AUTOSAR XML (schema 4-2-1)
package /VehicleProject
  system System
package /TP
  lin tp config LIN00: communication-cluster=LIN00
    tp address TA_0x0001: tp-address=1
    tp address TA_0x0003: tp-address=3
    tp address TA_0x007E: tp-address=126
    tp-connections:
      data-pdu=MasterReq_Tp_oLIN00, lin-tp-n-sdu=MasterReq_oLIN00, multicast=TA_0x007E, receiver=[TN_0x0001_SRU3, TN_0x0003_LRU1], transmitter=TN_Master
      data-pdu=SlaveResp_Tp_oLIN00, flow-control=MasterReq_Tp_oLIN00, lin-tp-n-sdu=SlaveResp_SRU3_oLIN00, receiver=TN_Master, transmitter=TN_0x0001_SRU3
      data-pdu=SlaveResp_Tp_oLIN00, flow-control=MasterReq_Tp_oLIN00, lin-tp-n-sdu=SlaveResp_LRU1_oLIN00, receiver=TN_Master, transmitter=TN_0x0003_LRU1
      data-pdu=MasterReq_Tp_oLIN00, flow-control=SlaveResp_Tp_oLIN00, lin-tp-n-sdu=MasterReq_SRU3_oLIN00, receiver=TN_0x0001_SRU3, transmitter=TN_Master
      data-pdu=MasterReq_Tp_oLIN00, flow-control=SlaveResp_Tp_oLIN00, lin-tp-n-sdu=MasterReq_LRU1_oLIN00, receiver=TN_0x0003_LRU1, transmitter=TN_Master
    lin tp node TN_0x0001_SRU3: tp-address=TA_0x0001
    lin tp node TN_0x0003_LRU1: tp-address=TA_0x0003
    lin tp node TN_Master: connector=CN_LIN00
package /Cluster
  can cluster CAN00: protocol-name=CAN  # 180319-lh1-EP21P2P_P2P_CAN2-V09
    can physical channel CHNL: comm-connectors=CN_CAN00
      frame DIAG_DTCInfo_P2P_oCAN00: id 0x79E, from P2P, frame-length=7, can-addressing-mode=STANDARD
        pdu DIAG_DTCInfo_P2P_oCAN00: length=7, unused-bit-pattern=0
          signal DTCInfomationP2PHSC2_oDIAG_DTCInfo_P2P_oCAN00: start 0, 56 bit, opaque, init-value=7 x 0, base-type=uint8_7_iso_8859_1, compu-method=CM_DTCInfomationP2PHSC2, transfer-property=PENDING  # DTC Infomation of P2P The length of DTC information signal is 7 bytes. Byte 0 is MSB (most significant byte), and Byte 6 is LSB (least significant byte). For each byte, Bit 7 is msb (most significant bit), and Bit 0 is lsb (least significant bit). Byte 0: Bit (7-4): DTC Serious Level Bit (3-0): Reserved Byte 1: Bit (7-0): Reserved Byte 2: Bit (7-0): DTCHighByte Byte 3: Bit (7-0): DTCLowByte Byte 4: Bit (7-0): DTCFailureTypeByte Byte 5: Bit 7: warningIndicatorRequested Bit 6: testNotCompletedThisOperationCycle Bit 5: testFailedSinceLastClear Bit 4: testNotCompletedSinceLastClear Bit 3: confirmedDTC Bit 2: pendingDTC Bit 1: testFailedThisOperationCycle Bit 0: testFailed Byte 6: Bit (7-0): DTC Type For more detail, please refer to SMTC 2 800 004.
      frame DIAG_FuncReq_HSC2_oCAN00: id 0x7DF, to P2P, frame-length=8, can-addressing-mode=STANDARD
        pdu DIAG_FuncReq_HSC2_oCAN00: length=8, unused-bit-pattern=0
          signal DiagnosticFuncAddrReq_h2_oDIAG_FuncReq_HSC2_oCAN00: start 0, 64 bit, opaque, init-value=8 x 0, base-type=uint8_8_iso_8859_1, compu-method=CM_DiagnosticFuncAddrReq_h2, transfer-property=PENDING, to P2P  # Diagnostic functional address request
      frame DIAG_PhysReq_P2P_oCAN00: id 0x736, to P2P, frame-length=8, can-addressing-mode=STANDARD
        pdu DIAG_PhysReq_P2P_oCAN00: length=8, unused-bit-pattern=0
          signal DiagnosticReqP2P_h2_oDIAG_PhysReq_P2P_oCAN00: start 0, 64 bit, opaque, init-value=8 x 0, base-type=uint8_8_iso_8859_1, compu-method=CM_DiagnosticReqP2P_h2, transfer-property=PENDING, to P2P  # Diagnostic request to P2P
      frame DIAG_PhysResp_P2P_oCAN00: id 0x73E, from P2P, frame-length=8, can-addressing-mode=STANDARD
        pdu DIAG_PhysResp_P2P_oCAN00: length=8, unused-bit-pattern=0
          signal DiagnosticRespP2P_oDIAG_PhysResp_P2P_oCAN00: start 0, 64 bit, opaque, init-value=8 x 0, base-type=uint8_8_iso_8859_1, compu-method=CM_DiagnosticRespP2P, transfer-property=PENDING  # Diagnostic response from P2P
      frame EHBS_HSC2_FrP00_oCAN00: id 0x1B6, to P2P, frame-length=8, can-addressing-mode=STANDARD
        pdu EHBS_HSC2_FrP00_oCAN00: length=8, transmission-mode-false-timing=cyclic-timing=time-period=0, transmission-mode-true-timing=cyclic-timing=time-period=0, unused-bit-pattern=0
          signal BrkPdlAppdHSC2_oEHBS_HSC2_FrP00_oCAN00: start 10, 1 bit, big-endian, init-value=0, base-type=boolean, compu-method=CM_BrkPdlAppdHSC2, transfer-property=PENDING, to P2P
          signal HydBstrCmpstnReqHSC2_oEHBS_HSC2_FrP00_oCAN00: start 54, 1 bit, big-endian, init-value=0, base-type=boolean, compu-method=CM_HydBstrCmpstnReqHSC2, transfer-property=PENDING, to P2P
      frame EPB_HSC2_FrP00_oCAN00: id 0x230, to P2P, frame-length=8, can-addressing-mode=STANDARD
        pdu EPB_HSC2_FrP00_oCAN00: length=8, transmission-mode-false-timing=cyclic-timing=time-period=0, transmission-mode-true-timing=cyclic-timing=time-period=0, unused-bit-pattern=0
          signal EPBSwStsVHSC2_oEPB_HSC2_FrP00_oCAN00: start 5, 1 bit, big-endian, init-value=0, base-type=boolean, compu-method=CM_EPBSwStsVHSC2, transfer-property=PENDING, to P2P
          signal EPBSwStsHSC2_oEPB_HSC2_FrP00_oCAN00: start 7, 2 bit, big-endian, init-value=0, base-type=uint8, compu-method=CM_EPBSwStsHSC2, transfer-property=PENDING, to P2P
      frame EPB_HSC2_FrP01_oCAN00: id 0x22A, to P2P, frame-length=2, can-addressing-mode=STANDARD
        pdu EPB_HSC2_FrP01_oCAN00: length=2, transmission-mode-false-timing=cyclic-timing=time-period=0, transmission-mode-true-timing=cyclic-timing=time-period=0, unused-bit-pattern=0
          signal EPBAvlblyStsPVHSC2_oEPB_HSC2_FrP01_oCAN00: start 2, 3 bit, big-endian, init-value=0, base-type=uint8, compu-method=CM_EPBAvlblyStsPVHSC2, transfer-property=PENDING, to P2P
          signal EPBAvlblyStsHSC2_oEPB_HSC2_FrP01_oCAN00: start 5, 3 bit, big-endian, init-value=0, base-type=uint8, compu-method=CM_EPBAvlblyStsHSC2, transfer-property=PENDING, to P2P
          signal EPBAppcnStsPVHSC2_oEPB_HSC2_FrP01_oCAN00: start 13, 2 bit, big-endian, init-value=0, base-type=uint8, compu-method=CM_EPBAppcnStsPVHSC2, transfer-property=PENDING, to P2P  # Electric Park Brake Application Status Protection Value
          signal EPBAppcnStsHSC2_oEPB_HSC2_FrP01_oCAN00: start 15, 2 bit, big-endian, init-value=0, base-type=uint8, compu-method=CM_EPBAppcnStsHSC2, transfer-property=PENDING, to P2P  # Electric Park Brake Application Status
      frame EPS_HSC2_FrP02_oCAN00: id 0x1B1, to P2P, frame-length=4, can-addressing-mode=STANDARD
        pdu EPS_HSC2_FrP02_oCAN00: length=4, transmission-mode-false-timing=cyclic-timing=time-period=0, transmission-mode-true-timing=cyclic-timing=time-period=0, unused-bit-pattern=0
          signal EPSAPAStsHSC2_oEPS_HSC2_FrP02_oCAN00: start 4, 4 bit, big-endian, init-value=7, base-type=uint8, compu-method=CM_EPSAPAStsHSC2, unit=U_Reserve, transfer-property=PENDING, to P2P
          signal EPSAPAInhHSC2_oEPS_HSC2_FrP02_oCAN00: start 15, 8 bit, big-endian, init-value=0, base-type=uint8, compu-method=CM_EPSAPAInhHSC2, transfer-property=PENDING, to P2P
          signal EPSAPAAlvRCHSC2_oEPS_HSC2_FrP02_oCAN00: start 23, 8 bit, big-endian, init-value=0, base-type=uint8, compu-method=CM_EPSAPAAlvRCHSC2, transfer-property=PENDING, to P2P
          signal EPSAPAChksmHSC2_oEPS_HSC2_FrP02_oCAN00: start 31, 8 bit, big-endian, init-value=0, base-type=uint8, compu-method=CM_EPSAPAChksmHSC2, transfer-property=PENDING, to P2P
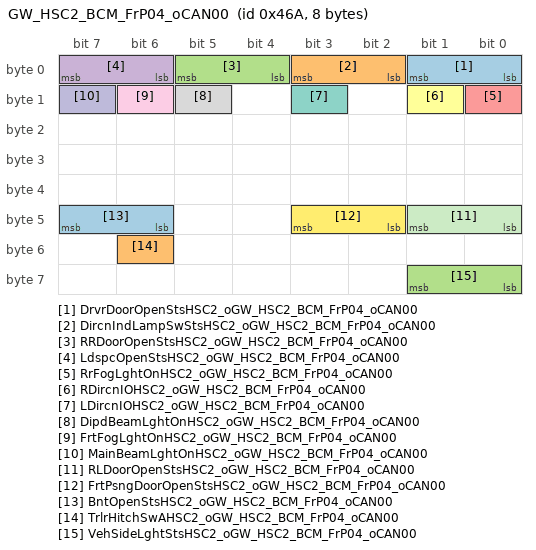
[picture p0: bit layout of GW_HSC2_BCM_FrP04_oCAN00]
      frame GW_HSC2_BCM_FrP04_oCAN00: id 0x46A, to P2P, frame-length=8, can-addressing-mode=STANDARD
        pdu GW_HSC2_BCM_FrP04_oCAN00: length=8, transmission-mode-false-timing=cyclic-timing=time-period=0, transmission-mode-true-timing=cyclic-timing=time-period=0, unused-bit-pattern=0
          signal DrvrDoorOpenStsHSC2_oGW_HSC2_BCM_FrP04_oCAN00: start 1, 2 bit, big-endian, init-value=0, base-type=uint8, compu-method=CM_DrvrDoorOpenStsHSC2, transfer-property=PENDING, to P2P
          signal DircnIndLampSwStsHSC2_oGW_HSC2_BCM_FrP04_oCAN00: start 3, 2 bit, big-endian, init-value=0, base-type=uint8, compu-method=CM_DircnIndLampSwStsHSC2, transfer-property=PENDING, to P2P
          signal RRDoorOpenStsHSC2_oGW_HSC2_BCM_FrP04_oCAN00: start 5, 2 bit, big-endian, init-value=0, base-type=uint8, compu-method=CM_RRDoorOpenStsHSC2, transfer-property=PENDING, to P2P  # Rear Right Door Open Status
          signal LdspcOpenStsHSC2_oGW_HSC2_BCM_FrP04_oCAN00: start 7, 2 bit, big-endian, init-value=0, base-type=uint8, compu-method=CM_LdspcOpenStsHSC2, transfer-property=PENDING, to P2P
          signal RrFogLghtOnHSC2_oGW_HSC2_BCM_FrP04_oCAN00: start 8, 1 bit, big-endian, init-value=0, base-type=boolean, compu-method=CM_RrFogLghtOnHSC2, transfer-property=PENDING, to P2P
          signal RDircnIOHSC2_oGW_HSC2_BCM_FrP04_oCAN00: start 9, 1 bit, big-endian, init-value=0, base-type=boolean, compu-method=CM_RDircnIOHSC2, transfer-property=PENDING, to P2P
          signal LDircnIOHSC2_oGW_HSC2_BCM_FrP04_oCAN00: start 11, 1 bit, big-endian, init-value=0, base-type=boolean, compu-method=CM_LDircnIOHSC2, transfer-property=PENDING, to P2P
          signal DipdBeamLghtOnHSC2_oGW_HSC2_BCM_FrP04_oCAN00: start 13, 1 bit, big-endian, init-value=0, base-type=boolean, compu-method=CM_DipdBeamLghtOnHSC2, transfer-property=PENDING, to P2P
          signal FrtFogLghtOnHSC2_oGW_HSC2_BCM_FrP04_oCAN00: start 14, 1 bit, big-endian, init-value=0, base-type=boolean, compu-method=CM_FrtFogLghtOnHSC2, transfer-property=PENDING, to P2P
          signal MainBeamLghtOnHSC2_oGW_HSC2_BCM_FrP04_oCAN00: start 15, 1 bit, big-endian, init-value=0, base-type=boolean, compu-method=CM_MainBeamLghtOnHSC2, transfer-property=PENDING, to P2P
          signal RLDoorOpenStsHSC2_oGW_HSC2_BCM_FrP04_oCAN00: start 41, 2 bit, big-endian, init-value=0, base-type=uint8, compu-method=CM_RLDoorOpenStsHSC2, transfer-property=PENDING, to P2P
          signal FrtPsngDoorOpenStsHSC2_oGW_HSC2_BCM_FrP04_oCAN00: start 43, 2 bit, big-endian, init-value=0, base-type=uint8, compu-method=CM_FrtPsngDoorOpenStsHSC2, transfer-property=PENDING, to P2P
          signal BntOpenStsHSC2_oGW_HSC2_BCM_FrP04_oCAN00: start 47, 2 bit, big-endian, init-value=0, base-type=uint8, compu-method=CM_BntOpenStsHSC2, transfer-property=PENDING, to P2P
          signal TrlrHitchSwAHSC2_oGW_HSC2_BCM_FrP04_oCAN00: start 54, 1 bit, big-endian, init-value=0, base-type=boolean, compu-method=CM_TrlrHitchSwAHSC2, transfer-property=PENDING, to P2P
          signal VehSideLghtStsHSC2_oGW_HSC2_BCM_FrP04_oCAN00: start 57, 2 bit, big-endian, init-value=0, base-type=uint8, compu-method=CM_VehSideLghtStsHSC2, transfer-property=PENDING, to P2P
      frame GW_HSC2_BCM_FrP06_oCAN00: id 0x21C, to P2P, frame-length=8, can-addressing-mode=STANDARD
        pdu GW_HSC2_BCM_FrP06_oCAN00: length=8, transmission-mode-false-timing=cyclic-timing=time-period=0, transmission-mode-true-timing=cyclic-timing=time-period=0, unused-bit-pattern=0
          signal BCMSSBFltStsHSC2_oGW_HSC2_BCM_FrP06_oCAN00: start 7, 3 bit, big-endian, init-value=0, base-type=uint8, compu-method=CM_BCMSSBFltStsHSC2, transfer-property=PENDING, to P2P
          signal DayTimeRunningLampOnHSC2_oGW_HSC2_BCM_FrP06_oCAN00: start 29, 1 bit, big-endian, init-value=0, base-type=boolean, compu-method=CM_DayTimeRunningLampOnHSC2, transfer-property=PENDING, to P2P
      frame GW_HSC2_BCM_FrP07_oCAN00: id 0x1F2, to P2P, frame-length=2, can-addressing-mode=STANDARD
        pdu GW_HSC2_BCM_FrP07_oCAN00: length=2, transmission-mode-false-timing=cyclic-timing=time-period=0, transmission-mode-true-timing=cyclic-timing=time-period=0, unused-bit-pattern=0
          signal BCMSSBAHSC2_oGW_HSC2_BCM_FrP07_oCAN00: start 0, 1 bit, big-endian, init-value=0, base-type=boolean, compu-method=CM_BCMSSBAHSC2, transfer-property=PENDING, to P2P
          signal BCMSSBAVHSC2_oGW_HSC2_BCM_FrP07_oCAN00: start 1, 1 bit, big-endian, init-value=0, base-type=boolean, compu-method=CM_BCMSSBAVHSC2, transfer-property=PENDING, to P2P
          signal PwrMdAutoCtrlAvlblHSC2_oGW_HSC2_BCM_FrP07_oCAN00: start 2, 1 bit, big-endian, init-value=0, base-type=boolean, compu-method=CM_PwrMdAutoCtrlAvlblHSC2, transfer-property=PENDING, to P2P
          signal SysBPMHSC2_oGW_HSC2_BCM_FrP07_oCAN00: start 5, 2 bit, big-endian, init-value=0, base-type=uint8, compu-method=CM_SysBPMHSC2, transfer-property=PENDING, to P2P
          signal SysBPMEnbdHSC2_oGW_HSC2_BCM_FrP07_oCAN00: start 6, 1 bit, big-endian, init-value=0, base-type=boolean, compu-method=CM_SysBPMEnbdHSC2, transfer-property=PENDING, to P2P
      frame GW_HSC2_BCM_FrS16_oCAN00: id 0x603, to P2P, frame-length=8, can-addressing-mode=STANDARD
        pdu GW_HSC2_BCM_FrS16_oCAN00: length=8, unused-bit-pattern=0
          signal BCMToIECURmtCtrlPotclHSC2_oGW_HSC2_BCM_FrS16_oCAN00: start 0, 64 bit, opaque, init-value=8 x 0, base-type=uint8_8_iso_8859_1, compu-method=CM_BCMToIECURmtCtrlPotclHSC2, transfer-property=PENDING, to P2P
      frame GW_HSC2_ECM_FrP04_oCAN00: id 0x194, to P2P, frame-length=8, can-addressing-mode=STANDARD
        pdu GW_HSC2_ECM_FrP04_oCAN00: length=8, transmission-mode-false-timing=cyclic-timing=time-period=0, transmission-mode-true-timing=cyclic-timing=time-period=0, unused-bit-pattern=0
          signal TrShftLvrPos_h1HSC2_oGW_HSC2_ECM_FrP04_oCAN00: start 27, 4 bit, big-endian, init-value=0, base-type=uint8, compu-method=CM_TrShftLvrPos_h1HSC2, transfer-property=PENDING, to P2P
          signal TrShftLvrPosV_h1HSC2_oGW_HSC2_ECM_FrP04_oCAN00: start 28, 1 bit, big-endian, init-value=0, base-type=boolean, compu-method=CM_TrShftLvrPosV_h1HSC2, transfer-property=PENDING, to P2P
      frame GW_HSC2_FICM_FrP02_oCAN00: id 0x376, to P2P, frame-length=8, can-addressing-mode=STANDARD
        pdu GW_HSC2_FICM_FrP02_oCAN00: length=8, transmission-mode-false-timing=cyclic-timing=time-period=0, transmission-mode-true-timing=cyclic-timing=time-period=0, unused-bit-pattern=0
          signal DrvrSelAPAParkngMdHSC2_oGW_HSC2_FICM_FrP02_oCAN00: start 10, 3 bit, big-endian, init-value=0, base-type=uint8, compu-method=CM_DrvrSelAPAParkngMdHSC2, transfer-property=PENDING, to P2P  # Driver Select Advanced Park Assist Parking Mode
          signal DrvrSelAPASlotBearngHSC2_oGW_HSC2_FICM_FrP02_oCAN00: start 12, 2 bit, big-endian, init-value=0, base-type=uint8, compu-method=CM_DrvrSelAPASlotBearngHSC2, transfer-property=PENDING, to P2P
          signal RstrFctryDeftsReqHSC2_oGW_HSC2_FICM_FrP02_oCAN00: start 56, 1 bit, big-endian, init-value=0, base-type=boolean, compu-method=CM_RstrFctryDeftsReqHSC2, transfer-property=PENDING, to P2P
      frame GW_HSC2_FICM_FrP08_oCAN00: id 0x2F6, to P2P, frame-length=8, can-addressing-mode=STANDARD
        pdu GW_HSC2_FICM_FrP08_oCAN00: length=8, transmission-mode-false-timing=cyclic-timing=time-period=0, transmission-mode-true-timing=cyclic-timing=time-period=0, unused-bit-pattern=0
          signal APASwReqHSC2_oGW_HSC2_FICM_FrP08_oCAN00: start 59, 2 bit, big-endian, init-value=0, base-type=uint8, compu-method=CM_APASwReqHSC2, transfer-property=PENDING, to P2P
          signal PDCSwReqHSC2_oGW_HSC2_FICM_FrP08_oCAN00: start 61, 2 bit, big-endian, init-value=0, base-type=uint8, compu-method=CM_PDCSwReqHSC2, transfer-property=PENDING, to P2P
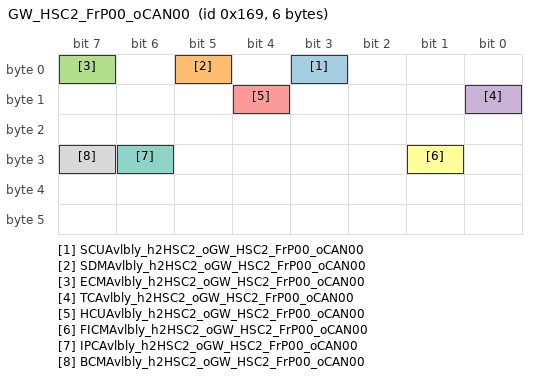
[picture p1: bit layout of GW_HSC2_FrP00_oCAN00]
      frame GW_HSC2_FrP00_oCAN00: id 0x169, to P2P, frame-length=6, can-addressing-mode=STANDARD
        pdu GW_HSC2_FrP00_oCAN00: length=6, transmission-mode-false-timing=cyclic-timing=time-period=0, transmission-mode-true-timing=cyclic-timing=time-period=0, unused-bit-pattern=0
          signal SCUAvlbly_h2HSC2_oGW_HSC2_FrP00_oCAN00: start 3, 1 bit, big-endian, init-value=0, base-type=boolean, compu-method=CM_SCUAvlbly_h2HSC2, transfer-property=PENDING, to P2P
          signal SDMAvlbly_h2HSC2_oGW_HSC2_FrP00_oCAN00: start 5, 1 bit, big-endian, init-value=0, base-type=boolean, compu-method=CM_SDMAvlbly_h2HSC2, transfer-property=PENDING, to P2P
          signal ECMAvlbly_h2HSC2_oGW_HSC2_FrP00_oCAN00: start 7, 1 bit, big-endian, init-value=0, base-type=boolean, compu-method=CM_ECMAvlbly_h2HSC2, transfer-property=PENDING, to P2P
          signal TCAvlbly_h2HSC2_oGW_HSC2_FrP00_oCAN00: start 8, 1 bit, big-endian, init-value=0, base-type=boolean, compu-method=CM_TCAvlbly_h2HSC2, transfer-property=PENDING, to P2P  # TC Available Detect if specific ECU is available according to node missing strategy by gateway ECU.
          signal HCUAvlbly_h2HSC2_oGW_HSC2_FrP00_oCAN00: start 12, 1 bit, big-endian, init-value=0, base-type=boolean, compu-method=CM_HCUAvlbly_h2HSC2, transfer-property=PENDING, to P2P  # HCU Available Detect if specific ECU is available according to node missing strategy by gateway ECU.
          signal FICMAvlbly_h2HSC2_oGW_HSC2_FrP00_oCAN00: start 25, 1 bit, big-endian, init-value=0, base-type=boolean, compu-method=CM_FICMAvlbly_h2HSC2, transfer-property=PENDING, to P2P
          signal IPCAvlbly_h2HSC2_oGW_HSC2_FrP00_oCAN00: start 30, 1 bit, big-endian, init-value=0, base-type=boolean, compu-method=CM_IPCAvlbly_h2HSC2, transfer-property=PENDING, to P2P
          signal BCMAvlbly_h2HSC2_oGW_HSC2_FrP00_oCAN00: start 31, 1 bit, big-endian, init-value=0, base-type=boolean, compu-method=CM_BCMAvlbly_h2HSC2, transfer-property=PENDING, to P2P
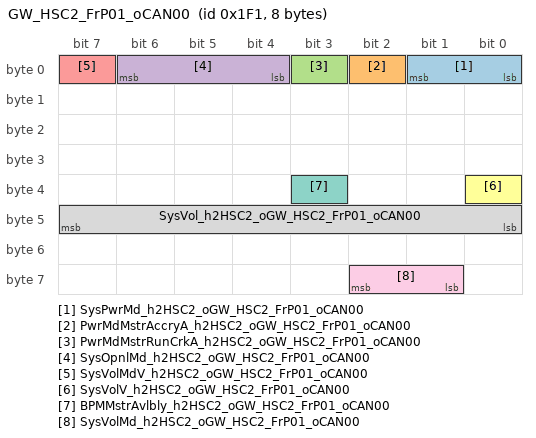
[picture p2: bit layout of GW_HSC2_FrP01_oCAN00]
      frame GW_HSC2_FrP01_oCAN00: id 0x1F1, to P2P, frame-length=8, can-addressing-mode=STANDARD
        pdu GW_HSC2_FrP01_oCAN00: length=8, transmission-mode-false-timing=cyclic-timing=time-period=0, transmission-mode-true-timing=cyclic-timing=time-period=0, unused-bit-pattern=0
          signal SysPwrMd_h2HSC2_oGW_HSC2_FrP01_oCAN00: start 1, 2 bit, big-endian, init-value=0, base-type=uint8, compu-method=CM_SysPwrMd_h2HSC2, transfer-property=PENDING, to P2P
          signal PwrMdMstrAccryA_h2HSC2_oGW_HSC2_FrP01_oCAN00: start 2, 1 bit, big-endian, init-value=0, base-type=boolean, compu-method=CM_PwrMdMstrAccryA_h2HSC2, transfer-property=PENDING, to P2P
          signal PwrMdMstrRunCrkA_h2HSC2_oGW_HSC2_FrP01_oCAN00: start 3, 1 bit, big-endian, init-value=0, base-type=boolean, compu-method=CM_PwrMdMstrRunCrkA_h2HSC2, transfer-property=PENDING, to P2P
          signal SysOpnlMd_h2HSC2_oGW_HSC2_FrP01_oCAN00: start 6, 3 bit, big-endian, init-value=0, base-type=uint8, compu-method=CM_SysOpnlMd_h2HSC2, transfer-property=PENDING, to P2P
          signal SysVolMdV_h2HSC2_oGW_HSC2_FrP01_oCAN00: start 7, 1 bit, big-endian, init-value=0, base-type=boolean, compu-method=CM_SysVolMdV_h2HSC2, transfer-property=PENDING, to P2P
          signal SysVolV_h2HSC2_oGW_HSC2_FrP01_oCAN00: start 32, 1 bit, big-endian, init-value=0, base-type=boolean, compu-method=CM_SysVolV_h2HSC2, transfer-property=PENDING, to P2P
          signal BPMMstrAvlbly_h2HSC2_oGW_HSC2_FrP01_oCAN00: start 35, 1 bit, big-endian, init-value=0, base-type=boolean, compu-method=CM_BPMMstrAvlbly_h2HSC2, transfer-property=PENDING, to P2P
          signal SysVol_h2HSC2_oGW_HSC2_FrP01_oCAN00: start 47, 8 bit, big-endian, init-value=0, base-type=uint8, compu-method=CM_SysVol_h2HSC2, unit=U_V, transfer-property=PENDING, to P2P
          signal SysVolMd_h2HSC2_oGW_HSC2_FrP01_oCAN00: start 58, 2 bit, big-endian, init-value=0, base-type=uint8, compu-method=CM_SysVolMd_h2HSC2, transfer-property=PENDING, to P2P
      frame GW_HSC2_FrP08_oCAN00: id 0x540, to P2P, frame-length=8, can-addressing-mode=STANDARD
        pdu GW_HSC2_FrP08_oCAN00: length=8, transmission-mode-false-timing=cyclic-timing=time-period=0, transmission-mode-true-timing=cyclic-timing=time-period=0, unused-bit-pattern=0
          signal VehOdo_h2HSC2_oGW_HSC2_FrP08_oCAN00: start 7, 24 bit, big-endian, init-value=0, base-type=uint32, compu-method=CM_VehOdo_h2HSC2, transfer-property=PENDING, to P2P
          signal VehOdoV_h2HSC2_oGW_HSC2_FrP08_oCAN00: start 31, 1 bit, big-endian, init-value=0, base-type=boolean, compu-method=CM_VehOdoV_h2HSC2, transfer-property=PENDING, to P2P
      frame GW_HSC2_FrP10_oCAN00: id 0x3F1, to P2P, frame-length=8, can-addressing-mode=STANDARD
        pdu GW_HSC2_FrP10_oCAN00: length=8, transmission-mode-false-timing=cyclic-timing=time-period=0, transmission-mode-true-timing=cyclic-timing=time-period=0, unused-bit-pattern=0
          signal OtsdAirTemCrValV_h2HSC2_oGW_HSC2_FrP10_oCAN00: start 48, 1 bit, big-endian, init-value=0, base-type=boolean, compu-method=CM_OtsdAirTemCrValV_h2HSC2, transfer-property=PENDING, to P2P
          signal OtsdAirTemCrValMsk_h2HSC2_oGW_HSC2_FrP10_oCAN00: start 51, 1 bit, big-endian, init-value=0, base-type=boolean, compu-method=CM_OtsdAirTemCrValMsk_h2HSC2, transfer-property=PENDING, to P2P
          signal OtsdAirTemCrVal_h2HSC2_oGW_HSC2_FrP10_oCAN00: start 63, 8 bit, big-endian, init-value=0, base-type=uint8, compu-method=CM_OtsdAirTemCrVal_h2HSC2, unit=U_degC, transfer-property=PENDING, to P2P
      frame GW_HSC2_FrP13_oCAN00: id 0x1A9, to P2P, frame-length=8, can-addressing-mode=STANDARD
        pdu GW_HSC2_FrP13_oCAN00: length=8, transmission-mode-false-timing=cyclic-timing=time-period=0, transmission-mode-true-timing=cyclic-timing=time-period=0, unused-bit-pattern=0
          signal NRCDSts_h2HSC2_oGW_HSC2_FrP13_oCAN00: start 39, 2 bit, big-endian, init-value=0, base-type=uint8, compu-method=CM_NRCDSts_h2HSC2, transfer-property=PENDING, to P2P
          signal APACtrlAbotdRsnHSC2_oGW_HSC2_FrP13_oCAN00: start 47, 4 bit, big-endian, init-value=0, base-type=uint8, compu-method=CM_APACtrlAbotdRsnHSC2, transfer-property=PENDING, to P2P
      frame GW_HSC2_FrS00_oCAN00: id 0x6A3, to P2P, frame-length=8, can-addressing-mode=STANDARD
        pdu GW_HSC2_FrS00_oCAN00: length=8, unused-bit-pattern=0
          signal NRCDMstrChlg_h2HSC2_oGW_HSC2_FrS00_oCAN00: start 0, 64 bit, opaque, init-value=8 x 0, base-type=uint8_8_iso_8859_1, compu-method=CM_NRCDMstrChlg_h2HSC2, transfer-property=PENDING, to P2P
      frame GW_HSC2_HCU_FrP00_oCAN00: id 0xAF, to P2P, frame-length=8, can-addressing-mode=STANDARD
        pdu GW_HSC2_HCU_FrP00_oCAN00: length=8, transmission-mode-false-timing=cyclic-timing=time-period=0, transmission-mode-true-timing=cyclic-timing=time-period=0, unused-bit-pattern=0
          signal EPTAccelActuPosHSC2_oGW_HSC2_HCU_FrP00_oCAN00: start 7, 8 bit, big-endian, init-value=0, base-type=uint8, compu-method=CM_EPTAccelActuPosHSC2, unit=U_p, transfer-property=PENDING, to P2P
          signal EPTBrkPdlDscrtInptStsVHSC2_oGW_HSC2_HCU_FrP00_oCAN00: start 16, 1 bit, big-endian, init-value=1, base-type=boolean, compu-method=CM_EPTBrkPdlDscrtInptStsVHSC2, transfer-property=PENDING, to P2P  # Electric Powertrain Brake Pedal Discrete Input Status Validity
          signal EPTStCmdOn_h1HSC2_oGW_HSC2_HCU_FrP00_oCAN00: start 17, 1 bit, big-endian, init-value=0, base-type=boolean, compu-method=CM_EPTStCmdOn_h1HSC2, transfer-property=PENDING, to P2P
          signal EPTBrkPdlDscrtInptStsHSC2_oGW_HSC2_HCU_FrP00_oCAN00: start 31, 1 bit, big-endian, init-value=0, base-type=boolean, compu-method=CM_EPTBrkPdlDscrtInptStsHSC2, transfer-property=PENDING, to P2P
          signal EPTAccelActuPosVHSC2_oGW_HSC2_HCU_FrP00_oCAN00: start 43, 1 bit, big-endian, init-value=0, base-type=boolean, compu-method=CM_EPTAccelActuPosVHSC2, transfer-property=PENDING, to P2P
      frame GW_HSC2_HCU_FrP01_oCAN00: id 0x196, to P2P, frame-length=8, can-addressing-mode=STANDARD
        pdu GW_HSC2_HCU_FrP01_oCAN00: length=8, transmission-mode-false-timing=cyclic-timing=time-period=0, transmission-mode-true-timing=cyclic-timing=time-period=0, unused-bit-pattern=0
          signal EPTRdy_h1HSC2_oGW_HSC2_HCU_FrP01_oCAN00: start 38, 1 bit, big-endian, init-value=0, base-type=boolean, compu-method=CM_EPTRdy_h1HSC2, transfer-property=PENDING, to P2P
      frame GW_HSC2_HCU_FrP13_oCAN00: id 0x19C, to P2P, frame-length=8, can-addressing-mode=STANDARD
        pdu GW_HSC2_HCU_FrP13_oCAN00: length=8, transmission-mode-false-timing=cyclic-timing=time-period=0, transmission-mode-true-timing=cyclic-timing=time-period=0, unused-bit-pattern=0
          signal VCUNRCDAvlblHSC2_oGW_HSC2_HCU_FrP13_oCAN00: start 52, 1 bit, big-endian, init-value=0, base-type=boolean, compu-method=CM_VCUNRCDAvlblHSC2, transfer-property=PENDING, to P2P
          signal VCUAccReqStsHSC2_oGW_HSC2_HCU_FrP13_oCAN00: start 53, 1 bit, big-endian, init-value=0, base-type=boolean, compu-method=CM_VCUAccReqStsHSC2, transfer-property=PENDING, to P2P
          signal VCUAccReqValHSC2_oGW_HSC2_HCU_FrP13_oCAN00: start 63, 8 bit, big-endian, init-value=0, base-type=uint8, compu-method=CM_VCUAccReqValHSC2, transfer-property=PENDING, to P2P
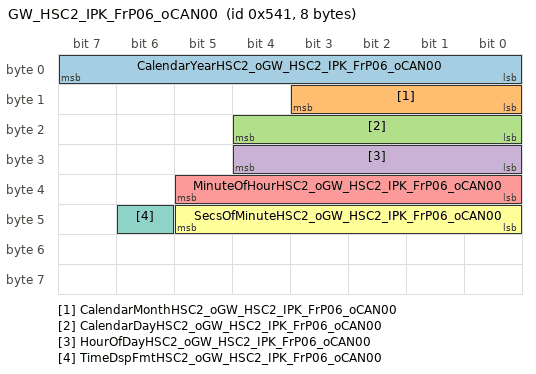
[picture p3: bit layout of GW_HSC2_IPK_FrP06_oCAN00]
      frame GW_HSC2_IPK_FrP06_oCAN00: id 0x541, to P2P, frame-length=8, can-addressing-mode=STANDARD
        pdu GW_HSC2_IPK_FrP06_oCAN00: length=8, transmission-mode-false-timing=cyclic-timing=time-period=0, transmission-mode-true-timing=cyclic-timing=time-period=0, unused-bit-pattern=0
          signal CalendarYearHSC2_oGW_HSC2_IPK_FrP06_oCAN00: start 7, 8 bit, big-endian, init-value=0, base-type=uint8, compu-method=CM_CalendarYearHSC2, unit=U_year, transfer-property=PENDING, to P2P
          signal CalendarMonthHSC2_oGW_HSC2_IPK_FrP06_oCAN00: start 11, 4 bit, big-endian, init-value=0, base-type=uint8, compu-method=CM_CalendarMonthHSC2, transfer-property=PENDING, to P2P
          signal CalendarDayHSC2_oGW_HSC2_IPK_FrP06_oCAN00: start 20, 5 bit, big-endian, init-value=0, base-type=uint8, compu-method=CM_CalendarDayHSC2, unit=U_days, transfer-property=PENDING, to P2P
          signal HourOfDayHSC2_oGW_HSC2_IPK_FrP06_oCAN00: start 28, 5 bit, big-endian, init-value=0, base-type=uint8, compu-method=CM_HourOfDayHSC2, transfer-property=PENDING, to P2P
          signal MinuteOfHourHSC2_oGW_HSC2_IPK_FrP06_oCAN00: start 37, 6 bit, big-endian, init-value=0, base-type=uint8, compu-method=CM_MinuteOfHourHSC2, transfer-property=PENDING, to P2P
          signal SecsOfMinuteHSC2_oGW_HSC2_IPK_FrP06_oCAN00: start 45, 6 bit, big-endian, init-value=0, base-type=uint8, compu-method=CM_SecsOfMinuteHSC2, transfer-property=PENDING, to P2P
          signal TimeDspFmtHSC2_oGW_HSC2_IPK_FrP06_oCAN00: start 46, 1 bit, big-endian, init-value=0, base-type=boolean, compu-method=CM_TimeDspFmtHSC2, transfer-property=PENDING, to P2P
      frame GW_HSC2_SCU_FrP00_oCAN00: id 0x9D, to P2P, frame-length=8, can-addressing-mode=STANDARD
        pdu GW_HSC2_SCU_FrP00_oCAN00: length=8, transmission-mode-false-timing=cyclic-timing=time-period=0, transmission-mode-true-timing=cyclic-timing=time-period=0, unused-bit-pattern=0
          signal SCUDrvrIntrvnAHSC2_oGW_HSC2_SCU_FrP00_oCAN00: start 2, 1 bit, big-endian, init-value=0, base-type=boolean, compu-method=CM_SCUDrvrIntrvnAHSC2, transfer-property=PENDING, to P2P
          signal SCUNRCDAvlblHSC2_oGW_HSC2_SCU_FrP00_oCAN00: start 3, 1 bit, big-endian, init-value=0, base-type=boolean, compu-method=CM_SCUNRCDAvlblHSC2, transfer-property=PENDING, to P2P
          signal SCUShifterPosRCHSC2_oGW_HSC2_SCU_FrP00_oCAN00: start 11, 4 bit, big-endian, init-value=0, base-type=uint8, compu-method=CM_SCUShifterPosRCHSC2, transfer-property=PENDING, to P2P
          signal SCUShifterLvrPosHSC2_oGW_HSC2_SCU_FrP00_oCAN00: start 23, 4 bit, big-endian, init-value=0, base-type=uint8, compu-method=CM_SCUShifterLvrPosHSC2, transfer-property=PENDING, to P2P
          signal SCUShifterPosInvsnHSC2_oGW_HSC2_SCU_FrP00_oCAN00: start 31, 4 bit, big-endian, init-value=15, base-type=uint8, compu-method=CM_SCUShifterPosInvsnHSC2, transfer-property=PENDING, to P2P
      frame GW_HSC2_SDM_FrP00_oCAN00: id 0x163, to P2P, frame-length=8, can-addressing-mode=STANDARD
        pdu GW_HSC2_SDM_FrP00_oCAN00: length=8, transmission-mode-false-timing=cyclic-timing=time-period=0, transmission-mode-true-timing=cyclic-timing=time-period=0, unused-bit-pattern=0
          signal AirbagDplInvsnHSC2_oGW_HSC2_SDM_FrP00_oCAN00: start 10, 1 bit, big-endian, init-value=1, base-type=boolean, compu-method=CM_AirbagDplInvsnHSC2, transfer-property=PENDING, to P2P  # Airbag Deployed Inversion
          signal AirbagDplHSC2_oGW_HSC2_SDM_FrP00_oCAN00: start 11, 1 bit, big-endian, init-value=0, base-type=boolean, compu-method=CM_AirbagDplHSC2, transfer-property=PENDING, to P2P
          signal DrvrSbltAtcHSC2_oGW_HSC2_SDM_FrP00_oCAN00: start 12, 1 bit, big-endian, init-value=0, base-type=boolean, compu-method=CM_DrvrSbltAtcHSC2, transfer-property=PENDING, to P2P
          signal DrvrSbltAtcVHSC2_oGW_HSC2_SDM_FrP00_oCAN00: start 13, 1 bit, big-endian, init-value=0, base-type=boolean, compu-method=CM_DrvrSbltAtcVHSC2, transfer-property=PENDING, to P2P
      frame P2P_DIAG_DTCInfo_APA_oCAN00: id 0x799, from P2P, frame-length=7, can-addressing-mode=STANDARD
        pdu P2P_DIAG_DTCInfo_APA_oCAN00: length=7, unused-bit-pattern=0
          signal DTCInfomationAPAHSC2_oP2P_DIAG_DTCInfo_APA_oCAN00: start 0, 56 bit, opaque, init-value=7 x 0, base-type=uint8_7_iso_8859_1, compu-method=CM_DTCInfomationAPAHSC2, transfer-property=PENDING  # DTC Infomation of APA The length of DTC information signal is 7 bytes. Byte 0 is MSB (most significant byte), and Byte 6 is LSB (least significant byte). For each byte, Bit 7 is msb (most significant bit), and Bit 0 is lsb (least significant bit). Byte 0: Bit (7-4): DTC Serious Level Bit (3-0): Reserved Byte 1: Bit (7-0): Reserved Byte 2: Bit (7-0): DTCHighByte Byte 3: Bit (7-0): DTCLowByte Byte 4: Bit (7-0): DTCFailureTypeByte Byte 5: Bit 7: warningIndicatorRequested Bit 6: testNotCompletedThisOperationCycle Bit 5: testFailedSinceLastClear Bit 4: testNotCompletedSinceLastClear Bit 3: confirmedDTC Bit 2: pendingDTC Bit 1: testFailedThisOperationCycle Bit 0: testFailed Byte 6: Bit (7-0): DTC Type For more detail, please refer to SMTC 2 800 004.
      frame P2P_HSC2_FrP00_oCAN00: id 0x1A8, from P2P, frame-length=6, can-addressing-mode=STANDARD
        pdu P2P_HSC2_FrP00_oCAN00: length=6, transmission-mode-false-timing=cyclic-timing=time-period=0, transmission-mode-true-timing=cyclic-timing=time-period=0, unused-bit-pattern=0
          signal APAToqReqValHSC2_oP2P_HSC2_FrP00_oCAN00: start 3, 12 bit, big-endian, init-value=0, base-type=uint16, compu-method=CM_APAToqReqValHSC2, unit=U_Nm, transfer-property=PENDING
          signal APAToqReqStsHSC2_oP2P_HSC2_FrP00_oCAN00: start 4, 1 bit, big-endian, init-value=0, base-type=boolean, compu-method=CM_APAToqReqStsHSC2, transfer-property=PENDING
          signal APAFHSC2_oP2P_HSC2_FrP00_oCAN00: start 5, 1 bit, big-endian, init-value=0, base-type=boolean, compu-method=CM_APAFHSC2, transfer-property=PENDING
          signal APACmdEPSStsHSC2_oP2P_HSC2_FrP00_oCAN00: start 7, 2 bit, big-endian, init-value=0, base-type=uint8, compu-method=CM_APACmdEPSStsHSC2, transfer-property=PENDING
          signal APATrgtEPSStrgWhlAngHSC2_oP2P_HSC2_FrP00_oCAN00: start 23, 16 bit, big-endian, init-value=0, base-type=uint16, compu-method=CM_APATrgtEPSStrgWhlAngHSC2, transfer-property=PENDING
          signal APAAlvRCHSC2_oP2P_HSC2_FrP00_oCAN00: start 39, 8 bit, big-endian, init-value=0, base-type=uint8, compu-method=CM_APAAlvRCHSC2, transfer-property=PENDING
          signal APAChksmHSC2_oP2P_HSC2_FrP00_oCAN00: start 47, 8 bit, big-endian, init-value=0, base-type=uint8, compu-method=CM_APAChksmHSC2, transfer-property=PENDING
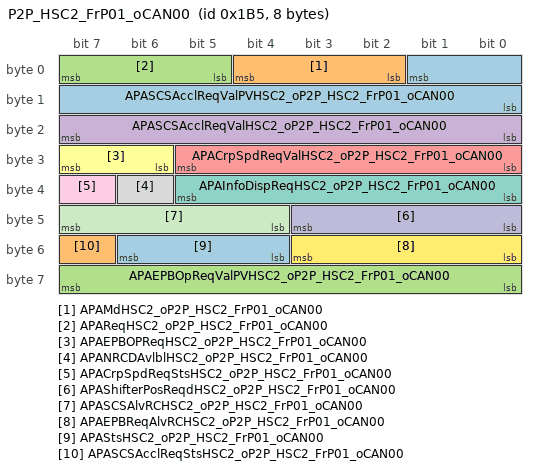
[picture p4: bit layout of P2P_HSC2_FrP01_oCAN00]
      frame P2P_HSC2_FrP01_oCAN00: id 0x1B5, from P2P, frame-length=8, can-addressing-mode=STANDARD
        pdu P2P_HSC2_FrP01_oCAN00: length=8, transmission-mode-false-timing=cyclic-timing=time-period=0, transmission-mode-true-timing=cyclic-timing=time-period=0, unused-bit-pattern=0
          signal APASCSAcclReqValPVHSC2_oP2P_HSC2_FrP01_oCAN00: start 1, 10 bit, big-endian, init-value=0, base-type=uint16, compu-method=CM_APASCSAcclReqValPVHSC2, transfer-property=PENDING
          signal APAMdHSC2_oP2P_HSC2_FrP01_oCAN00: start 4, 3 bit, big-endian, init-value=0, base-type=uint8, compu-method=CM_APAMdHSC2, transfer-property=PENDING
          signal APAReqHSC2_oP2P_HSC2_FrP01_oCAN00: start 7, 3 bit, big-endian, init-value=0, base-type=uint8, compu-method=CM_APAReqHSC2, transfer-property=PENDING
          signal APASCSAcclReqValHSC2_oP2P_HSC2_FrP01_oCAN00: start 23, 8 bit, big-endian, init-value=0, base-type=uint8, compu-method=CM_APASCSAcclReqValHSC2, unit=U_mYs2, transfer-property=PENDING
          signal APACrpSpdReqValHSC2_oP2P_HSC2_FrP01_oCAN00: start 29, 6 bit, big-endian, init-value=0, base-type=uint8, compu-method=CM_APACrpSpdReqValHSC2, unit=U_kmYh, transfer-property=PENDING
          signal APAEPBOPReqHSC2_oP2P_HSC2_FrP01_oCAN00: start 31, 2 bit, big-endian, init-value=0, base-type=uint8, compu-method=CM_APAEPBOPReqHSC2, transfer-property=PENDING
          signal APAInfoDispReqHSC2_oP2P_HSC2_FrP01_oCAN00: start 37, 6 bit, big-endian, init-value=0, base-type=uint8, compu-method=CM_APAInfoDispReqHSC2, transfer-property=PENDING
          signal APANRCDAvlblHSC2_oP2P_HSC2_FrP01_oCAN00: start 38, 1 bit, big-endian, init-value=0, base-type=boolean, compu-method=CM_APANRCDAvlblHSC2, transfer-property=PENDING  # Advanced Park Assist Near Range Control Drive Available
          signal APACrpSpdReqStsHSC2_oP2P_HSC2_FrP01_oCAN00: start 39, 1 bit, big-endian, init-value=0, base-type=boolean, compu-method=CM_APACrpSpdReqStsHSC2, transfer-property=PENDING
          signal APAShifterPosReqdHSC2_oP2P_HSC2_FrP01_oCAN00: start 43, 4 bit, big-endian, init-value=0, base-type=uint8, compu-method=CM_APAShifterPosReqdHSC2, transfer-property=PENDING
          signal APASCSAlvRCHSC2_oP2P_HSC2_FrP01_oCAN00: start 47, 4 bit, big-endian, init-value=0, base-type=uint8, compu-method=CM_APASCSAlvRCHSC2, transfer-property=PENDING
          signal APAEPBReqAlvRCHSC2_oP2P_HSC2_FrP01_oCAN00: start 51, 4 bit, big-endian, init-value=0, base-type=uint8, compu-method=CM_APAEPBReqAlvRCHSC2, transfer-property=PENDING
          signal APAStsHSC2_oP2P_HSC2_FrP01_oCAN00: start 54, 3 bit, big-endian, init-value=0, base-type=uint8, compu-method=CM_APAStsHSC2, transfer-property=PENDING
          signal APASCSAcclReqStsHSC2_oP2P_HSC2_FrP01_oCAN00: start 55, 1 bit, big-endian, init-value=0, base-type=boolean, compu-method=CM_APASCSAcclReqStsHSC2, transfer-property=PENDING
          signal APAEPBOpReqValPVHSC2_oP2P_HSC2_FrP01_oCAN00: start 63, 8 bit, big-endian, init-value=0, base-type=uint8, compu-method=CM_APAEPBOpReqValPVHSC2, transfer-property=PENDING
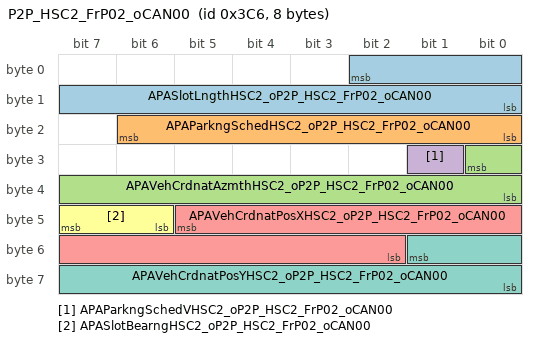
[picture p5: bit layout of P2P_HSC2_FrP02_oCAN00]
      frame P2P_HSC2_FrP02_oCAN00: id 0x3C6, from P2P, frame-length=8, can-addressing-mode=STANDARD
        pdu P2P_HSC2_FrP02_oCAN00: length=8, transmission-mode-false-timing=cyclic-timing=time-period=0, transmission-mode-true-timing=cyclic-timing=time-period=0, unused-bit-pattern=0
          signal APASlotLngthHSC2_oP2P_HSC2_FrP02_oCAN00: start 2, 11 bit, big-endian, init-value=0, base-type=uint16, compu-method=CM_APASlotLngthHSC2, unit=U_cm, transfer-property=PENDING  # Advanced Park Assist Slot Length
          signal APAParkngSchedHSC2_oP2P_HSC2_FrP02_oCAN00: start 22, 7 bit, big-endian, init-value=0, base-type=uint8, compu-method=CM_APAParkngSchedHSC2, transfer-property=PENDING  # Advanced Park Assist Parking Schedule
          signal APAVehCrdnatAzmthHSC2_oP2P_HSC2_FrP02_oCAN00: start 24, 9 bit, big-endian, init-value=0, base-type=uint16, compu-method=CM_APAVehCrdnatAzmthHSC2, transfer-property=PENDING  # Advanced Park Assist Vehicle Coordinate Azimuth
          signal APAParkngSchedVHSC2_oP2P_HSC2_FrP02_oCAN00: start 25, 1 bit, big-endian, init-value=0, base-type=boolean, compu-method=CM_APAParkngSchedVHSC2, transfer-property=PENDING  # Advanced Park Assist Parking Schedule Validit
          signal APAVehCrdnatPosXHSC2_oP2P_HSC2_FrP02_oCAN00: start 45, 12 bit, big-endian, init-value=0, base-type=uint16, compu-method=CM_APAVehCrdnatPosXHSC2, unit=U_cm, transfer-property=PENDING  # Advanced Park Assist Vehicle Coordinate Position X
          signal APASlotBearngHSC2_oP2P_HSC2_FrP02_oCAN00: start 47, 2 bit, big-endian, init-value=0, base-type=uint8, compu-method=CM_APASlotBearngHSC2, transfer-property=PENDING  # Advanced Park Assist Slot Bearing
          signal APAVehCrdnatPosYHSC2_oP2P_HSC2_FrP02_oCAN00: start 49, 10 bit, big-endian, init-value=0, base-type=uint16, compu-method=CM_APAVehCrdnatPosYHSC2, unit=U_cm, transfer-property=PENDING  # Advanced Park Assist Vehicle Coordinate Position Y
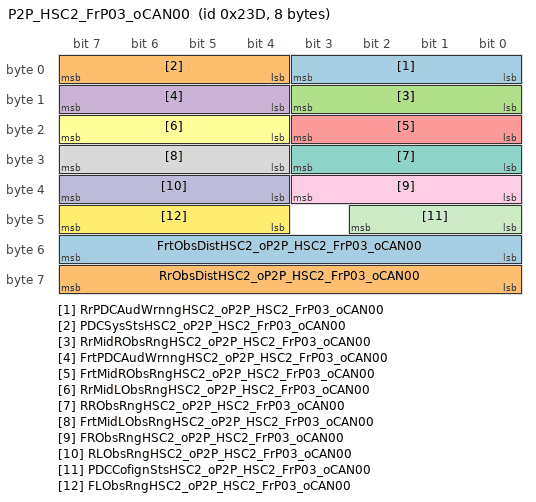
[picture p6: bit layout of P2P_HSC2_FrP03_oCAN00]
      frame P2P_HSC2_FrP03_oCAN00: id 0x23D, from P2P, frame-length=8, can-addressing-mode=STANDARD
        pdu P2P_HSC2_FrP03_oCAN00: length=8, transmission-mode-false-timing=cyclic-timing=time-period=0, transmission-mode-true-timing=cyclic-timing=time-period=0, unused-bit-pattern=0
          signal RrPDCAudWrnngHSC2_oP2P_HSC2_FrP03_oCAN00: start 3, 4 bit, big-endian, init-value=0, base-type=uint8, compu-method=CM_RrPDCAudWrnngHSC2, transfer-property=PENDING
          signal PDCSysStsHSC2_oP2P_HSC2_FrP03_oCAN00: start 7, 4 bit, big-endian, init-value=0, base-type=uint8, compu-method=CM_PDCSysStsHSC2, transfer-property=PENDING
          signal RrMidRObsRngHSC2_oP2P_HSC2_FrP03_oCAN00: start 11, 4 bit, big-endian, init-value=0, base-type=uint8, compu-method=CM_RrMidRObsRngHSC2, transfer-property=PENDING
          signal FrtPDCAudWrnngHSC2_oP2P_HSC2_FrP03_oCAN00: start 15, 4 bit, big-endian, init-value=0, base-type=uint8, compu-method=CM_FrtPDCAudWrnngHSC2, transfer-property=PENDING
          signal FrtMidRObsRngHSC2_oP2P_HSC2_FrP03_oCAN00: start 19, 4 bit, big-endian, init-value=0, base-type=uint8, compu-method=CM_FrtMidRObsRngHSC2, transfer-property=PENDING
          signal RrMidLObsRngHSC2_oP2P_HSC2_FrP03_oCAN00: start 23, 4 bit, big-endian, init-value=0, base-type=uint8, compu-method=CM_RrMidLObsRngHSC2, transfer-property=PENDING
          signal RRObsRngHSC2_oP2P_HSC2_FrP03_oCAN00: start 27, 4 bit, big-endian, init-value=0, base-type=uint8, compu-method=CM_RRObsRngHSC2, transfer-property=PENDING
          signal FrtMidLObsRngHSC2_oP2P_HSC2_FrP03_oCAN00: start 31, 4 bit, big-endian, init-value=0, base-type=uint8, compu-method=CM_FrtMidLObsRngHSC2, transfer-property=PENDING
          signal FRObsRngHSC2_oP2P_HSC2_FrP03_oCAN00: start 35, 4 bit, big-endian, init-value=0, base-type=uint8, compu-method=CM_FRObsRngHSC2, transfer-property=PENDING
          signal RLObsRngHSC2_oP2P_HSC2_FrP03_oCAN00: start 39, 4 bit, big-endian, init-value=0, base-type=uint8, compu-method=CM_RLObsRngHSC2, transfer-property=PENDING
          signal PDCCofignStsHSC2_oP2P_HSC2_FrP03_oCAN00: start 42, 3 bit, big-endian, init-value=1, base-type=uint8, compu-method=CM_PDCCofignStsHSC2, transfer-property=PENDING
          signal FLObsRngHSC2_oP2P_HSC2_FrP03_oCAN00: start 47, 4 bit, big-endian, init-value=0, base-type=uint8, compu-method=CM_FLObsRngHSC2, transfer-property=PENDING
          signal FrtObsDistHSC2_oP2P_HSC2_FrP03_oCAN00: start 55, 8 bit, big-endian, init-value=0, base-type=uint8, compu-method=CM_FrtObsDistHSC2, unit=U_cm, transfer-property=PENDING
          signal RrObsDistHSC2_oP2P_HSC2_FrP03_oCAN00: start 63, 8 bit, big-endian, init-value=0, base-type=uint8, compu-method=CM_RrObsDistHSC2, transfer-property=PENDING
      frame P2P_HSC2_FrP04_oCAN00: id 0x237, from P2P, frame-length=8, can-addressing-mode=STANDARD
        pdu P2P_HSC2_FrP04_oCAN00: length=8, transmission-mode-false-timing=cyclic-timing=time-period=0, transmission-mode-true-timing=cyclic-timing=time-period=0, unused-bit-pattern=0
          signal RRSideObsDistHSC2_oP2P_HSC2_FrP04_oCAN00: start 0, 9 bit, big-endian, init-value=0, base-type=uint16, compu-method=CM_RRSideObsDistHSC2, transfer-property=PENDING
          signal RLSideObsDistHSC2_oP2P_HSC2_FrP04_oCAN00: start 16, 9 bit, big-endian, init-value=0, base-type=uint16, compu-method=CM_RLSideObsDistHSC2, transfer-property=PENDING
          signal FRSideObsDistHSC2_oP2P_HSC2_FrP04_oCAN00: start 32, 9 bit, big-endian, init-value=0, base-type=uint16, compu-method=CM_FRSideObsDistHSC2, transfer-property=PENDING
          signal FLSideObsDistHSC2_oP2P_HSC2_FrP04_oCAN00: start 48, 9 bit, big-endian, init-value=0, base-type=uint16, compu-method=CM_FLSideObsDistHSC2, transfer-property=PENDING
      frame P2P_HSC2_FrS01_oCAN00: id 0x602, from P2P, frame-length=8, can-addressing-mode=STANDARD
        pdu P2P_HSC2_FrS01_oCAN00: length=8, unused-bit-pattern=0
          signal IECUToBCMRmtCtrlPotclHSC2_oP2P_HSC2_FrS01_oCAN00: start 0, 64 bit, opaque, init-value=8 x 0, base-type=uint8_8_iso_8859_1, compu-method=CM_IECUToBCMRmtCtrlPotclHSC2, transfer-property=PENDING
      frame SAS_HSC2_FrP00_oCAN00: id 0x1E5, to P2P, frame-length=8, can-addressing-mode=STANDARD
        pdu SAS_HSC2_FrP00_oCAN00: length=8, transmission-mode-false-timing=cyclic-timing=time-period=0, transmission-mode-true-timing=cyclic-timing=time-period=0, unused-bit-pattern=0
          signal StrgWhlAngVHSC2_oSAS_HSC2_FrP00_oCAN00: start 7, 1 bit, big-endian, init-value=0, base-type=boolean, compu-method=CM_StrgWhlAngVHSC2, transfer-property=PENDING, to P2P
          signal StrgWhlAngHSC2_oSAS_HSC2_FrP00_oCAN00: start 15, 16 bit, big-endian, init-value=0, base-type=uint16, compu-method=CM_StrgWhlAngHSC2, unit=U_degree, transfer-property=PENDING, to P2P
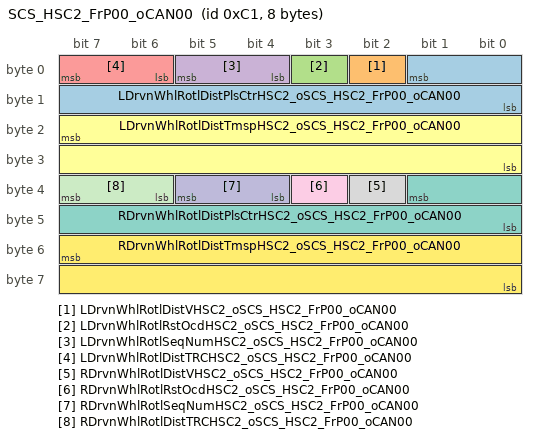
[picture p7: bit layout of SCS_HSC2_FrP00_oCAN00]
      frame SCS_HSC2_FrP00_oCAN00: id 0xC1, to P2P, frame-length=8, can-addressing-mode=STANDARD
        pdu SCS_HSC2_FrP00_oCAN00: length=8, transmission-mode-false-timing=cyclic-timing=time-period=0, transmission-mode-true-timing=cyclic-timing=time-period=0, unused-bit-pattern=0
          signal LDrvnWhlRotlDistPlsCtrHSC2_oSCS_HSC2_FrP00_oCAN00: start 1, 10 bit, big-endian, init-value=0, base-type=uint16, compu-method=CM_LDrvnWhlRotlDistPlsCtrHSC2, transfer-property=PENDING, to P2P
          signal LDrvnWhlRotlDistVHSC2_oSCS_HSC2_FrP00_oCAN00: start 2, 1 bit, big-endian, init-value=0, base-type=boolean, compu-method=CM_LDrvnWhlRotlDistVHSC2, transfer-property=PENDING, to P2P
          signal LDrvnWhlRotlRstOcdHSC2_oSCS_HSC2_FrP00_oCAN00: start 3, 1 bit, big-endian, init-value=0, base-type=boolean, compu-method=CM_LDrvnWhlRotlRstOcdHSC2, transfer-property=PENDING, to P2P
          signal LDrvnWhlRotlSeqNumHSC2_oSCS_HSC2_FrP00_oCAN00: start 5, 2 bit, big-endian, init-value=0, base-type=uint8, compu-method=CM_LDrvnWhlRotlSeqNumHSC2, transfer-property=PENDING, to P2P
          signal LDrvnWhlRotlDistTRCHSC2_oSCS_HSC2_FrP00_oCAN00: start 7, 2 bit, big-endian, init-value=0, base-type=uint8, compu-method=CM_LDrvnWhlRotlDistTRCHSC2, transfer-property=PENDING, to P2P
          signal LDrvnWhlRotlDistTmspHSC2_oSCS_HSC2_FrP00_oCAN00: start 23, 16 bit, big-endian, init-value=0, base-type=uint16, compu-method=CM_LDrvnWhlRotlDistTmspHSC2, transfer-property=PENDING, to P2P
          signal RDrvnWhlRotlDistPlsCtrHSC2_oSCS_HSC2_FrP00_oCAN00: start 33, 10 bit, big-endian, init-value=0, base-type=uint16, compu-method=CM_RDrvnWhlRotlDistPlsCtrHSC2, transfer-property=PENDING, to P2P
          signal RDrvnWhlRotlDistVHSC2_oSCS_HSC2_FrP00_oCAN00: start 34, 1 bit, big-endian, init-value=0, base-type=boolean, compu-method=CM_RDrvnWhlRotlDistVHSC2, transfer-property=PENDING, to P2P
          signal RDrvnWhlRotlRstOcdHSC2_oSCS_HSC2_FrP00_oCAN00: start 35, 1 bit, big-endian, init-value=0, base-type=boolean, compu-method=CM_RDrvnWhlRotlRstOcdHSC2, transfer-property=PENDING, to P2P
          signal RDrvnWhlRotlSeqNumHSC2_oSCS_HSC2_FrP00_oCAN00: start 37, 2 bit, big-endian, init-value=0, base-type=uint8, compu-method=CM_RDrvnWhlRotlSeqNumHSC2, transfer-property=PENDING, to P2P
          signal RDrvnWhlRotlDistTRCHSC2_oSCS_HSC2_FrP00_oCAN00: start 39, 2 bit, big-endian, init-value=0, base-type=uint8, compu-method=CM_RDrvnWhlRotlDistTRCHSC2, transfer-property=PENDING, to P2P
          signal RDrvnWhlRotlDistTmspHSC2_oSCS_HSC2_FrP00_oCAN00: start 55, 16 bit, big-endian, init-value=0, base-type=uint16, compu-method=CM_RDrvnWhlRotlDistTmspHSC2, transfer-property=PENDING, to P2P
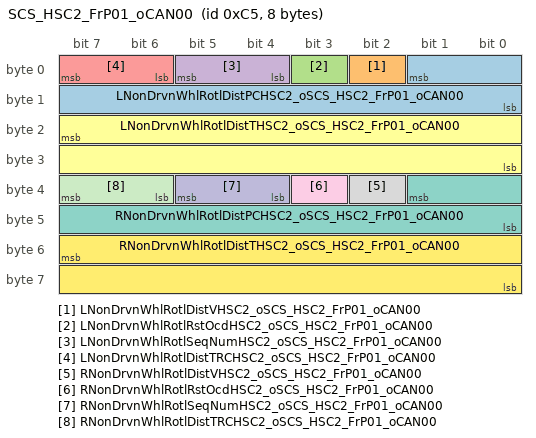
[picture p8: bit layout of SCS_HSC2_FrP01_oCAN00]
      frame SCS_HSC2_FrP01_oCAN00: id 0xC5, to P2P, frame-length=8, can-addressing-mode=STANDARD
        pdu SCS_HSC2_FrP01_oCAN00: length=8, transmission-mode-false-timing=cyclic-timing=time-period=0, transmission-mode-true-timing=cyclic-timing=time-period=0, unused-bit-pattern=0
          signal LNonDrvnWhlRotlDistPCHSC2_oSCS_HSC2_FrP01_oCAN00: start 1, 10 bit, big-endian, init-value=0, base-type=uint16, compu-method=CM_LNonDrvnWhlRotlDistPCHSC2, transfer-property=PENDING, to P2P
          signal LNonDrvnWhlRotlDistVHSC2_oSCS_HSC2_FrP01_oCAN00: start 2, 1 bit, big-endian, init-value=0, base-type=boolean, compu-method=CM_LNonDrvnWhlRotlDistVHSC2, transfer-property=PENDING, to P2P
          signal LNonDrvnWhlRotlRstOcdHSC2_oSCS_HSC2_FrP01_oCAN00: start 3, 1 bit, big-endian, init-value=0, base-type=boolean, compu-method=CM_LNonDrvnWhlRotlRstOcdHSC2, transfer-property=PENDING, to P2P
          signal LNonDrvnWhlRotlSeqNumHSC2_oSCS_HSC2_FrP01_oCAN00: start 5, 2 bit, big-endian, init-value=0, base-type=uint8, compu-method=CM_LNonDrvnWhlRotlSeqNumHSC2, transfer-property=PENDING, to P2P
          signal LNonDrvnWhlRotlDistTRCHSC2_oSCS_HSC2_FrP01_oCAN00: start 7, 2 bit, big-endian, init-value=0, base-type=uint8, compu-method=CM_LNonDrvnWhlRotlDistTRCHSC2, transfer-property=PENDING, to P2P
          signal LNonDrvnWhlRotlDistTHSC2_oSCS_HSC2_FrP01_oCAN00: start 23, 16 bit, big-endian, init-value=0, base-type=uint16, compu-method=CM_LNonDrvnWhlRotlDistTHSC2, transfer-property=PENDING, to P2P
          signal RNonDrvnWhlRotlDistPCHSC2_oSCS_HSC2_FrP01_oCAN00: start 33, 10 bit, big-endian, init-value=0, base-type=uint16, compu-method=CM_RNonDrvnWhlRotlDistPCHSC2, transfer-property=PENDING, to P2P
          signal RNonDrvnWhlRotlDistVHSC2_oSCS_HSC2_FrP01_oCAN00: start 34, 1 bit, big-endian, init-value=0, base-type=boolean, compu-method=CM_RNonDrvnWhlRotlDistVHSC2, transfer-property=PENDING, to P2P
          signal RNonDrvnWhlRotlRstOcdHSC2_oSCS_HSC2_FrP01_oCAN00: start 35, 1 bit, big-endian, init-value=0, base-type=boolean, compu-method=CM_RNonDrvnWhlRotlRstOcdHSC2, transfer-property=PENDING, to P2P
          signal RNonDrvnWhlRotlSeqNumHSC2_oSCS_HSC2_FrP01_oCAN00: start 37, 2 bit, big-endian, init-value=0, base-type=uint8, compu-method=CM_RNonDrvnWhlRotlSeqNumHSC2, transfer-property=PENDING, to P2P
          signal RNonDrvnWhlRotlDistTRCHSC2_oSCS_HSC2_FrP01_oCAN00: start 39, 2 bit, big-endian, init-value=0, base-type=uint8, compu-method=CM_RNonDrvnWhlRotlDistTRCHSC2, transfer-property=PENDING, to P2P
          signal RNonDrvnWhlRotlDistTHSC2_oSCS_HSC2_FrP01_oCAN00: start 55, 16 bit, big-endian, init-value=0, base-type=uint16, compu-method=CM_RNonDrvnWhlRotlDistTHSC2, transfer-property=PENDING, to P2P
      frame SCS_HSC2_FrP02_oCAN00: id 0x185, to P2P, frame-length=4, can-addressing-mode=STANDARD
        pdu SCS_HSC2_FrP02_oCAN00: length=4, transmission-mode-false-timing=cyclic-timing=time-period=0, transmission-mode-true-timing=cyclic-timing=time-period=0, unused-bit-pattern=0
          signal VSELongtAccHSC2_oSCS_HSC2_FrP02_oCAN00: start 1, 10 bit, big-endian, init-value=0, base-type=sint16, compu-method=CM_VSELongtAccHSC2, unit=U_mYsX2, transfer-property=PENDING, to P2P
          signal VSELongtAccVHSC2_oSCS_HSC2_FrP02_oCAN00: start 2, 1 bit, big-endian, init-value=0, base-type=boolean, compu-method=CM_VSELongtAccVHSC2, transfer-property=PENDING, to P2P
          signal VSELatAccVHSC2_oSCS_HSC2_FrP02_oCAN00: start 3, 1 bit, big-endian, init-value=0, base-type=boolean, compu-method=CM_VSELatAccVHSC2, transfer-property=PENDING, to P2P
          signal VSELatAccHSC2_oSCS_HSC2_FrP02_oCAN00: start 19, 12 bit, big-endian, init-value=0, base-type=sint16, compu-method=CM_VSELatAccHSC2, unit=U_mYsX2, transfer-property=PENDING, to P2P
      frame SCS_HSC2_FrP03_oCAN00: id 0x1C7, to P2P, frame-length=8, can-addressing-mode=STANDARD
        pdu SCS_HSC2_FrP03_oCAN00: length=8, transmission-mode-false-timing=cyclic-timing=time-period=0, transmission-mode-true-timing=cyclic-timing=time-period=0, unused-bit-pattern=0
          signal LNonDrvnWhlRotlDircnHSC2_oSCS_HSC2_FrP03_oCAN00: start 33, 2 bit, big-endian, init-value=3, base-type=uint8, compu-method=CM_LNonDrvnWhlRotlDircnHSC2, transfer-property=PENDING, to P2P
          signal RNonDrvnWhlRotlDircnHSC2_oSCS_HSC2_FrP03_oCAN00: start 35, 2 bit, big-endian, init-value=3, base-type=uint8, compu-method=CM_RNonDrvnWhlRotlDircnHSC2, transfer-property=PENDING, to P2P
          signal SCSAPAAlvRCHSC2_oSCS_HSC2_FrP03_oCAN00: start 39, 4 bit, big-endian, init-value=0, base-type=uint8, compu-method=CM_SCSAPAAlvRCHSC2, transfer-property=PENDING, to P2P
          signal SCSNRCDAvlblHSC2_oSCS_HSC2_FrP03_oCAN00: start 45, 1 bit, big-endian, init-value=0, base-type=boolean, compu-method=CM_SCSNRCDAvlblHSC2, transfer-property=PENDING, to P2P  # Stability Control System Near Range Control Drive Available
          signal SCSAPAAcclAHSC2_oSCS_HSC2_FrP03_oCAN00: start 46, 1 bit, big-endian, init-value=0, base-type=boolean, compu-method=CM_SCSAPAAcclAHSC2, transfer-property=PENDING, to P2P
          signal SCSAPAAvlblHSC2_oSCS_HSC2_FrP03_oCAN00: start 47, 1 bit, big-endian, init-value=0, base-type=boolean, compu-method=CM_SCSAPAAvlblHSC2, transfer-property=PENDING, to P2P
      frame SCS_HSC2_FrP05_oCAN00: id 0x1E9, to P2P, frame-length=8, can-addressing-mode=STANDARD
        pdu SCS_HSC2_FrP05_oCAN00: length=8, transmission-mode-false-timing=cyclic-timing=time-period=0, transmission-mode-true-timing=cyclic-timing=time-period=0, unused-bit-pattern=0
          signal VSESysAHSC2_oSCS_HSC2_FrP05_oCAN00: start 24, 1 bit, big-endian, init-value=0, base-type=boolean, compu-method=CM_VSESysAHSC2, transfer-property=PENDING, to P2P
          signal TCSAHSC2_oSCS_HSC2_FrP05_oCAN00: start 28, 1 bit, big-endian, init-value=0, base-type=boolean, compu-method=CM_TCSAHSC2, transfer-property=PENDING, to P2P
          signal ABSAHSC2_oSCS_HSC2_FrP05_oCAN00: start 30, 1 bit, big-endian, init-value=0, base-type=boolean, compu-method=CM_ABSAHSC2, transfer-property=PENDING, to P2P
          signal VehDynYawRateHSC2_oSCS_HSC2_FrP05_oCAN00: start 35, 12 bit, big-endian, init-value=0, base-type=sint16, compu-method=CM_VehDynYawRateHSC2, unit=U_degYs, transfer-property=PENDING, to P2P
          signal VehDynYawRateVHSC2_oSCS_HSC2_FrP05_oCAN00: start 36, 1 bit, big-endian, init-value=0, base-type=boolean, compu-method=CM_VehDynYawRateVHSC2, transfer-property=PENDING, to P2P
      frame SCS_HSC2_FrP11_oCAN00: id 0x348, to P2P, frame-length=8, can-addressing-mode=STANDARD
        pdu SCS_HSC2_FrP11_oCAN00: length=8, transmission-mode-false-timing=cyclic-timing=time-period=0, transmission-mode-true-timing=cyclic-timing=time-period=0, unused-bit-pattern=0
          signal WhlGndVelLDrvnHSC2_oSCS_HSC2_FrP11_oCAN00: start 5, 14 bit, big-endian, init-value=0, base-type=uint16, compu-method=CM_WhlGndVelLDrvnHSC2, unit=U_kmYh, transfer-property=PENDING, to P2P
          signal WhlGndVelLDrvnVHSC2_oSCS_HSC2_FrP11_oCAN00: start 6, 1 bit, big-endian, init-value=1, base-type=boolean, compu-method=CM_WhlGndVelLDrvnVHSC2, transfer-property=PENDING, to P2P  # Wheel Ground Velocity Left Driven Validity
          signal WhlGndVelRDrvnHSC2_oSCS_HSC2_FrP11_oCAN00: start 21, 14 bit, big-endian, init-value=0, base-type=uint16, compu-method=CM_WhlGndVelRDrvnHSC2, unit=U_kmYh, transfer-property=PENDING, to P2P
          signal WhlGndVelRDrvnVHSC2_oSCS_HSC2_FrP11_oCAN00: start 22, 1 bit, big-endian, init-value=1, base-type=boolean, compu-method=CM_WhlGndVelRDrvnVHSC2, transfer-property=PENDING, to P2P  # Wheel Ground Velocity Right Driven Validity
      frame SCS_HSC2_FrP12_oCAN00: id 0x34A, to P2P, frame-length=8, can-addressing-mode=STANDARD
        pdu SCS_HSC2_FrP12_oCAN00: length=8, transmission-mode-false-timing=cyclic-timing=time-period=0, transmission-mode-true-timing=cyclic-timing=time-period=0, unused-bit-pattern=0
          signal WhlGndVelLNonDrvnHSC2_oSCS_HSC2_FrP12_oCAN00: start 5, 14 bit, big-endian, init-value=0, base-type=uint16, compu-method=CM_WhlGndVelLNonDrvnHSC2, unit=U_kmYh, transfer-property=PENDING, to P2P
          signal WhlGndVelLNonDrvnVHSC2_oSCS_HSC2_FrP12_oCAN00: start 6, 1 bit, big-endian, init-value=1, base-type=boolean, compu-method=CM_WhlGndVelLNonDrvnVHSC2, transfer-property=PENDING, to P2P  # Wheel Ground Velocity Left Non Driven Validity
          signal WhlGndVelRNonDrvnHSC2_oSCS_HSC2_FrP12_oCAN00: start 21, 14 bit, big-endian, init-value=0, base-type=uint16, compu-method=CM_WhlGndVelRNonDrvnHSC2, unit=U_kmYh, transfer-property=PENDING, to P2P
          signal WhlGndVelRNonDrvnVHSC2_oSCS_HSC2_FrP12_oCAN00: start 22, 1 bit, big-endian, init-value=1, base-type=boolean, compu-method=CM_WhlGndVelRNonDrvnVHSC2, transfer-property=PENDING, to P2P  # Wheel Ground Velocity Right Non Driven Validity
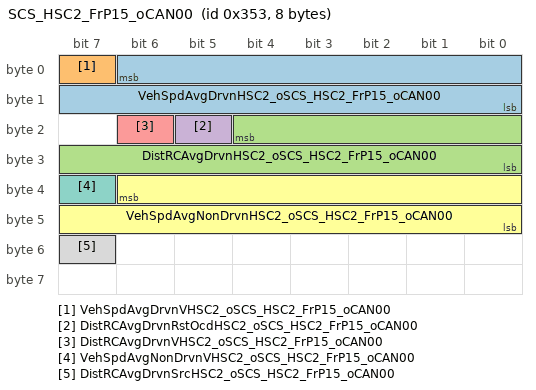
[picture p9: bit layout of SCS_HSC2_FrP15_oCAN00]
      frame SCS_HSC2_FrP15_oCAN00: id 0x353, to P2P, frame-length=8, can-addressing-mode=STANDARD
        pdu SCS_HSC2_FrP15_oCAN00: length=8, transmission-mode-false-timing=cyclic-timing=time-period=0, transmission-mode-true-timing=cyclic-timing=time-period=0, unused-bit-pattern=0
          signal VehSpdAvgDrvnHSC2_oSCS_HSC2_FrP15_oCAN00: start 6, 15 bit, big-endian, init-value=0, base-type=uint16, compu-method=CM_VehSpdAvgDrvnHSC2, unit=U_kmYh, transfer-property=PENDING, to P2P
          signal VehSpdAvgDrvnVHSC2_oSCS_HSC2_FrP15_oCAN00: start 7, 1 bit, big-endian, init-value=0, base-type=boolean, compu-method=CM_VehSpdAvgDrvnVHSC2, transfer-property=PENDING, to P2P
          signal DistRCAvgDrvnHSC2_oSCS_HSC2_FrP15_oCAN00: start 20, 13 bit, big-endian, init-value=0, base-type=uint16, compu-method=CM_DistRCAvgDrvnHSC2, unit=U_m, transfer-property=PENDING, to P2P
          signal DistRCAvgDrvnRstOcdHSC2_oSCS_HSC2_FrP15_oCAN00: start 21, 1 bit, big-endian, init-value=0, base-type=boolean, compu-method=CM_DistRCAvgDrvnRstOcdHSC2, transfer-property=PENDING, to P2P
          signal DistRCAvgDrvnVHSC2_oSCS_HSC2_FrP15_oCAN00: start 22, 1 bit, big-endian, init-value=0, base-type=boolean, compu-method=CM_DistRCAvgDrvnVHSC2, transfer-property=PENDING, to P2P
          signal VehSpdAvgNonDrvnHSC2_oSCS_HSC2_FrP15_oCAN00: start 38, 15 bit, big-endian, init-value=0, base-type=uint16, compu-method=CM_VehSpdAvgNonDrvnHSC2, unit=U_kmYh, transfer-property=PENDING, to P2P
          signal VehSpdAvgNonDrvnVHSC2_oSCS_HSC2_FrP15_oCAN00: start 39, 1 bit, big-endian, init-value=0, base-type=boolean, compu-method=CM_VehSpdAvgNonDrvnVHSC2, transfer-property=PENDING, to P2P
          signal DistRCAvgDrvnSrcHSC2_oSCS_HSC2_FrP15_oCAN00: start 55, 1 bit, big-endian, init-value=0, base-type=boolean, compu-method=CM_DistRCAvgDrvnSrcHSC2, transfer-property=PENDING, to P2P  # Distance Rolling Count Average Driven Source
      frame Tester_HSC2_ECM_FrP00_oCAN00: id 0xC9, to P2P, frame-length=8, can-addressing-mode=STANDARD
        pdu Tester_HSC2_ECM_FrP00_oCAN00: length=8, transmission-mode-false-timing=cyclic-timing=time-period=0, transmission-mode-true-timing=cyclic-timing=time-period=0, unused-bit-pattern=0
          signal EnRunAHSC2_oTester_HSC2_ECM_FrP00_oCAN00: start 7, 1 bit, big-endian, init-value=0, base-type=boolean, compu-method=CM_EnRunAHSC2, transfer-property=PENDING, to P2P
      frame Tester_HSC2_GW_FrP14_oCAN00: id 0x1AD, to P2P, frame-length=6, can-addressing-mode=STANDARD
        pdu Tester_HSC2_GW_FrP14_oCAN00: length=6, transmission-mode-false-timing=cyclic-timing=time-period=0, transmission-mode-true-timing=cyclic-timing=time-period=0, unused-bit-pattern=0
          signal NRCDFHSC2_oTester_HSC2_GW_FrP14_oCAN00: start 5, 1 bit, big-endian, init-value=0, base-type=boolean, compu-method=CM_NRCDFHSC2, transfer-property=PENDING, to P2P  # Near Range Control Drive Failed
          signal NRCDAlvRCHSC2_oTester_HSC2_GW_FrP14_oCAN00: start 39, 8 bit, big-endian, init-value=0, base-type=uint8, compu-method=CM_NRCDAlvRCHSC2, transfer-property=PENDING, to P2P  # Near Range Control Drive Alive Rolling Count
  can cluster CAN01: protocol-name=CAN  # 180522-lh1-EP21P2P_P2P_CAN4-V09
    can physical channel CHNL: comm-connectors=CN_CAN01
      frame FICM_HSC4_FrP02_oCAN01: id 0x376, to P2P, frame-length=8, can-addressing-mode=STANDARD
        pdu FICM_HSC4_FrP02_oCAN01: length=8, transmission-mode-false-timing=cyclic-timing=time-period=0, transmission-mode-true-timing=cyclic-timing=time-period=0, unused-bit-pattern=0
          signal RstrFctryDeftsReqHSC4_oFICM_HSC4_FrP02_oCAN01: start 56, 1 bit, big-endian, init-value=0, base-type=boolean, compu-method=CM_RstrFctryDeftsReqHSC4, transfer-property=PENDING, to P2P
      frame FICM_HSC4_FrP08_oCAN01: id 0x2F6, to P2P, frame-length=8, can-addressing-mode=STANDARD
        pdu FICM_HSC4_FrP08_oCAN01: length=8, transmission-mode-false-timing=cyclic-timing=time-period=0, transmission-mode-true-timing=cyclic-timing=time-period=0, unused-bit-pattern=0
          signal APASwReqHSC4_oFICM_HSC4_FrP08_oCAN01: start 59, 2 bit, big-endian, init-value=0, base-type=uint8, compu-method=CM_APASwReqHSC4, transfer-property=PENDING, to P2P
          signal PDCSwReqHSC4_oFICM_HSC4_FrP08_oCAN01: start 61, 2 bit, big-endian, init-value=0, base-type=uint8, compu-method=CM_PDCSwReqHSC4, transfer-property=PENDING, to P2P
      frame FICM_HSC4_FrP13_oCAN01: id 0x2F2, to P2P, frame-length=8, can-addressing-mode=STANDARD
        pdu FICM_HSC4_FrP13_oCAN01: length=8, transmission-mode-false-timing=cyclic-timing=time-period=0, transmission-mode-true-timing=cyclic-timing=time-period=0, unused-bit-pattern=0
          signal AlisysrdyHSC4_oFICM_HSC4_FrP13_oCAN01: start 50, 1 bit, big-endian, init-value=0, base-type=boolean, compu-method=CM_AlisysrdyHSC4, transfer-property=PENDING, to P2P
      frame FICM_HSC4_FrP18_oCAN01: id 0x37D, to P2P, frame-length=8, can-addressing-mode=STANDARD
        pdu FICM_HSC4_FrP18_oCAN01: length=8, transmission-mode-false-timing=cyclic-timing=time-period=0, transmission-mode-true-timing=cyclic-timing=time-period=0, unused-bit-pattern=0
          signal DrvrSelAPAParkngMdHSC4_oFICM_HSC4_FrP18_oCAN01: start 0, 3 bit, big-endian, init-value=0, base-type=uint8, compu-method=CM_DrvrSelAPAParkngMdHSC4, transfer-property=PENDING, to P2P  # Driver Select Advanced Park Assist Parking Mode
          signal DrvrSelAPASlotBearngHSC4_oFICM_HSC4_FrP18_oCAN01: start 6, 2 bit, big-endian, init-value=0, base-type=uint8, compu-method=CM_DrvrSelAPASlotBearngHSC4, transfer-property=PENDING, to P2P
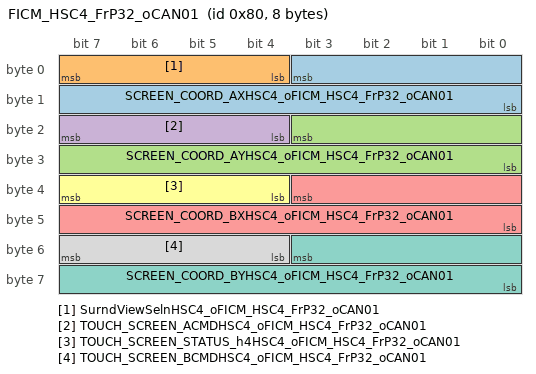
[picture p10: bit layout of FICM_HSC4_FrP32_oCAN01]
      frame FICM_HSC4_FrP32_oCAN01: id 0x80, to P2P, frame-length=8, can-addressing-mode=STANDARD
        pdu FICM_HSC4_FrP32_oCAN01: length=8, transmission-mode-false-timing=cyclic-timing=time-period=0, transmission-mode-true-timing=cyclic-timing=time-period=0, unused-bit-pattern=0
          signal SCREEN_COORD_AXHSC4_oFICM_HSC4_FrP32_oCAN01: start 3, 12 bit, big-endian, init-value=0, base-type=uint16, compu-method=CM_SCREEN_COORD_AXHSC4, transfer-property=PENDING, to P2P
          signal SurndViewSelnHSC4_oFICM_HSC4_FrP32_oCAN01: start 7, 4 bit, big-endian, init-value=0, base-type=uint8, compu-method=CM_SurndViewSelnHSC4, transfer-property=PENDING, to P2P
          signal SCREEN_COORD_AYHSC4_oFICM_HSC4_FrP32_oCAN01: start 19, 12 bit, big-endian, init-value=0, base-type=uint16, compu-method=CM_SCREEN_COORD_AYHSC4, transfer-property=PENDING, to P2P
          signal TOUCH_SCREEN_ACMDHSC4_oFICM_HSC4_FrP32_oCAN01: start 23, 4 bit, big-endian, init-value=0, base-type=uint8, compu-method=CM_TOUCH_SCREEN_ACMDHSC4, transfer-property=PENDING, to P2P
          signal SCREEN_COORD_BXHSC4_oFICM_HSC4_FrP32_oCAN01: start 35, 12 bit, big-endian, init-value=0, base-type=uint16, compu-method=CM_SCREEN_COORD_BXHSC4, transfer-property=PENDING, to P2P
          signal TOUCH_SCREEN_STATUS_h4HSC4_oFICM_HSC4_FrP32_oCAN01: start 39, 4 bit, big-endian, init-value=0, base-type=uint8, compu-method=CM_TOUCH_SCREEN_STATUS_h4HSC4, transfer-property=PENDING, to P2P
          signal SCREEN_COORD_BYHSC4_oFICM_HSC4_FrP32_oCAN01: start 51, 12 bit, big-endian, init-value=0, base-type=uint16, compu-method=CM_SCREEN_COORD_BYHSC4, transfer-property=PENDING, to P2P
          signal TOUCH_SCREEN_BCMDHSC4_oFICM_HSC4_FrP32_oCAN01: start 55, 4 bit, big-endian, init-value=0, base-type=uint8, compu-method=CM_TOUCH_SCREEN_BCMDHSC4, transfer-property=PENDING, to P2P
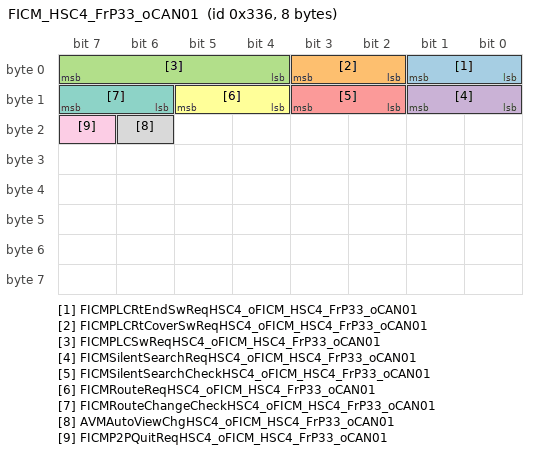
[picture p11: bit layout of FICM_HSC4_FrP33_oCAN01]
      frame FICM_HSC4_FrP33_oCAN01: id 0x336, to P2P, frame-length=8, can-addressing-mode=STANDARD
        pdu FICM_HSC4_FrP33_oCAN01: length=8, transmission-mode-false-timing=cyclic-timing=time-period=0, transmission-mode-true-timing=cyclic-timing=time-period=0, unused-bit-pattern=0
          signal FICMPLCRtEndSwReqHSC4_oFICM_HSC4_FrP33_oCAN01: start 1, 2 bit, big-endian, init-value=0, base-type=uint8, compu-method=CM_FICMPLCRtEndSwReqHSC4, transfer-property=PENDING, to P2P
          signal FICMPLCRtCoverSwReqHSC4_oFICM_HSC4_FrP33_oCAN01: start 3, 2 bit, big-endian, init-value=0, base-type=uint8, compu-method=CM_FICMPLCRtCoverSwReqHSC4, transfer-property=PENDING, to P2P
          signal FICMPLCSwReqHSC4_oFICM_HSC4_FrP33_oCAN01: start 7, 4 bit, big-endian, init-value=0, base-type=uint8, compu-method=CM_FICMPLCSwReqHSC4, transfer-property=PENDING, to P2P
          signal FICMSilentSearchReqHSC4_oFICM_HSC4_FrP33_oCAN01: start 9, 2 bit, big-endian, init-value=0, base-type=uint8, compu-method=CM_FICMSilentSearchReqHSC4, transfer-property=PENDING, to P2P
          signal FICMSilentSearchCheckHSC4_oFICM_HSC4_FrP33_oCAN01: start 11, 2 bit, big-endian, init-value=0, base-type=uint8, compu-method=CM_FICMSilentSearchCheckHSC4, transfer-property=PENDING, to P2P
          signal FICMRouteReqHSC4_oFICM_HSC4_FrP33_oCAN01: start 13, 2 bit, big-endian, init-value=0, base-type=uint8, compu-method=CM_FICMRouteReqHSC4, transfer-property=PENDING, to P2P
          signal FICMRouteChangeCheckHSC4_oFICM_HSC4_FrP33_oCAN01: start 15, 2 bit, big-endian, init-value=0, base-type=uint8, compu-method=CM_FICMRouteChangeCheckHSC4, transfer-property=PENDING, to P2P
          signal AVMAutoViewChgHSC4_oFICM_HSC4_FrP33_oCAN01: start 22, 1 bit, big-endian, init-value=0, base-type=boolean, compu-method=CM_AVMAutoViewChgHSC4, transfer-property=PENDING, to P2P
          signal FICMP2PQuitReqHSC4_oFICM_HSC4_FrP33_oCAN01: start 23, 1 bit, big-endian, init-value=0, base-type=boolean, compu-method=CM_FICMP2PQuitReqHSC4, transfer-property=PENDING, to P2P
      frame GW_HSC4_BCM_FrP04_oCAN01: id 0x46A, to P2P, frame-length=8, can-addressing-mode=STANDARD
        pdu GW_HSC4_BCM_FrP04_oCAN01: length=8, transmission-mode-false-timing=cyclic-timing=time-period=0, transmission-mode-true-timing=cyclic-timing=time-period=0, unused-bit-pattern=0
          signal VehLckngStaHSC4_oGW_HSC4_BCM_FrP04_oCAN01: start 55, 3 bit, big-endian, init-value=7, base-type=uint8, compu-method=CM_VehLckngStaHSC4, transfer-property=PENDING, to P2P  # Vehicle Locking State
      frame GW_HSC4_BCM_FrS09_oCAN01: id 0x3C, to P2P, frame-length=8, can-addressing-mode=STANDARD
        pdu GW_HSC4_BCM_FrS09_oCAN01: length=8, unused-bit-pattern=0
          signal BCMImmoData4HSC4_oGW_HSC4_BCM_FrS09_oCAN01: start 0, 64 bit, opaque, init-value=8 x 0, base-type=uint8_8_iso_8859_1, compu-method=CM_BCMImmoData4HSC4, transfer-property=PENDING, to P2P
      frame GW_HSC4_BCM_FrS10_oCAN01: id 0x3D, to P2P, frame-length=8, can-addressing-mode=STANDARD
        pdu GW_HSC4_BCM_FrS10_oCAN01: length=8, unused-bit-pattern=0
          signal BCMImmoData5HSC4_oGW_HSC4_BCM_FrS10_oCAN01: start 0, 64 bit, opaque, init-value=8 x 0, base-type=uint8_8_iso_8859_1, compu-method=CM_BCMImmoData5HSC4, transfer-property=PENDING, to P2P
      frame GW_HSC4_BMS_FrP07_oCAN01: id 0x29B, to P2P, frame-length=8, can-addressing-mode=STANDARD
        pdu GW_HSC4_BMS_FrP07_oCAN01: length=8, transmission-mode-false-timing=cyclic-timing=time-period=0, transmission-mode-true-timing=cyclic-timing=time-period=0, unused-bit-pattern=0
          signal BMSBscSta_h1HSC4_oGW_HSC4_BMS_FrP07_oCAN01: start 5, 5 bit, big-endian, init-value=0, base-type=uint8, compu-method=CM_BMSBscSta_h1HSC4, transfer-property=PENDING, to P2P
      frame GW_HSC4_PEPS_FrP01_oCAN01: id 0x17B, to P2P, frame-length=8, can-addressing-mode=STANDARD
        pdu GW_HSC4_PEPS_FrP01_oCAN01: length=8, transmission-mode-false-timing=cyclic-timing=time-period=0, transmission-mode-true-timing=cyclic-timing=time-period=0, unused-bit-pattern=0
          signal PEPSSSBAHSC4_oGW_HSC4_PEPS_FrP01_oCAN01: start 56, 1 bit, big-endian, init-value=0, base-type=boolean, compu-method=CM_PEPSSSBAHSC4, transfer-property=PENDING, to P2P
          signal FRDoorHadlSwAHSC4_oGW_HSC4_PEPS_FrP01_oCAN01: start 58, 1 bit, big-endian, init-value=0, base-type=boolean, compu-method=CM_FRDoorHadlSwAHSC4, transfer-property=PENDING, to P2P  # Front Right Door Handle Switch Active
          signal FLDoorHadlSwAHSC4_oGW_HSC4_PEPS_FrP01_oCAN01: start 59, 1 bit, big-endian, init-value=0, base-type=boolean, compu-method=CM_FLDoorHadlSwAHSC4, transfer-property=PENDING, to P2P  # Front Left Door Handle Switch Active
          signal PEPSSSBAVHSC4_oGW_HSC4_PEPS_FrP01_oCAN01: start 61, 1 bit, big-endian, init-value=0, base-type=boolean, compu-method=CM_PEPSSSBAVHSC4, transfer-property=PENDING, to P2P
      frame GW_HSC4_PEPS_FrP02_oCAN01: id 0x239, to P2P, frame-length=8, can-addressing-mode=STANDARD
        pdu GW_HSC4_PEPS_FrP02_oCAN01: length=8, transmission-mode-false-timing=cyclic-timing=time-period=0, transmission-mode-true-timing=cyclic-timing=time-period=0, unused-bit-pattern=0
          signal PEPSSSBFltStsHSC4_oGW_HSC4_PEPS_FrP02_oCAN01: start 54, 3 bit, big-endian, init-value=0, base-type=uint8, compu-method=CM_PEPSSSBFltStsHSC4, transfer-property=PENDING, to P2P
      frame GW_HSC4_TBOX_FrP01_oCAN01: id 0x34D, to P2P, frame-length=8, can-addressing-mode=STANDARD
        pdu GW_HSC4_TBOX_FrP01_oCAN01: length=8, transmission-mode-false-timing=cyclic-timing=time-period=0, transmission-mode-true-timing=cyclic-timing=time-period=0, unused-bit-pattern=0
          signal P2PSwReqHSC4_oGW_HSC4_TBOX_FrP01_oCAN01: start 15, 1 bit, big-endian, init-value=0, base-type=boolean, compu-method=CM_P2PSwReqHSC4, transfer-property=PENDING, to P2P
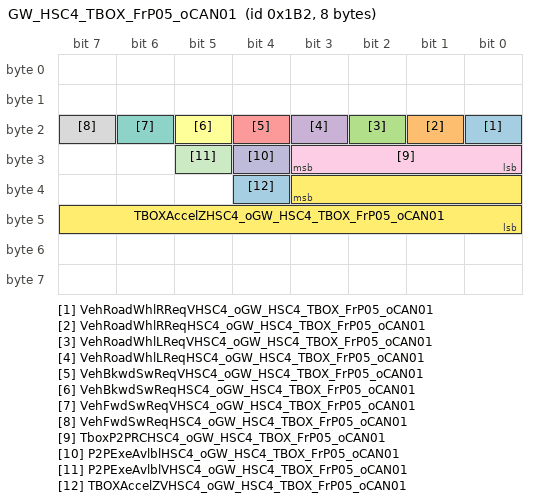
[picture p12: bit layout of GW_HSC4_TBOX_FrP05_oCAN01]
      frame GW_HSC4_TBOX_FrP05_oCAN01: id 0x1B2, to P2P, frame-length=8, can-addressing-mode=STANDARD
        pdu GW_HSC4_TBOX_FrP05_oCAN01: length=8, transmission-mode-false-timing=cyclic-timing=time-period=0, transmission-mode-true-timing=cyclic-timing=time-period=0, unused-bit-pattern=0
          signal VehRoadWhlRReqVHSC4_oGW_HSC4_TBOX_FrP05_oCAN01: start 16, 1 bit, big-endian, init-value=0, base-type=boolean, compu-method=CM_VehRoadWhlRReqVHSC4, transfer-property=PENDING, to P2P  # Vehicle Road Wheel Right Request Validity
          signal VehRoadWhlRReqHSC4_oGW_HSC4_TBOX_FrP05_oCAN01: start 17, 1 bit, big-endian, init-value=0, base-type=boolean, compu-method=CM_VehRoadWhlRReqHSC4, transfer-property=PENDING, to P2P  # Vehicle Road Wheel Right Request
          signal VehRoadWhlLReqVHSC4_oGW_HSC4_TBOX_FrP05_oCAN01: start 18, 1 bit, big-endian, init-value=0, base-type=boolean, compu-method=CM_VehRoadWhlLReqVHSC4, transfer-property=PENDING, to P2P  # Vehicle Road Wheel Left Request Validity
          signal VehRoadWhlLReqHSC4_oGW_HSC4_TBOX_FrP05_oCAN01: start 19, 1 bit, big-endian, init-value=0, base-type=boolean, compu-method=CM_VehRoadWhlLReqHSC4, transfer-property=PENDING, to P2P  # Vehicle Road Wheel Left Request
          signal VehBkwdSwReqVHSC4_oGW_HSC4_TBOX_FrP05_oCAN01: start 20, 1 bit, big-endian, init-value=0, base-type=boolean, compu-method=CM_VehBkwdSwReqVHSC4, transfer-property=PENDING, to P2P  # Vehicle Backward Switch Request Validity
          signal VehBkwdSwReqHSC4_oGW_HSC4_TBOX_FrP05_oCAN01: start 21, 1 bit, big-endian, init-value=0, base-type=boolean, compu-method=CM_VehBkwdSwReqHSC4, transfer-property=PENDING, to P2P  # Vehicle Backward Switch Request
          signal VehFwdSwReqVHSC4_oGW_HSC4_TBOX_FrP05_oCAN01: start 22, 1 bit, big-endian, init-value=0, base-type=boolean, compu-method=CM_VehFwdSwReqVHSC4, transfer-property=PENDING, to P2P  # Vehicle Forward Switch Request Validity
          signal VehFwdSwReqHSC4_oGW_HSC4_TBOX_FrP05_oCAN01: start 23, 1 bit, big-endian, init-value=0, base-type=boolean, compu-method=CM_VehFwdSwReqHSC4, transfer-property=PENDING, to P2P  # Vehicle Forward Switch Request
          signal TboxP2PRCHSC4_oGW_HSC4_TBOX_FrP05_oCAN01: start 27, 4 bit, big-endian, init-value=0, base-type=uint8, compu-method=CM_TboxP2PRCHSC4, transfer-property=PENDING, to P2P
          signal P2PExeAvlblHSC4_oGW_HSC4_TBOX_FrP05_oCAN01: start 28, 1 bit, big-endian, init-value=0, base-type=boolean, compu-method=CM_P2PExeAvlblHSC4, transfer-property=PENDING, to P2P
          signal P2PExeAvlblVHSC4_oGW_HSC4_TBOX_FrP05_oCAN01: start 29, 1 bit, big-endian, init-value=0, base-type=boolean, compu-method=CM_P2PExeAvlblVHSC4, transfer-property=PENDING, to P2P
          signal TBOXAccelZHSC4_oGW_HSC4_TBOX_FrP05_oCAN01: start 35, 12 bit, big-endian, init-value=0, base-type=sint16, compu-method=CM_TBOXAccelZHSC4, unit=U_mYs2, transfer-property=PENDING, to P2P
          signal TBOXAccelZVHSC4_oGW_HSC4_TBOX_FrP05_oCAN01: start 36, 1 bit, big-endian, init-value=0, base-type=boolean, compu-method=CM_TBOXAccelZVHSC4, transfer-property=PENDING, to P2P
      frame GW_HSC4_TBOX_FrS10_oCAN01: id 0x611, to P2P, frame-length=8, can-addressing-mode=STANDARD
        pdu GW_HSC4_TBOX_FrS10_oCAN01: length=8, unused-bit-pattern=0
          signal TBOXToIECUCtrlPotclHSC4_oGW_HSC4_TBOX_FrS10_oCAN01: start 0, 64 bit, opaque, init-value=8 x 0, base-type=uint8_8_iso_8859_1, compu-method=CM_TBOXToIECUCtrlPotclHSC4, transfer-property=PENDING, to P2P
      frame GW_HSC4_TC_FrP01_oCAN01: id 0x94, to P2P, frame-length=8, can-addressing-mode=STANDARD
        pdu GW_HSC4_TC_FrP01_oCAN01: length=8, transmission-mode-false-timing=cyclic-timing=time-period=0, transmission-mode-true-timing=cyclic-timing=time-period=0, unused-bit-pattern=0
          signal TMSpd_h1HSC4_oGW_HSC4_TC_FrP01_oCAN01: start 7, 16 bit, big-endian, init-value=32768, base-type=uint16, compu-method=CM_TMSpd_h1HSC4, unit=U_rpm, transfer-property=PENDING, to P2P
          signal TMSpdV_h1HSC4_oGW_HSC4_TC_FrP01_oCAN01: start 23, 1 bit, big-endian, init-value=1, base-type=boolean, compu-method=CM_TMSpdV_h1HSC4, transfer-property=PENDING, to P2P
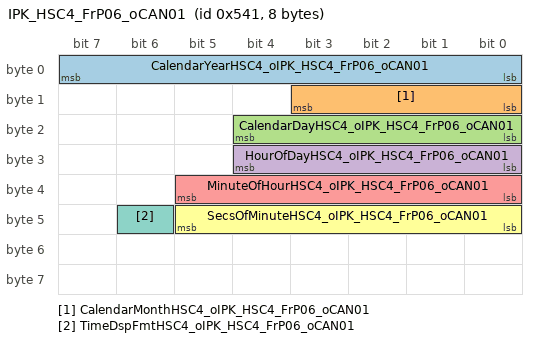
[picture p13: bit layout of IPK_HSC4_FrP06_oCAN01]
      frame IPK_HSC4_FrP06_oCAN01: id 0x541, to P2P, frame-length=8, can-addressing-mode=STANDARD
        pdu IPK_HSC4_FrP06_oCAN01: length=8, transmission-mode-false-timing=cyclic-timing=time-period=0, transmission-mode-true-timing=cyclic-timing=time-period=0, unused-bit-pattern=0
          signal CalendarYearHSC4_oIPK_HSC4_FrP06_oCAN01: start 7, 8 bit, big-endian, init-value=0, base-type=uint8, compu-method=CM_CalendarYearHSC4, unit=U_year, transfer-property=PENDING, to P2P
          signal CalendarMonthHSC4_oIPK_HSC4_FrP06_oCAN01: start 11, 4 bit, big-endian, init-value=0, base-type=uint8, compu-method=CM_CalendarMonthHSC4, transfer-property=PENDING, to P2P
          signal CalendarDayHSC4_oIPK_HSC4_FrP06_oCAN01: start 20, 5 bit, big-endian, init-value=0, base-type=uint8, compu-method=CM_CalendarDayHSC4, unit=U_days, transfer-property=PENDING, to P2P
          signal HourOfDayHSC4_oIPK_HSC4_FrP06_oCAN01: start 28, 5 bit, big-endian, init-value=0, base-type=uint8, compu-method=CM_HourOfDayHSC4, transfer-property=PENDING, to P2P
          signal MinuteOfHourHSC4_oIPK_HSC4_FrP06_oCAN01: start 37, 6 bit, big-endian, init-value=0, base-type=uint8, compu-method=CM_MinuteOfHourHSC4, transfer-property=PENDING, to P2P
          signal SecsOfMinuteHSC4_oIPK_HSC4_FrP06_oCAN01: start 45, 6 bit, big-endian, init-value=0, base-type=uint8, compu-method=CM_SecsOfMinuteHSC4, transfer-property=PENDING, to P2P
          signal TimeDspFmtHSC4_oIPK_HSC4_FrP06_oCAN01: start 46, 1 bit, big-endian, init-value=0, base-type=boolean, compu-method=CM_TimeDspFmtHSC4, transfer-property=PENDING, to P2P
      frame P2P_HSC4_FrP03_oCAN01: id 0x30D, from P2P, frame-length=8, can-addressing-mode=STANDARD
        pdu P2P_HSC4_FrP03_oCAN01: length=8, transmission-mode-false-timing=cyclic-timing=time-period=0, transmission-mode-true-timing=cyclic-timing=time-period=0, unused-bit-pattern=0
          signal P2PACTMdChngTmotHSC4_oP2P_HSC4_FrP03_oCAN01: start 7, 8 bit, big-endian, init-value=0, base-type=uint8, compu-method=CM_P2PACTMdChngTmotHSC4, unit=U_s, transfer-property=PENDING
          signal P2PDisplayHSC4_oP2P_HSC4_FrP03_oCAN01: start 15, 8 bit, big-endian, init-value=0, base-type=uint8, compu-method=CM_P2PDisplayHSC4, transfer-property=PENDING
          signal Route2StateHSC4_oP2P_HSC4_FrP03_oCAN01: start 17, 2 bit, big-endian, init-value=0, base-type=uint8, compu-method=CM_Route2StateHSC4, transfer-property=PENDING
          signal Route1StateHSC4_oP2P_HSC4_FrP03_oCAN01: start 19, 2 bit, big-endian, init-value=0, base-type=uint8, compu-method=CM_Route1StateHSC4, transfer-property=PENDING
          signal P2PProgressHSC4_oP2P_HSC4_FrP03_oCAN01: start 23, 4 bit, big-endian, init-value=0, base-type=uint8, compu-method=CM_P2PProgressHSC4, transfer-property=PENDING
          signal Route1SavePercentageHSC4_oP2P_HSC4_FrP03_oCAN01: start 30, 7 bit, big-endian, init-value=0, base-type=uint8, compu-method=CM_Route1SavePercentageHSC4, transfer-property=PENDING
          signal Route2SavePercentageHSC4_oP2P_HSC4_FrP03_oCAN01: start 38, 7 bit, big-endian, init-value=0, base-type=uint8, compu-method=CM_Route2SavePercentageHSC4, transfer-property=PENDING
      frame P2P_HSC4_FrS01_oCAN01: id 0x60F, from P2P, frame-length=8, can-addressing-mode=STANDARD
        pdu P2P_HSC4_FrS01_oCAN01: length=8, unused-bit-pattern=0
          signal IECUToTBOXCtrlPotclHSC4_oP2P_HSC4_FrS01_oCAN01: start 0, 64 bit, opaque, init-value=8 x 0, base-type=uint8_8_iso_8859_1, compu-method=CM_IECUToTBOXCtrlPotclHSC4, transfer-property=PENDING
      frame P2P_IECU_HSC4_FrP01_oCAN01: id 0x2FC, from P2P, frame-length=8, can-addressing-mode=STANDARD
        pdu P2P_IECU_HSC4_FrP01_oCAN01: length=8, transmission-mode-false-timing=cyclic-timing=time-period=0, transmission-mode-true-timing=cyclic-timing=time-period=0, unused-bit-pattern=0
          signal HD_AVMsysrdyHSC4_oP2P_IECU_HSC4_FrP01_oCAN01: start 40, 1 bit, big-endian, init-value=0, base-type=boolean, compu-method=CM_HD_AVMsysrdyHSC4, transfer-property=PENDING
          signal HD_AVMCurViewHSC4_oP2P_IECU_HSC4_FrP01_oCAN01: start 51, 4 bit, big-endian, init-value=0, base-type=uint8, compu-method=CM_HD_AVMCurViewHSC4, transfer-property=PENDING
          signal HD_AVMVideoFmtStaHSC4_oP2P_IECU_HSC4_FrP01_oCAN01: start 55, 4 bit, big-endian, init-value=0, base-type=uint8, compu-method=CM_HD_AVMVideoFmtStaHSC4, transfer-property=PENDING
          signal HD_AVMErrorDisplay_h4HSC4_oP2P_IECU_HSC4_FrP01_oCAN01: start 59, 4 bit, big-endian, init-value=0, base-type=uint8, compu-method=CM_HD_AVMErrorDisplay_h4HSC4, transfer-property=PENDING
          signal HD_AVMInfoDisplayHSC4_oP2P_IECU_HSC4_FrP01_oCAN01: start 63, 4 bit, big-endian, init-value=0, base-type=uint8, compu-method=CM_HD_AVMInfoDisplayHSC4, transfer-property=PENDING
      frame P2P_IECU_HSC4_FrP02_oCAN01: id 0x390, from P2P, frame-length=8, can-addressing-mode=STANDARD
        pdu P2P_IECU_HSC4_FrP02_oCAN01: length=8, transmission-mode-false-timing=cyclic-timing=time-period=0, transmission-mode-true-timing=cyclic-timing=time-period=0, unused-bit-pattern=0
          signal AutoDrvngSysStsHSC4_oP2P_IECU_HSC4_FrP02_oCAN01: start 23, 8 bit, big-endian, init-value=0, base-type=uint8, compu-method=CM_AutoDrvngSysStsHSC4, unit=U_reserved, transfer-property=PENDING
      frame RDA_HSC4_P02_oCAN01: id 0x204, to P2P, frame-length=8, can-addressing-mode=STANDARD
        pdu RDA_HSC4_P02_oCAN01: length=8, transmission-mode-false-timing=cyclic-timing=time-period=0, transmission-mode-true-timing=cyclic-timing=time-period=0, unused-bit-pattern=0
          signal RRCTAWrnngHSC4_oRDA_HSC4_P02_oCAN01: start 1, 2 bit, big-endian, init-value=0, base-type=uint8, compu-method=CM_RRCTAWrnngHSC4, transfer-property=PENDING, to P2P
          signal LRCTAWrnngHSC4_oRDA_HSC4_P02_oCAN01: start 3, 2 bit, big-endian, init-value=0, base-type=uint8, compu-method=CM_LRCTAWrnngHSC4, transfer-property=PENDING, to P2P
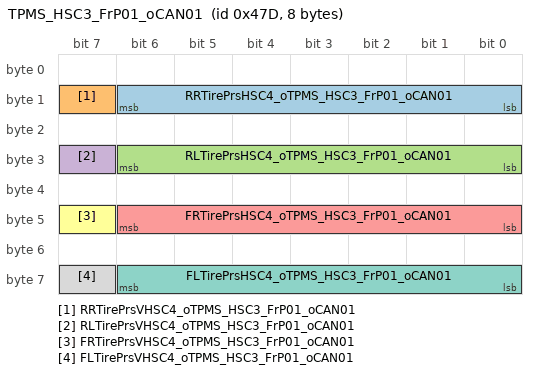
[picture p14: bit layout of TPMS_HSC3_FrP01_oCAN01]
      frame TPMS_HSC3_FrP01_oCAN01: id 0x47D, to P2P, frame-length=8, can-addressing-mode=STANDARD
        pdu TPMS_HSC3_FrP01_oCAN01: length=8, transmission-mode-false-timing=cyclic-timing=time-period=0, transmission-mode-true-timing=cyclic-timing=time-period=0, unused-bit-pattern=0
          signal RRTirePrsHSC4_oTPMS_HSC3_FrP01_oCAN01: start 14, 7 bit, big-endian, init-value=55, base-type=uint8, compu-method=CM_RRTirePrsHSC4, unit=U_kPa, transfer-property=PENDING, to P2P
          signal RRTirePrsVHSC4_oTPMS_HSC3_FrP01_oCAN01: start 15, 1 bit, big-endian, init-value=0, base-type=boolean, compu-method=CM_RRTirePrsVHSC4, transfer-property=PENDING, to P2P
          signal RLTirePrsHSC4_oTPMS_HSC3_FrP01_oCAN01: start 30, 7 bit, big-endian, init-value=55, base-type=uint8, compu-method=CM_RLTirePrsHSC4, unit=U_kPa, transfer-property=PENDING, to P2P
          signal RLTirePrsVHSC4_oTPMS_HSC3_FrP01_oCAN01: start 31, 1 bit, big-endian, init-value=0, base-type=boolean, compu-method=CM_RLTirePrsVHSC4, transfer-property=PENDING, to P2P
          signal FRTirePrsHSC4_oTPMS_HSC3_FrP01_oCAN01: start 46, 7 bit, big-endian, init-value=55, base-type=uint8, compu-method=CM_FRTirePrsHSC4, unit=U_kPa, transfer-property=PENDING, to P2P
          signal FRTirePrsVHSC4_oTPMS_HSC3_FrP01_oCAN01: start 47, 1 bit, big-endian, init-value=0, base-type=boolean, compu-method=CM_FRTirePrsVHSC4, transfer-property=PENDING, to P2P
          signal FLTirePrsHSC4_oTPMS_HSC3_FrP01_oCAN01: start 62, 7 bit, big-endian, init-value=55, base-type=uint8, compu-method=CM_FLTirePrsHSC4, unit=U_kPa, transfer-property=PENDING, to P2P
          signal FLTirePrsVHSC4_oTPMS_HSC3_FrP01_oCAN01: start 63, 1 bit, big-endian, init-value=0, base-type=boolean, compu-method=CM_FLTirePrsVHSC4, transfer-property=PENDING, to P2P
      frame TPMS_HSC3_FrP02_oCAN01: id 0x47E, to P2P, frame-length=8, can-addressing-mode=STANDARD
        pdu TPMS_HSC3_FrP02_oCAN01: length=8, transmission-mode-false-timing=cyclic-timing=time-period=0, transmission-mode-true-timing=cyclic-timing=time-period=0, unused-bit-pattern=0
          signal TPMSFHSC4_oTPMS_HSC3_FrP02_oCAN01: start 0, 1 bit, big-endian, init-value=0, base-type=boolean, compu-method=CM_TPMSFHSC4, transfer-property=PENDING, to P2P
  can cluster CAN02: protocol-name=CAN  # 180319-lh1-EP21P2P_P2P_SecCH-V09
    can physical channel CHNL: comm-connectors=CN_CAN02
      frame APA_SecCH_FrP00_oCAN02: id 0x1A8, to P2P, frame-length=6, can-addressing-mode=STANDARD
        pdu APA_SecCH_FrP00_oCAN02: length=6, transmission-mode-false-timing=cyclic-timing=time-period=0, transmission-mode-true-timing=cyclic-timing=time-period=0, unused-bit-pattern=0
          signal APAToqReqVal_sech2_SecCAN2_oAPA_SecCH_FrP00_oCAN02: start 3, 12 bit, big-endian, init-value=0, base-type=uint16, compu-method=CM_APAToqReqVal_sech2_SecCAN2, unit=U_Nm, transfer-property=PENDING, to P2P
          signal APAToqReqSts_sech2_SecCAN2_oAPA_SecCH_FrP00_oCAN02: start 4, 1 bit, big-endian, init-value=0, base-type=boolean, compu-method=CM_APAToqReqSts_sech2_SecCAN2, transfer-property=PENDING, to P2P
          signal APAF_sech2_SecCAN2_oAPA_SecCH_FrP00_oCAN02: start 5, 1 bit, big-endian, init-value=0, base-type=boolean, compu-method=CM_APAF_sech2_SecCAN2, transfer-property=PENDING, to P2P
          signal APACmdEPSSts_sech2_SecCAN2_oAPA_SecCH_FrP00_oCAN02: start 7, 2 bit, big-endian, init-value=0, base-type=uint8, compu-method=CM_APACmdEPSSts_sech2_SecCAN2, transfer-property=PENDING, to P2P
          signal APATrgtEPSStrgWhlAng_sech2_SecCAN2_oAPA_SecCH_FrP00_oCAN02: start 23, 16 bit, big-endian, init-value=0, base-type=uint16, compu-method=CM_APATrgtEPSStrgWhlAng_sech2_SecCAN2, transfer-property=PENDING, to P2P
          signal APAAlvRC_sech2_SecCAN2_oAPA_SecCH_FrP00_oCAN02: start 39, 8 bit, big-endian, init-value=0, base-type=uint8, compu-method=CM_APAAlvRC_sech2_SecCAN2, transfer-property=PENDING, to P2P
          signal APAChksm_sech2_SecCAN2_oAPA_SecCH_FrP00_oCAN02: start 47, 8 bit, big-endian, init-value=0, base-type=uint8, compu-method=CM_APAChksm_sech2_SecCAN2, transfer-property=PENDING, to P2P
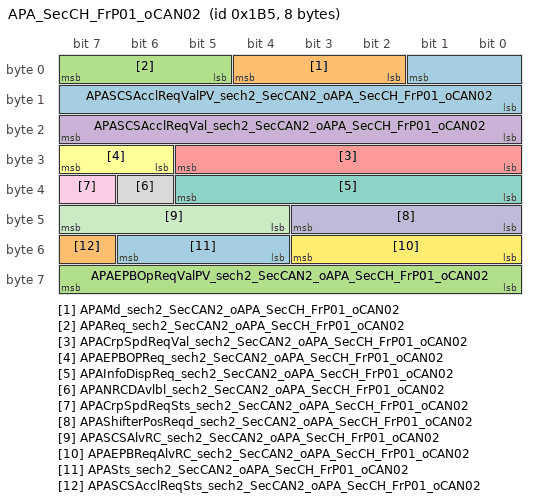
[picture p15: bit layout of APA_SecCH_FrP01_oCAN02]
      frame APA_SecCH_FrP01_oCAN02: id 0x1B5, to P2P, frame-length=8, can-addressing-mode=STANDARD
        pdu APA_SecCH_FrP01_oCAN02: length=8, transmission-mode-false-timing=cyclic-timing=time-period=0, transmission-mode-true-timing=cyclic-timing=time-period=0, unused-bit-pattern=0
          signal APASCSAcclReqValPV_sech2_SecCAN2_oAPA_SecCH_FrP01_oCAN02: start 1, 10 bit, big-endian, init-value=0, base-type=uint16, compu-method=CM_APASCSAcclReqValPV_sech2_SecCAN2, transfer-property=PENDING, to P2P
          signal APAMd_sech2_SecCAN2_oAPA_SecCH_FrP01_oCAN02: start 4, 3 bit, big-endian, init-value=0, base-type=uint8, compu-method=CM_APAMd_sech2_SecCAN2, transfer-property=PENDING, to P2P
          signal APAReq_sech2_SecCAN2_oAPA_SecCH_FrP01_oCAN02: start 7, 3 bit, big-endian, init-value=0, base-type=uint8, compu-method=CM_APAReq_sech2_SecCAN2, transfer-property=PENDING, to P2P
          signal APASCSAcclReqVal_sech2_SecCAN2_oAPA_SecCH_FrP01_oCAN02: start 23, 8 bit, big-endian, init-value=0, base-type=uint8, compu-method=CM_APASCSAcclReqVal_sech2_SecCAN2, unit=U_mYs2, transfer-property=PENDING, to P2P
          signal APACrpSpdReqVal_sech2_SecCAN2_oAPA_SecCH_FrP01_oCAN02: start 29, 6 bit, big-endian, init-value=0, base-type=uint8, compu-method=CM_APACrpSpdReqVal_sech2_SecCAN2, unit=U_kmYh, transfer-property=PENDING, to P2P
          signal APAEPBOPReq_sech2_SecCAN2_oAPA_SecCH_FrP01_oCAN02: start 31, 2 bit, big-endian, init-value=0, base-type=uint8, compu-method=CM_APAEPBOPReq_sech2_SecCAN2, transfer-property=PENDING, to P2P
          signal APAInfoDispReq_sech2_SecCAN2_oAPA_SecCH_FrP01_oCAN02: start 37, 6 bit, big-endian, init-value=0, base-type=uint8, compu-method=CM_APAInfoDispReq_sech2_SecCAN2, transfer-property=PENDING, to P2P
          signal APANRCDAvlbl_sech2_SecCAN2_oAPA_SecCH_FrP01_oCAN02: start 38, 1 bit, big-endian, init-value=0, base-type=boolean, compu-method=CM_APANRCDAvlbl_sech2_SecCAN2, transfer-property=PENDING, to P2P  # Advanced Park Assist Near Range Control Drive Available
          signal APACrpSpdReqSts_sech2_SecCAN2_oAPA_SecCH_FrP01_oCAN02: start 39, 1 bit, big-endian, init-value=0, base-type=boolean, compu-method=CM_APACrpSpdReqSts_sech2_SecCAN2, transfer-property=PENDING, to P2P
          signal APAShifterPosReqd_sech2_SecCAN2_oAPA_SecCH_FrP01_oCAN02: start 43, 4 bit, big-endian, init-value=0, base-type=uint8, compu-method=CM_APAShifterPosReqd_sech2_SecCAN2, transfer-property=PENDING, to P2P
          signal APASCSAlvRC_sech2_SecCAN2_oAPA_SecCH_FrP01_oCAN02: start 47, 4 bit, big-endian, init-value=0, base-type=uint8, compu-method=CM_APASCSAlvRC_sech2_SecCAN2, transfer-property=PENDING, to P2P
          signal APAEPBReqAlvRC_sech2_SecCAN2_oAPA_SecCH_FrP01_oCAN02: start 51, 4 bit, big-endian, init-value=0, base-type=uint8, compu-method=CM_APAEPBReqAlvRC_sech2_SecCAN2, transfer-property=PENDING, to P2P
          signal APASts_sech2_SecCAN2_oAPA_SecCH_FrP01_oCAN02: start 54, 3 bit, big-endian, init-value=0, base-type=uint8, compu-method=CM_APASts_sech2_SecCAN2, transfer-property=PENDING, to P2P
          signal APASCSAcclReqSts_sech2_SecCAN2_oAPA_SecCH_FrP01_oCAN02: start 55, 1 bit, big-endian, init-value=0, base-type=boolean, compu-method=CM_APASCSAcclReqSts_sech2_SecCAN2, transfer-property=PENDING, to P2P
          signal APAEPBOpReqValPV_sech2_SecCAN2_oAPA_SecCH_FrP01_oCAN02: start 63, 8 bit, big-endian, init-value=0, base-type=uint8, compu-method=CM_APAEPBOpReqValPV_sech2_SecCAN2, transfer-property=PENDING, to P2P
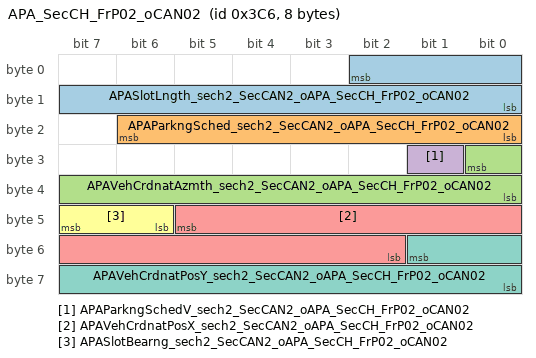
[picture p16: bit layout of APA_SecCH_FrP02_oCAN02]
      frame APA_SecCH_FrP02_oCAN02: id 0x3C6, to P2P, frame-length=8, can-addressing-mode=STANDARD
        pdu APA_SecCH_FrP02_oCAN02: length=8, transmission-mode-false-timing=cyclic-timing=time-period=0, transmission-mode-true-timing=cyclic-timing=time-period=0, unused-bit-pattern=0
          signal APASlotLngth_sech2_SecCAN2_oAPA_SecCH_FrP02_oCAN02: start 2, 11 bit, big-endian, init-value=0, base-type=uint16, compu-method=CM_APASlotLngth_sech2_SecCAN2, unit=U_cm, transfer-property=PENDING, to P2P  # Advanced Park Assist Slot Length
          signal APAParkngSched_sech2_SecCAN2_oAPA_SecCH_FrP02_oCAN02: start 22, 7 bit, big-endian, init-value=0, base-type=uint8, compu-method=CM_APAParkngSched_sech2_SecCAN2, transfer-property=PENDING, to P2P  # Advanced Park Assist Parking Schedule
          signal APAVehCrdnatAzmth_sech2_SecCAN2_oAPA_SecCH_FrP02_oCAN02: start 24, 9 bit, big-endian, init-value=0, base-type=uint16, compu-method=CM_APAVehCrdnatAzmth_sech2_SecCAN2, transfer-property=PENDING, to P2P  # Advanced Park Assist Vehicle Coordinate Azimuth
          signal APAParkngSchedV_sech2_SecCAN2_oAPA_SecCH_FrP02_oCAN02: start 25, 1 bit, big-endian, init-value=0, base-type=boolean, compu-method=CM_APAParkngSchedV_sech2_SecCAN2, transfer-property=PENDING, to P2P  # Advanced Park Assist Parking Schedule Validit
          signal APAVehCrdnatPosX_sech2_SecCAN2_oAPA_SecCH_FrP02_oCAN02: start 45, 12 bit, big-endian, init-value=0, base-type=uint16, compu-method=CM_APAVehCrdnatPosX_sech2_SecCAN2, unit=U_cm, transfer-property=PENDING, to P2P  # Advanced Park Assist Vehicle Coordinate Position X
          signal APASlotBearng_sech2_SecCAN2_oAPA_SecCH_FrP02_oCAN02: start 47, 2 bit, big-endian, init-value=0, base-type=uint8, compu-method=CM_APASlotBearng_sech2_SecCAN2, transfer-property=PENDING, to P2P  # Advanced Park Assist Slot Bearing
          signal APAVehCrdnatPosY_sech2_SecCAN2_oAPA_SecCH_FrP02_oCAN02: start 49, 10 bit, big-endian, init-value=0, base-type=uint16, compu-method=CM_APAVehCrdnatPosY_sech2_SecCAN2, unit=U_cm, transfer-property=PENDING, to P2P  # Advanced Park Assist Vehicle Coordinate Position Y
      frame APA_SecCH_FrP03_oCAN02: id 0x28B, to P2P, frame-length=8, can-addressing-mode=STANDARD
        pdu APA_SecCH_FrP03_oCAN02: length=8, transmission-mode-false-timing=cyclic-timing=time-period=0, transmission-mode-true-timing=cyclic-timing=time-period=0, unused-bit-pattern=0
          signal RRObsDist_sech2_SecCAN2_oAPA_SecCH_FrP03_oCAN02: start 7, 9 bit, big-endian, init-value=0, base-type=uint16, compu-method=CM_RRObsDist_sech2_SecCAN2, transfer-property=PENDING, to P2P
          signal RLObsDist_sech2_SecCAN2_oAPA_SecCH_FrP03_oCAN02: start 14, 9 bit, big-endian, init-value=0, base-type=uint16, compu-method=CM_RLObsDist_sech2_SecCAN2, transfer-property=PENDING, to P2P
          signal FRObsDist_sech2_SecCAN2_oAPA_SecCH_FrP03_oCAN02: start 21, 9 bit, big-endian, init-value=0, base-type=uint16, compu-method=CM_FRObsDist_sech2_SecCAN2, transfer-property=PENDING, to P2P
          signal FLObsDist_sech2_SecCAN2_oAPA_SecCH_FrP03_oCAN02: start 24, 9 bit, big-endian, init-value=0, base-type=uint16, compu-method=CM_FLObsDist_sech2_SecCAN2, transfer-property=PENDING, to P2P
      frame APA_SecCH_FrP04_oCAN02: id 0x28C, to P2P, frame-length=8, can-addressing-mode=STANDARD
        pdu APA_SecCH_FrP04_oCAN02: length=8, transmission-mode-false-timing=cyclic-timing=time-period=0, transmission-mode-true-timing=cyclic-timing=time-period=0, unused-bit-pattern=0
          signal RrMidRObsDist_sech2_SecCAN2_oAPA_SecCH_FrP04_oCAN02: start 7, 9 bit, big-endian, init-value=0, base-type=uint16, compu-method=CM_RrMidRObsDist_sech2_SecCAN2, transfer-property=PENDING, to P2P
          signal RrMidLObsDist_sech2_SecCAN2_oAPA_SecCH_FrP04_oCAN02: start 14, 9 bit, big-endian, init-value=0, base-type=uint16, compu-method=CM_RrMidLObsDist_sech2_SecCAN2, transfer-property=PENDING, to P2P
          signal FrtMidRObsDist_sech2_SecCAN2_oAPA_SecCH_FrP04_oCAN02: start 21, 9 bit, big-endian, init-value=0, base-type=uint16, compu-method=CM_FrtMidRObsDist_sech2_SecCAN2, transfer-property=PENDING, to P2P
          signal FrtMidLObsDist_sech2_SecCAN2_oAPA_SecCH_FrP04_oCAN02: start 24, 9 bit, big-endian, init-value=0, base-type=uint16, compu-method=CM_FrtMidLObsDist_sech2_SecCAN2, transfer-property=PENDING, to P2P
      frame DIAG_DTCInfo_APA_oCAN02: id 0x799, to P2P, frame-length=7, can-addressing-mode=STANDARD
        pdu DIAG_DTCInfo_APA_oCAN02: length=7, unused-bit-pattern=0
          signal DTCInfomationAPA_SecCAN2_oDIAG_DTCInfo_APA_oCAN02: start 0, 56 bit, opaque, init-value=7 x 0, base-type=uint8_7_iso_8859_1, compu-method=CM_DTCInfomationAPA_SecCAN2, transfer-property=PENDING, to P2P  # DTC Infomation of APA The length of DTC information signal is 7 bytes. Byte 0 is MSB (most significant byte), and Byte 6 is LSB (least significant byte). For each byte, Bit 7 is msb (most significant bit), and Bit 0 is lsb (least significant bit). Byte 0: Bit (7-4): DTC Serious Level Bit (3-0): Reserved Byte 1: Bit (7-0): Reserved Byte 2: Bit (7-0): DTCHighByte Byte 3: Bit (7-0): DTCLowByte Byte 4: Bit (7-0): DTCFailureTypeByte Byte 5: Bit 7: warningIndicatorRequested Bit 6: testNotCompletedThisOperationCycle Bit 5: testFailedSinceLastClear Bit 4: testNotCompletedSinceLastClear Bit 3: confirmedDTC Bit 2: pendingDTC Bit 1: testFailedThisOperationCycle Bit 0: testFailed Byte 6: Bit (7-0): DTC Type For more detail, please refer to SMTC 2 800 004.
      frame P2P_SecCH_BCM_FrP03_oCAN02: id 0x47A, from P2P, frame-length=8, can-addressing-mode=STANDARD
        pdu P2P_SecCH_BCM_FrP03_oCAN02: length=8, transmission-mode-false-timing=cyclic-timing=time-period=0, transmission-mode-true-timing=cyclic-timing=time-period=0, unused-bit-pattern=0
          signal TrlrHitchSwA_SecCAN2_oP2P_SecCH_BCM_FrP03_oCAN02: start 15, 1 bit, big-endian, init-value=0, base-type=boolean, compu-method=CM_TrlrHitchSwA_SecCAN2, transfer-property=PENDING
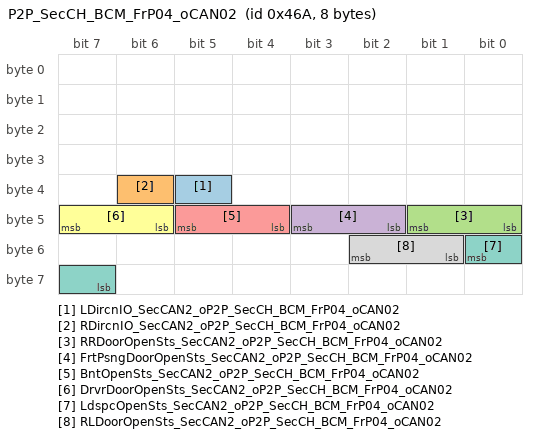
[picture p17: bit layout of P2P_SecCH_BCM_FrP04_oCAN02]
      frame P2P_SecCH_BCM_FrP04_oCAN02: id 0x46A, from P2P, frame-length=8, can-addressing-mode=STANDARD
        pdu P2P_SecCH_BCM_FrP04_oCAN02: length=8, transmission-mode-false-timing=cyclic-timing=time-period=0, transmission-mode-true-timing=cyclic-timing=time-period=0, unused-bit-pattern=0
          signal LDircnIO_SecCAN2_oP2P_SecCH_BCM_FrP04_oCAN02: start 37, 1 bit, big-endian, init-value=0, base-type=boolean, compu-method=CM_LDircnIO_SecCAN2, transfer-property=PENDING
          signal RDircnIO_SecCAN2_oP2P_SecCH_BCM_FrP04_oCAN02: start 38, 1 bit, big-endian, init-value=0, base-type=boolean, compu-method=CM_RDircnIO_SecCAN2, transfer-property=PENDING
          signal RRDoorOpenSts_SecCAN2_oP2P_SecCH_BCM_FrP04_oCAN02: start 41, 2 bit, big-endian, init-value=0, base-type=uint8, compu-method=CM_RRDoorOpenSts_SecCAN2, transfer-property=PENDING  # Rear Right Door Open Status
          signal FrtPsngDoorOpenSts_SecCAN2_oP2P_SecCH_BCM_FrP04_oCAN02: start 43, 2 bit, big-endian, init-value=0, base-type=uint8, compu-method=CM_FrtPsngDoorOpenSts_SecCAN2, transfer-property=PENDING
          signal BntOpenSts_SecCAN2_oP2P_SecCH_BCM_FrP04_oCAN02: start 45, 2 bit, big-endian, init-value=0, base-type=uint8, compu-method=CM_BntOpenSts_SecCAN2, transfer-property=PENDING
          signal DrvrDoorOpenSts_SecCAN2_oP2P_SecCH_BCM_FrP04_oCAN02: start 47, 2 bit, big-endian, init-value=0, base-type=uint8, compu-method=CM_DrvrDoorOpenSts_SecCAN2, transfer-property=PENDING
          signal LdspcOpenSts_SecCAN2_oP2P_SecCH_BCM_FrP04_oCAN02: start 48, 2 bit, big-endian, init-value=0, base-type=uint8, compu-method=CM_LdspcOpenSts_SecCAN2, transfer-property=PENDING
          signal RLDoorOpenSts_SecCAN2_oP2P_SecCH_BCM_FrP04_oCAN02: start 50, 2 bit, big-endian, init-value=0, base-type=uint8, compu-method=CM_RLDoorOpenSts_SecCAN2, transfer-property=PENDING
      frame P2P_SecCH_BCM_FrP07_oCAN02: id 0x1F2, from P2P, frame-length=2, can-addressing-mode=STANDARD
        pdu P2P_SecCH_BCM_FrP07_oCAN02: length=2, transmission-mode-false-timing=cyclic-timing=time-period=0, transmission-mode-true-timing=cyclic-timing=time-period=0, unused-bit-pattern=0
          signal SysBPM_SecCAN2_oP2P_SecCH_BCM_FrP07_oCAN02: start 5, 2 bit, big-endian, init-value=0, base-type=uint8, compu-method=CM_SysBPM_SecCAN2, transfer-property=PENDING
          signal SysBPMEnbd_SecCAN2_oP2P_SecCH_BCM_FrP07_oCAN02: start 6, 1 bit, big-endian, init-value=0, base-type=boolean, compu-method=CM_SysBPMEnbd_SecCAN2, transfer-property=PENDING
      frame P2P_SecCH_ECM_FrP00_oCAN02: id 0xC9, from P2P, frame-length=8, can-addressing-mode=STANDARD
        pdu P2P_SecCH_ECM_FrP00_oCAN02: length=8, transmission-mode-false-timing=cyclic-timing=time-period=0, transmission-mode-true-timing=cyclic-timing=time-period=0, unused-bit-pattern=0
          signal EnRunA_SecCAN2_oP2P_SecCH_ECM_FrP00_oCAN02: start 7, 1 bit, big-endian, init-value=0, base-type=boolean, compu-method=CM_EnRunA_SecCAN2, transfer-property=PENDING
      frame P2P_SecCH_EPB_FrP00_oCAN02: id 0x230, from P2P, frame-length=8, can-addressing-mode=STANDARD
        pdu P2P_SecCH_EPB_FrP00_oCAN02: length=8, transmission-mode-false-timing=cyclic-timing=time-period=0, transmission-mode-true-timing=cyclic-timing=time-period=0, unused-bit-pattern=0
          signal EPBSwStsV_SecCAN2_oP2P_SecCH_EPB_FrP00_oCAN02: start 5, 1 bit, big-endian, init-value=0, base-type=boolean, compu-method=CM_EPBSwStsV_SecCAN2, transfer-property=PENDING
          signal EPBSwSts_SecCAN2_oP2P_SecCH_EPB_FrP00_oCAN02: start 7, 2 bit, big-endian, init-value=0, base-type=uint8, compu-method=CM_EPBSwSts_SecCAN2, transfer-property=PENDING
      frame P2P_SecCH_EPB_FrP01_oCAN02: id 0x22A, from P2P, frame-length=2, can-addressing-mode=STANDARD
        pdu P2P_SecCH_EPB_FrP01_oCAN02: length=2, transmission-mode-false-timing=cyclic-timing=time-period=0, transmission-mode-true-timing=cyclic-timing=time-period=0, unused-bit-pattern=0
          signal EPBAvlblyStsPV_SecCAN2_oP2P_SecCH_EPB_FrP01_oCAN02: start 2, 3 bit, big-endian, init-value=0, base-type=uint8, compu-method=CM_EPBAvlblyStsPV_SecCAN2, transfer-property=PENDING
          signal EPBAvlblySts_SecCAN2_oP2P_SecCH_EPB_FrP01_oCAN02: start 5, 3 bit, big-endian, init-value=0, base-type=uint8, compu-method=CM_EPBAvlblySts_SecCAN2, transfer-property=PENDING
          signal EPBAppcnSts_SecCAN2_oP2P_SecCH_EPB_FrP01_oCAN02: start 15, 2 bit, big-endian, init-value=0, base-type=uint8, compu-method=CM_EPBAppcnSts_SecCAN2, transfer-property=PENDING  # Electric Park Brake Application Status
      frame P2P_SecCH_EPS_FrP02_oCAN02: id 0x1B1, from P2P, frame-length=4, can-addressing-mode=STANDARD
        pdu P2P_SecCH_EPS_FrP02_oCAN02: length=4, transmission-mode-false-timing=cyclic-timing=time-period=0, transmission-mode-true-timing=cyclic-timing=time-period=0, unused-bit-pattern=0
          signal EPSAPASts_SecCAN2_oP2P_SecCH_EPS_FrP02_oCAN02: start 4, 4 bit, big-endian, init-value=7, base-type=uint8, compu-method=CM_EPSAPASts_SecCAN2, unit=U_Reserve, transfer-property=PENDING
          signal EPSAPAInh_SecCAN2_oP2P_SecCH_EPS_FrP02_oCAN02: start 15, 8 bit, big-endian, init-value=0, base-type=uint8, compu-method=CM_EPSAPAInh_SecCAN2, transfer-property=PENDING
          signal EPSAPAAlvRC_SecCAN2_oP2P_SecCH_EPS_FrP02_oCAN02: start 23, 8 bit, big-endian, init-value=0, base-type=uint8, compu-method=CM_EPSAPAAlvRC_SecCAN2, transfer-property=PENDING
          signal EPSAPAChksm_SecCAN2_oP2P_SecCH_EPS_FrP02_oCAN02: start 31, 8 bit, big-endian, init-value=0, base-type=uint8, compu-method=CM_EPSAPAChksm_SecCAN2, transfer-property=PENDING
      frame P2P_SecCH_FICM_FrP02_oCAN02: id 0x376, from P2P, frame-length=8, can-addressing-mode=STANDARD
        pdu P2P_SecCH_FICM_FrP02_oCAN02: length=8, transmission-mode-false-timing=cyclic-timing=time-period=0, transmission-mode-true-timing=cyclic-timing=time-period=0, unused-bit-pattern=0
          signal RstrFctryDeftsReq_SecCAN2_oP2P_SecCH_FICM_FrP02_oCAN02: start 56, 1 bit, big-endian, init-value=0, base-type=boolean, compu-method=CM_RstrFctryDeftsReq_SecCAN2, transfer-property=PENDING
      frame P2P_SecCH_FICM_FrP08_oCAN02: id 0x2F6, from P2P, frame-length=8, can-addressing-mode=STANDARD
        pdu P2P_SecCH_FICM_FrP08_oCAN02: length=8, transmission-mode-false-timing=cyclic-timing=time-period=0, transmission-mode-true-timing=cyclic-timing=time-period=0, unused-bit-pattern=0
          signal APASwReq_SecCAN2_oP2P_SecCH_FICM_FrP08_oCAN02: start 59, 2 bit, big-endian, init-value=0, base-type=uint8, compu-method=CM_APASwReq_SecCAN2, transfer-property=PENDING
          signal PDCSwReq_SecCAN2_oP2P_SecCH_FICM_FrP08_oCAN02: start 61, 2 bit, big-endian, init-value=0, base-type=uint8, compu-method=CM_PDCSwReq_SecCAN2, transfer-property=PENDING
      frame P2P_SecCH_FICM_FrP18_oCAN02: id 0x37D, from P2P, frame-length=8, can-addressing-mode=STANDARD
        pdu P2P_SecCH_FICM_FrP18_oCAN02: length=8, transmission-mode-false-timing=cyclic-timing=time-period=0, transmission-mode-true-timing=cyclic-timing=time-period=0, unused-bit-pattern=0
          signal DrvrSelAPAParkngMd_SecCAN2_oP2P_SecCH_FICM_FrP18_oCAN02: start 0, 3 bit, big-endian, init-value=0, base-type=uint8, compu-method=CM_DrvrSelAPAParkngMd_SecCAN2, transfer-property=PENDING  # Driver Select Advanced Park Assist Parking Mode
          signal DrvrSelAPASlotBearng_SecCAN2_oP2P_SecCH_FICM_FrP18_oCAN02: start 6, 2 bit, big-endian, init-value=0, base-type=uint8, compu-method=CM_DrvrSelAPASlotBearng_SecCAN2, transfer-property=PENDING
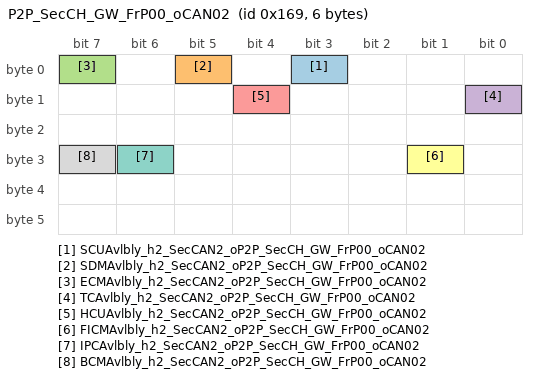
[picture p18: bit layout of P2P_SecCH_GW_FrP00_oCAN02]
      frame P2P_SecCH_GW_FrP00_oCAN02: id 0x169, from P2P, frame-length=6, can-addressing-mode=STANDARD
        pdu P2P_SecCH_GW_FrP00_oCAN02: length=6, transmission-mode-false-timing=cyclic-timing=time-period=0, transmission-mode-true-timing=cyclic-timing=time-period=0, unused-bit-pattern=0
          signal SCUAvlbly_h2_SecCAN2_oP2P_SecCH_GW_FrP00_oCAN02: start 3, 1 bit, big-endian, init-value=0, base-type=boolean, compu-method=CM_SCUAvlbly_h2_SecCAN2, transfer-property=PENDING
          signal SDMAvlbly_h2_SecCAN2_oP2P_SecCH_GW_FrP00_oCAN02: start 5, 1 bit, big-endian, init-value=0, base-type=boolean, compu-method=CM_SDMAvlbly_h2_SecCAN2, transfer-property=PENDING
          signal ECMAvlbly_h2_SecCAN2_oP2P_SecCH_GW_FrP00_oCAN02: start 7, 1 bit, big-endian, init-value=0, base-type=boolean, compu-method=CM_ECMAvlbly_h2_SecCAN2, transfer-property=PENDING
          signal TCAvlbly_h2_SecCAN2_oP2P_SecCH_GW_FrP00_oCAN02: start 8, 1 bit, big-endian, init-value=0, base-type=boolean, compu-method=CM_TCAvlbly_h2_SecCAN2, transfer-property=PENDING  # TC Available Detect if specific ECU is available according to node missing strategy by gateway ECU.
          signal HCUAvlbly_h2_SecCAN2_oP2P_SecCH_GW_FrP00_oCAN02: start 12, 1 bit, big-endian, init-value=0, base-type=boolean, compu-method=CM_HCUAvlbly_h2_SecCAN2, transfer-property=PENDING  # HCU Available Detect if specific ECU is available according to node missing strategy by gateway ECU.
          signal FICMAvlbly_h2_SecCAN2_oP2P_SecCH_GW_FrP00_oCAN02: start 25, 1 bit, big-endian, init-value=0, base-type=boolean, compu-method=CM_FICMAvlbly_h2_SecCAN2, transfer-property=PENDING
          signal IPCAvlbly_h2_SecCAN2_oP2P_SecCH_GW_FrP00_oCAN02: start 30, 1 bit, big-endian, init-value=0, base-type=boolean, compu-method=CM_IPCAvlbly_h2_SecCAN2, transfer-property=PENDING
          signal BCMAvlbly_h2_SecCAN2_oP2P_SecCH_GW_FrP00_oCAN02: start 31, 1 bit, big-endian, init-value=0, base-type=boolean, compu-method=CM_BCMAvlbly_h2_SecCAN2, transfer-property=PENDING
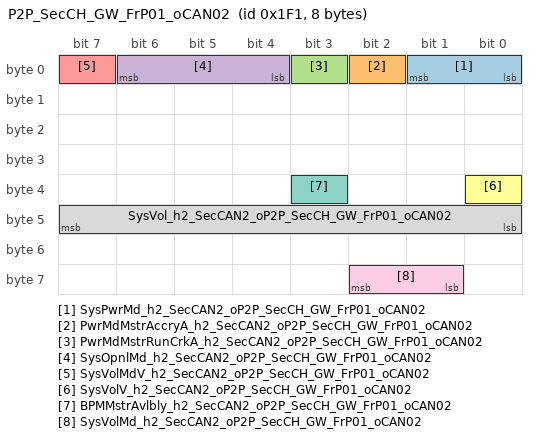
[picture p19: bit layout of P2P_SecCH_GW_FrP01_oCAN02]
      frame P2P_SecCH_GW_FrP01_oCAN02: id 0x1F1, from P2P, frame-length=8, can-addressing-mode=STANDARD
        pdu P2P_SecCH_GW_FrP01_oCAN02: length=8, transmission-mode-false-timing=cyclic-timing=time-period=0, transmission-mode-true-timing=cyclic-timing=time-period=0, unused-bit-pattern=0
          signal SysPwrMd_h2_SecCAN2_oP2P_SecCH_GW_FrP01_oCAN02: start 1, 2 bit, big-endian, init-value=0, base-type=uint8, compu-method=CM_SysPwrMd_h2_SecCAN2, transfer-property=PENDING
          signal PwrMdMstrAccryA_h2_SecCAN2_oP2P_SecCH_GW_FrP01_oCAN02: start 2, 1 bit, big-endian, init-value=0, base-type=boolean, compu-method=CM_PwrMdMstrAccryA_h2_SecCAN2, transfer-property=PENDING
          signal PwrMdMstrRunCrkA_h2_SecCAN2_oP2P_SecCH_GW_FrP01_oCAN02: start 3, 1 bit, big-endian, init-value=0, base-type=boolean, compu-method=CM_PwrMdMstrRunCrkA_h2_SecCAN2, transfer-property=PENDING
          signal SysOpnlMd_h2_SecCAN2_oP2P_SecCH_GW_FrP01_oCAN02: start 6, 3 bit, big-endian, init-value=0, base-type=uint8, compu-method=CM_SysOpnlMd_h2_SecCAN2, transfer-property=PENDING
          signal SysVolMdV_h2_SecCAN2_oP2P_SecCH_GW_FrP01_oCAN02: start 7, 1 bit, big-endian, init-value=0, base-type=boolean, compu-method=CM_SysVolMdV_h2_SecCAN2, transfer-property=PENDING
          signal SysVolV_h2_SecCAN2_oP2P_SecCH_GW_FrP01_oCAN02: start 32, 1 bit, big-endian, init-value=0, base-type=boolean, compu-method=CM_SysVolV_h2_SecCAN2, transfer-property=PENDING
          signal BPMMstrAvlbly_h2_SecCAN2_oP2P_SecCH_GW_FrP01_oCAN02: start 35, 1 bit, big-endian, init-value=0, base-type=boolean, compu-method=CM_BPMMstrAvlbly_h2_SecCAN2, transfer-property=PENDING
          signal SysVol_h2_SecCAN2_oP2P_SecCH_GW_FrP01_oCAN02: start 47, 8 bit, big-endian, init-value=0, base-type=uint8, compu-method=CM_SysVol_h2_SecCAN2, unit=U_V, transfer-property=PENDING
          signal SysVolMd_h2_SecCAN2_oP2P_SecCH_GW_FrP01_oCAN02: start 58, 2 bit, big-endian, init-value=0, base-type=uint8, compu-method=CM_SysVolMd_h2_SecCAN2, transfer-property=PENDING
      frame P2P_SecCH_GW_FrP08_oCAN02: id 0x540, from P2P, frame-length=8, can-addressing-mode=STANDARD
        pdu P2P_SecCH_GW_FrP08_oCAN02: length=8, transmission-mode-false-timing=cyclic-timing=time-period=0, transmission-mode-true-timing=cyclic-timing=time-period=0, unused-bit-pattern=0
          signal VehOdo_h2_SecCAN2_oP2P_SecCH_GW_FrP08_oCAN02: start 7, 24 bit, big-endian, init-value=0, base-type=uint32, compu-method=CM_VehOdo_h2_SecCAN2, transfer-property=PENDING
          signal VehOdoV_h2_SecCAN2_oP2P_SecCH_GW_FrP08_oCAN02: start 31, 1 bit, big-endian, init-value=0, base-type=boolean, compu-method=CM_VehOdoV_h2_SecCAN2, transfer-property=PENDING
      frame P2P_SecCH_GW_FrP10_oCAN02: id 0x3F1, from P2P, frame-length=8, can-addressing-mode=STANDARD
        pdu P2P_SecCH_GW_FrP10_oCAN02: length=8, transmission-mode-false-timing=cyclic-timing=time-period=0, transmission-mode-true-timing=cyclic-timing=time-period=0, unused-bit-pattern=0
          signal OtsdAirTemCrValV_h2_SecCAN2_oP2P_SecCH_GW_FrP10_oCAN02: start 48, 1 bit, big-endian, init-value=0, base-type=boolean, compu-method=CM_OtsdAirTemCrValV_h2_SecCAN2, transfer-property=PENDING
          signal OtsdAirTemCrValMsk_h2_SecCAN2_oP2P_SecCH_GW_FrP10_oCAN02: start 51, 1 bit, big-endian, init-value=0, base-type=boolean, compu-method=CM_OtsdAirTemCrValMsk_h2_SecCAN2, transfer-property=PENDING
          signal OtsdAirTemCrVal_h2_SecCAN2_oP2P_SecCH_GW_FrP10_oCAN02: start 63, 8 bit, big-endian, init-value=0, base-type=uint8, compu-method=CM_OtsdAirTemCrVal_h2_SecCAN2, unit=U_degC, transfer-property=PENDING
      frame P2P_SecCH_GW_FrP13_oCAN02: id 0x1A9, from P2P, frame-length=8, can-addressing-mode=STANDARD
        pdu P2P_SecCH_GW_FrP13_oCAN02: length=8, transmission-mode-false-timing=cyclic-timing=time-period=0, transmission-mode-true-timing=cyclic-timing=time-period=0, unused-bit-pattern=0
          signal NRCDSts_h2_SecCAN2_oP2P_SecCH_GW_FrP13_oCAN02: start 25, 2 bit, big-endian, init-value=0, base-type=uint8, compu-method=CM_NRCDSts_h2_SecCAN2, transfer-property=PENDING
          signal APACtrlAbotdRsn_SecCAN2_oP2P_SecCH_GW_FrP13_oCAN02: start 47, 4 bit, big-endian, init-value=0, base-type=uint8, compu-method=CM_APACtrlAbotdRsn_SecCAN2, transfer-property=PENDING
      frame P2P_SecCH_GW_FrS00_oCAN02: id 0x6A3, from P2P, frame-length=8, can-addressing-mode=STANDARD
        pdu P2P_SecCH_GW_FrS00_oCAN02: length=8, unused-bit-pattern=0
          signal NRCDMstrChlg_h2_SecCAN2_oP2P_SecCH_GW_FrS00_oCAN02: start 0, 64 bit, opaque, init-value=8 x 0, base-type=uint8_8_iso_8859_1, compu-method=CM_NRCDMstrChlg_h2_SecCAN2, transfer-property=PENDING
      frame P2P_SecCH_HCU_ECM_FrP04_oCAN02: id 0x194, from P2P, frame-length=8, can-addressing-mode=STANDARD
        pdu P2P_SecCH_HCU_ECM_FrP04_oCAN02: length=8, transmission-mode-false-timing=cyclic-timing=time-period=0, transmission-mode-true-timing=cyclic-timing=time-period=0, unused-bit-pattern=0
          signal TrShftLvrPos_h1_SecCAN2_oP2P_SecCH_HCU_ECM_FrP04_oCAN02: start 27, 4 bit, big-endian, init-value=0, base-type=uint8, compu-method=CM_TrShftLvrPos_h1_SecCAN2, transfer-property=PENDING
          signal TrShftLvrPosV_h1_SecCAN2_oP2P_SecCH_HCU_ECM_FrP04_oCAN02: start 28, 1 bit, big-endian, init-value=0, base-type=boolean, compu-method=CM_TrShftLvrPosV_h1_SecCAN2, transfer-property=PENDING
      frame P2P_SecCH_HCU_FrP00_oCAN02: id 0xAF, from P2P, frame-length=8, can-addressing-mode=STANDARD
        pdu P2P_SecCH_HCU_FrP00_oCAN02: length=8, transmission-mode-false-timing=cyclic-timing=time-period=0, transmission-mode-true-timing=cyclic-timing=time-period=0, unused-bit-pattern=0
          signal EPTAccelActuPos_SecCAN2_oP2P_SecCH_HCU_FrP00_oCAN02: start 7, 8 bit, big-endian, init-value=0, base-type=uint8, compu-method=CM_EPTAccelActuPos_SecCAN2, unit=U_p, transfer-property=PENDING
          signal EPTBrkPdlDscrtInptStsV_SecCAN2_oP2P_SecCH_HCU_FrP00_oCAN02: start 16, 1 bit, big-endian, init-value=1, base-type=boolean, compu-method=CM_EPTBrkPdlDscrtInptStsV_SecCAN2, transfer-property=PENDING  # Electric Powertrain Brake Pedal Discrete Input Status Validity
          signal EPTStCmdOn_h1_SecCAN2_oP2P_SecCH_HCU_FrP00_oCAN02: start 17, 1 bit, big-endian, init-value=0, base-type=boolean, compu-method=CM_EPTStCmdOn_h1_SecCAN2, transfer-property=PENDING
          signal EPTBrkPdlDscrtInptSts_SecCAN2_oP2P_SecCH_HCU_FrP00_oCAN02: start 31, 1 bit, big-endian, init-value=0, base-type=boolean, compu-method=CM_EPTBrkPdlDscrtInptSts_SecCAN2, transfer-property=PENDING
          signal EPTAccelActuPosV_SecCAN2_oP2P_SecCH_HCU_FrP00_oCAN02: start 43, 1 bit, big-endian, init-value=0, base-type=boolean, compu-method=CM_EPTAccelActuPosV_SecCAN2, transfer-property=PENDING
      frame P2P_SecCH_HCU_FrP01_oCAN02: id 0x196, from P2P, frame-length=8, can-addressing-mode=STANDARD
        pdu P2P_SecCH_HCU_FrP01_oCAN02: length=8, transmission-mode-false-timing=cyclic-timing=time-period=0, transmission-mode-true-timing=cyclic-timing=time-period=0, unused-bit-pattern=0
          signal EPTRdy_h1_SecCAN2_oP2P_SecCH_HCU_FrP01_oCAN02: start 38, 1 bit, big-endian, init-value=0, base-type=boolean, compu-method=CM_EPTRdy_h1_SecCAN2, transfer-property=PENDING
      frame P2P_SecCH_HCU_FrP13_oCAN02: id 0x19C, from P2P, frame-length=8, can-addressing-mode=STANDARD
        pdu P2P_SecCH_HCU_FrP13_oCAN02: length=8, transmission-mode-false-timing=cyclic-timing=time-period=0, transmission-mode-true-timing=cyclic-timing=time-period=0, unused-bit-pattern=0
          signal VCUNRCDAvlbl_SecCAN2_oP2P_SecCH_HCU_FrP13_oCAN02: start 52, 1 bit, big-endian, init-value=0, base-type=boolean, compu-method=CM_VCUNRCDAvlbl_SecCAN2, transfer-property=PENDING
          signal VCUAccReqSts_SecCAN2_oP2P_SecCH_HCU_FrP13_oCAN02: start 53, 1 bit, big-endian, init-value=0, base-type=boolean, compu-method=CM_VCUAccReqSts_SecCAN2, transfer-property=PENDING
          signal VCUAccReqVal_SecCAN2_oP2P_SecCH_HCU_FrP13_oCAN02: start 63, 8 bit, big-endian, init-value=0, base-type=uint8, compu-method=CM_VCUAccReqVal_SecCAN2, transfer-property=PENDING
      frame P2P_SecCH_IPK_FrP06_oCAN02: id 0x541, from P2P, frame-length=8, can-addressing-mode=STANDARD
        pdu P2P_SecCH_IPK_FrP06_oCAN02: length=8, transmission-mode-false-timing=cyclic-timing=time-period=0, transmission-mode-true-timing=cyclic-timing=time-period=0, unused-bit-pattern=0
          signal CalendarYear_SecCAN2_oP2P_SecCH_IPK_FrP06_oCAN02: start 7, 8 bit, big-endian, init-value=0, base-type=uint8, compu-method=CM_CalendarYear_SecCAN2, unit=U_year, transfer-property=PENDING
          signal CalendarMonth_SecCAN2_oP2P_SecCH_IPK_FrP06_oCAN02: start 11, 4 bit, big-endian, init-value=0, base-type=uint8, compu-method=CM_CalendarMonth_SecCAN2, transfer-property=PENDING
          signal CalendarDay_SecCAN2_oP2P_SecCH_IPK_FrP06_oCAN02: start 20, 5 bit, big-endian, init-value=0, base-type=uint8, compu-method=CM_CalendarDay_SecCAN2, unit=U_days, transfer-property=PENDING
          signal HourOfDay_SecCAN2_oP2P_SecCH_IPK_FrP06_oCAN02: start 28, 5 bit, big-endian, init-value=0, base-type=uint8, compu-method=CM_HourOfDay_SecCAN2, transfer-property=PENDING
          signal MinuteOfHour_SecCAN2_oP2P_SecCH_IPK_FrP06_oCAN02: start 37, 6 bit, big-endian, init-value=0, base-type=uint8, compu-method=CM_MinuteOfHour_SecCAN2, transfer-property=PENDING
          signal SecsOfMinute_SecCAN2_oP2P_SecCH_IPK_FrP06_oCAN02: start 45, 6 bit, big-endian, init-value=0, base-type=uint8, compu-method=CM_SecsOfMinute_SecCAN2, transfer-property=PENDING
          signal TimeDspFmt_SecCAN2_oP2P_SecCH_IPK_FrP06_oCAN02: start 46, 1 bit, big-endian, init-value=0, base-type=boolean, compu-method=CM_TimeDspFmt_SecCAN2, transfer-property=PENDING
      frame P2P_SecCH_SAS_FrP00_oCAN02: id 0x1E5, from P2P, frame-length=8, can-addressing-mode=STANDARD
        pdu P2P_SecCH_SAS_FrP00_oCAN02: length=8, transmission-mode-false-timing=cyclic-timing=time-period=0, transmission-mode-true-timing=cyclic-timing=time-period=0, unused-bit-pattern=0
          signal StrgWhlAngV_SecCAN2_oP2P_SecCH_SAS_FrP00_oCAN02: start 7, 1 bit, big-endian, init-value=0, base-type=boolean, compu-method=CM_StrgWhlAngV_SecCAN2, transfer-property=PENDING
          signal StrgWhlAng_SecCAN2_oP2P_SecCH_SAS_FrP00_oCAN02: start 15, 16 bit, big-endian, init-value=0, base-type=uint16, compu-method=CM_StrgWhlAng_SecCAN2, unit=U_degree, transfer-property=PENDING
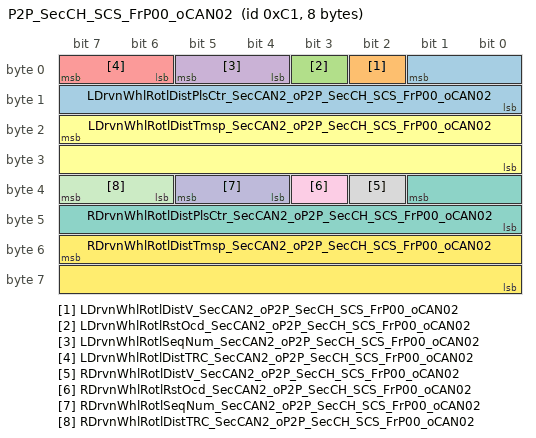
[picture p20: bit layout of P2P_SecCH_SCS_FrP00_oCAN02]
      frame P2P_SecCH_SCS_FrP00_oCAN02: id 0xC1, from P2P, frame-length=8, can-addressing-mode=STANDARD
        pdu P2P_SecCH_SCS_FrP00_oCAN02: length=8, transmission-mode-false-timing=cyclic-timing=time-period=0, transmission-mode-true-timing=cyclic-timing=time-period=0, unused-bit-pattern=0
          signal LDrvnWhlRotlDistPlsCtr_SecCAN2_oP2P_SecCH_SCS_FrP00_oCAN02: start 1, 10 bit, big-endian, init-value=0, base-type=uint16, compu-method=CM_LDrvnWhlRotlDistPlsCtr_SecCAN2, transfer-property=PENDING
          signal LDrvnWhlRotlDistV_SecCAN2_oP2P_SecCH_SCS_FrP00_oCAN02: start 2, 1 bit, big-endian, init-value=0, base-type=boolean, compu-method=CM_LDrvnWhlRotlDistV_SecCAN2, transfer-property=PENDING
          signal LDrvnWhlRotlRstOcd_SecCAN2_oP2P_SecCH_SCS_FrP00_oCAN02: start 3, 1 bit, big-endian, init-value=0, base-type=boolean, compu-method=CM_LDrvnWhlRotlRstOcd_SecCAN2, transfer-property=PENDING
          signal LDrvnWhlRotlSeqNum_SecCAN2_oP2P_SecCH_SCS_FrP00_oCAN02: start 5, 2 bit, big-endian, init-value=0, base-type=uint8, compu-method=CM_LDrvnWhlRotlSeqNum_SecCAN2, transfer-property=PENDING
          signal LDrvnWhlRotlDistTRC_SecCAN2_oP2P_SecCH_SCS_FrP00_oCAN02: start 7, 2 bit, big-endian, init-value=0, base-type=uint8, compu-method=CM_LDrvnWhlRotlDistTRC_SecCAN2, transfer-property=PENDING
          signal LDrvnWhlRotlDistTmsp_SecCAN2_oP2P_SecCH_SCS_FrP00_oCAN02: start 23, 16 bit, big-endian, init-value=0, base-type=uint16, compu-method=CM_LDrvnWhlRotlDistTmsp_SecCAN2, transfer-property=PENDING
          signal RDrvnWhlRotlDistPlsCtr_SecCAN2_oP2P_SecCH_SCS_FrP00_oCAN02: start 33, 10 bit, big-endian, init-value=0, base-type=uint16, compu-method=CM_RDrvnWhlRotlDistPlsCtr_SecCAN2, transfer-property=PENDING
          signal RDrvnWhlRotlDistV_SecCAN2_oP2P_SecCH_SCS_FrP00_oCAN02: start 34, 1 bit, big-endian, init-value=0, base-type=boolean, compu-method=CM_RDrvnWhlRotlDistV_SecCAN2, transfer-property=PENDING
          signal RDrvnWhlRotlRstOcd_SecCAN2_oP2P_SecCH_SCS_FrP00_oCAN02: start 35, 1 bit, big-endian, init-value=0, base-type=boolean, compu-method=CM_RDrvnWhlRotlRstOcd_SecCAN2, transfer-property=PENDING
          signal RDrvnWhlRotlSeqNum_SecCAN2_oP2P_SecCH_SCS_FrP00_oCAN02: start 37, 2 bit, big-endian, init-value=0, base-type=uint8, compu-method=CM_RDrvnWhlRotlSeqNum_SecCAN2, transfer-property=PENDING
          signal RDrvnWhlRotlDistTRC_SecCAN2_oP2P_SecCH_SCS_FrP00_oCAN02: start 39, 2 bit, big-endian, init-value=0, base-type=uint8, compu-method=CM_RDrvnWhlRotlDistTRC_SecCAN2, transfer-property=PENDING
          signal RDrvnWhlRotlDistTmsp_SecCAN2_oP2P_SecCH_SCS_FrP00_oCAN02: start 55, 16 bit, big-endian, init-value=0, base-type=uint16, compu-method=CM_RDrvnWhlRotlDistTmsp_SecCAN2, transfer-property=PENDING
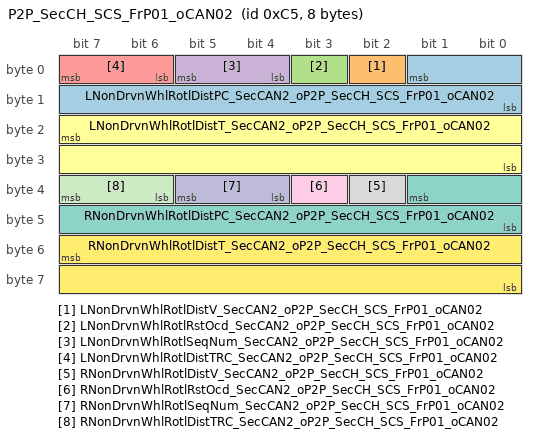
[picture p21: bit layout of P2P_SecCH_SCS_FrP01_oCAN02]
      frame P2P_SecCH_SCS_FrP01_oCAN02: id 0xC5, from P2P, frame-length=8, can-addressing-mode=STANDARD
        pdu P2P_SecCH_SCS_FrP01_oCAN02: length=8, transmission-mode-false-timing=cyclic-timing=time-period=0, transmission-mode-true-timing=cyclic-timing=time-period=0, unused-bit-pattern=0
          signal LNonDrvnWhlRotlDistPC_SecCAN2_oP2P_SecCH_SCS_FrP01_oCAN02: start 1, 10 bit, big-endian, init-value=0, base-type=uint16, compu-method=CM_LNonDrvnWhlRotlDistPC_SecCAN2, transfer-property=PENDING
          signal LNonDrvnWhlRotlDistV_SecCAN2_oP2P_SecCH_SCS_FrP01_oCAN02: start 2, 1 bit, big-endian, init-value=0, base-type=boolean, compu-method=CM_LNonDrvnWhlRotlDistV_SecCAN2, transfer-property=PENDING
          signal LNonDrvnWhlRotlRstOcd_SecCAN2_oP2P_SecCH_SCS_FrP01_oCAN02: start 3, 1 bit, big-endian, init-value=0, base-type=boolean, compu-method=CM_LNonDrvnWhlRotlRstOcd_SecCAN2, transfer-property=PENDING
          signal LNonDrvnWhlRotlSeqNum_SecCAN2_oP2P_SecCH_SCS_FrP01_oCAN02: start 5, 2 bit, big-endian, init-value=0, base-type=uint8, compu-method=CM_LNonDrvnWhlRotlSeqNum_SecCAN2, transfer-property=PENDING
          signal LNonDrvnWhlRotlDistTRC_SecCAN2_oP2P_SecCH_SCS_FrP01_oCAN02: start 7, 2 bit, big-endian, init-value=0, base-type=uint8, compu-method=CM_LNonDrvnWhlRotlDistTRC_SecCAN2, transfer-property=PENDING
          signal LNonDrvnWhlRotlDistT_SecCAN2_oP2P_SecCH_SCS_FrP01_oCAN02: start 23, 16 bit, big-endian, init-value=0, base-type=uint16, compu-method=CM_LNonDrvnWhlRotlDistT_SecCAN2, transfer-property=PENDING
          signal RNonDrvnWhlRotlDistPC_SecCAN2_oP2P_SecCH_SCS_FrP01_oCAN02: start 33, 10 bit, big-endian, init-value=0, base-type=uint16, compu-method=CM_RNonDrvnWhlRotlDistPC_SecCAN2, transfer-property=PENDING
          signal RNonDrvnWhlRotlDistV_SecCAN2_oP2P_SecCH_SCS_FrP01_oCAN02: start 34, 1 bit, big-endian, init-value=0, base-type=boolean, compu-method=CM_RNonDrvnWhlRotlDistV_SecCAN2, transfer-property=PENDING
          signal RNonDrvnWhlRotlRstOcd_SecCAN2_oP2P_SecCH_SCS_FrP01_oCAN02: start 35, 1 bit, big-endian, init-value=0, base-type=boolean, compu-method=CM_RNonDrvnWhlRotlRstOcd_SecCAN2, transfer-property=PENDING
          signal RNonDrvnWhlRotlSeqNum_SecCAN2_oP2P_SecCH_SCS_FrP01_oCAN02: start 37, 2 bit, big-endian, init-value=0, base-type=uint8, compu-method=CM_RNonDrvnWhlRotlSeqNum_SecCAN2, transfer-property=PENDING
          signal RNonDrvnWhlRotlDistTRC_SecCAN2_oP2P_SecCH_SCS_FrP01_oCAN02: start 39, 2 bit, big-endian, init-value=0, base-type=uint8, compu-method=CM_RNonDrvnWhlRotlDistTRC_SecCAN2, transfer-property=PENDING
          signal RNonDrvnWhlRotlDistT_SecCAN2_oP2P_SecCH_SCS_FrP01_oCAN02: start 55, 16 bit, big-endian, init-value=0, base-type=uint16, compu-method=CM_RNonDrvnWhlRotlDistT_SecCAN2, transfer-property=PENDING
      frame P2P_SecCH_SCS_FrP02_oCAN02: id 0x185, from P2P, frame-length=4, can-addressing-mode=STANDARD
        pdu P2P_SecCH_SCS_FrP02_oCAN02: length=4, transmission-mode-false-timing=cyclic-timing=time-period=0, transmission-mode-true-timing=cyclic-timing=time-period=0, unused-bit-pattern=0
          signal VSELongtAcc_SecCAN2_oP2P_SecCH_SCS_FrP02_oCAN02: start 1, 10 bit, big-endian, init-value=0, base-type=sint16, compu-method=CM_VSELongtAcc_SecCAN2, unit=U_mYsX2, transfer-property=PENDING
          signal VSELongtAccV_SecCAN2_oP2P_SecCH_SCS_FrP02_oCAN02: start 2, 1 bit, big-endian, init-value=0, base-type=boolean, compu-method=CM_VSELongtAccV_SecCAN2, transfer-property=PENDING
          signal VSELatAccV_SecCAN2_oP2P_SecCH_SCS_FrP02_oCAN02: start 3, 1 bit, big-endian, init-value=0, base-type=boolean, compu-method=CM_VSELatAccV_SecCAN2, transfer-property=PENDING
          signal VSELatAcc_SecCAN2_oP2P_SecCH_SCS_FrP02_oCAN02: start 19, 12 bit, big-endian, init-value=0, base-type=sint16, compu-method=CM_VSELatAcc_SecCAN2, unit=U_mYsX2, transfer-property=PENDING
      frame P2P_SecCH_SCS_FrP03_oCAN02: id 0x1C7, from P2P, frame-length=8, can-addressing-mode=STANDARD
        pdu P2P_SecCH_SCS_FrP03_oCAN02: length=8, transmission-mode-false-timing=cyclic-timing=time-period=0, transmission-mode-true-timing=cyclic-timing=time-period=0, unused-bit-pattern=0
          signal LNonDrvnWhlRotlDircn_SecCAN2_oP2P_SecCH_SCS_FrP03_oCAN02: start 33, 2 bit, big-endian, init-value=3, base-type=uint8, compu-method=CM_LNonDrvnWhlRotlDircn_SecCAN2, transfer-property=PENDING
          signal RNonDrvnWhlRotlDircn_SecCAN2_oP2P_SecCH_SCS_FrP03_oCAN02: start 35, 2 bit, big-endian, init-value=3, base-type=uint8, compu-method=CM_RNonDrvnWhlRotlDircn_SecCAN2, transfer-property=PENDING
          signal SCSAPAAlvRC_SecCAN2_oP2P_SecCH_SCS_FrP03_oCAN02: start 39, 4 bit, big-endian, init-value=0, base-type=uint8, compu-method=CM_SCSAPAAlvRC_SecCAN2, transfer-property=PENDING
          signal SCSNRCDAvlbl_SecCAN2_oP2P_SecCH_SCS_FrP03_oCAN02: start 45, 1 bit, big-endian, init-value=0, base-type=boolean, compu-method=CM_SCSNRCDAvlbl_SecCAN2, transfer-property=PENDING  # Stability Control System Near Range Control Drive Available
          signal SCSAPAAcclA_SecCAN2_oP2P_SecCH_SCS_FrP03_oCAN02: start 46, 1 bit, big-endian, init-value=0, base-type=boolean, compu-method=CM_SCSAPAAcclA_SecCAN2, transfer-property=PENDING
          signal SCSAPAAvlbl_SecCAN2_oP2P_SecCH_SCS_FrP03_oCAN02: start 47, 1 bit, big-endian, init-value=0, base-type=boolean, compu-method=CM_SCSAPAAvlbl_SecCAN2, transfer-property=PENDING
      frame P2P_SecCH_SCS_FrP05_oCAN02: id 0x1E9, from P2P, frame-length=8, can-addressing-mode=STANDARD
        pdu P2P_SecCH_SCS_FrP05_oCAN02: length=8, transmission-mode-false-timing=cyclic-timing=time-period=0, transmission-mode-true-timing=cyclic-timing=time-period=0, unused-bit-pattern=0
          signal VSESysA_SecCAN2_oP2P_SecCH_SCS_FrP05_oCAN02: start 24, 1 bit, big-endian, init-value=0, base-type=boolean, compu-method=CM_VSESysA_SecCAN2, transfer-property=PENDING
          signal TCSA_SecCAN2_oP2P_SecCH_SCS_FrP05_oCAN02: start 28, 1 bit, big-endian, init-value=0, base-type=boolean, compu-method=CM_TCSA_SecCAN2, transfer-property=PENDING
          signal ABSA_SecCAN2_oP2P_SecCH_SCS_FrP05_oCAN02: start 30, 1 bit, big-endian, init-value=0, base-type=boolean, compu-method=CM_ABSA_SecCAN2, transfer-property=PENDING
          signal VehDynYawRate_SecCAN2_oP2P_SecCH_SCS_FrP05_oCAN02: start 35, 12 bit, big-endian, init-value=0, base-type=sint16, compu-method=CM_VehDynYawRate_SecCAN2, unit=U_degYs, transfer-property=PENDING
          signal VehDynYawRateV_SecCAN2_oP2P_SecCH_SCS_FrP05_oCAN02: start 36, 1 bit, big-endian, init-value=0, base-type=boolean, compu-method=CM_VehDynYawRateV_SecCAN2, transfer-property=PENDING
      frame P2P_SecCH_SCS_FrP11_oCAN02: id 0x348, from P2P, frame-length=8, can-addressing-mode=STANDARD
        pdu P2P_SecCH_SCS_FrP11_oCAN02: length=8, transmission-mode-false-timing=cyclic-timing=time-period=0, transmission-mode-true-timing=cyclic-timing=time-period=0, unused-bit-pattern=0
          signal WhlGndVelLDrvn_SecCAN2_oP2P_SecCH_SCS_FrP11_oCAN02: start 5, 14 bit, big-endian, init-value=0, base-type=uint16, compu-method=CM_WhlGndVelLDrvn_SecCAN2, unit=U_kmYh, transfer-property=PENDING
          signal WhlGndVelLDrvnV_SecCAN2_oP2P_SecCH_SCS_FrP11_oCAN02: start 6, 1 bit, big-endian, init-value=1, base-type=boolean, compu-method=CM_WhlGndVelLDrvnV_SecCAN2, transfer-property=PENDING  # Wheel Ground Velocity Left Driven Validity
          signal WhlGndVelRDrvn_SecCAN2_oP2P_SecCH_SCS_FrP11_oCAN02: start 21, 14 bit, big-endian, init-value=0, base-type=uint16, compu-method=CM_WhlGndVelRDrvn_SecCAN2, unit=U_kmYh, transfer-property=PENDING
          signal WhlGndVelRDrvnV_SecCAN2_oP2P_SecCH_SCS_FrP11_oCAN02: start 22, 1 bit, big-endian, init-value=1, base-type=boolean, compu-method=CM_WhlGndVelRDrvnV_SecCAN2, transfer-property=PENDING  # Wheel Ground Velocity Right Driven Validity
      frame P2P_SecCH_SCS_FrP12_oCAN02: id 0x34A, from P2P, frame-length=8, can-addressing-mode=STANDARD
        pdu P2P_SecCH_SCS_FrP12_oCAN02: length=8, transmission-mode-false-timing=cyclic-timing=time-period=0, transmission-mode-true-timing=cyclic-timing=time-period=0, unused-bit-pattern=0
          signal WhlGndVelLNonDrvn_SecCAN2_oP2P_SecCH_SCS_FrP12_oCAN02: start 5, 14 bit, big-endian, init-value=0, base-type=uint16, compu-method=CM_WhlGndVelLNonDrvn_SecCAN2, unit=U_kmYh, transfer-property=PENDING
          signal WhlGndVelLNonDrvnV_SecCAN2_oP2P_SecCH_SCS_FrP12_oCAN02: start 6, 1 bit, big-endian, init-value=1, base-type=boolean, compu-method=CM_WhlGndVelLNonDrvnV_SecCAN2, transfer-property=PENDING  # Wheel Ground Velocity Left Non Driven Validity
          signal WhlGndVelRNonDrvn_SecCAN2_oP2P_SecCH_SCS_FrP12_oCAN02: start 21, 14 bit, big-endian, init-value=0, base-type=uint16, compu-method=CM_WhlGndVelRNonDrvn_SecCAN2, unit=U_kmYh, transfer-property=PENDING
          signal WhlGndVelRNonDrvnV_SecCAN2_oP2P_SecCH_SCS_FrP12_oCAN02: start 22, 1 bit, big-endian, init-value=1, base-type=boolean, compu-method=CM_WhlGndVelRNonDrvnV_SecCAN2, transfer-property=PENDING  # Wheel Ground Velocity Right Non Driven Validity
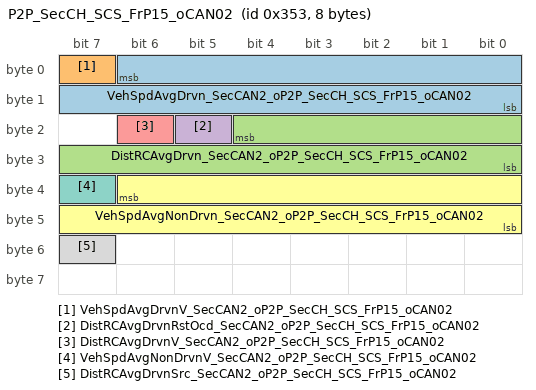
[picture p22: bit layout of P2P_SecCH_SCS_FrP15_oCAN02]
      frame P2P_SecCH_SCS_FrP15_oCAN02: id 0x353, from P2P, frame-length=8, can-addressing-mode=STANDARD
        pdu P2P_SecCH_SCS_FrP15_oCAN02: length=8, transmission-mode-false-timing=cyclic-timing=time-period=0, transmission-mode-true-timing=cyclic-timing=time-period=0, unused-bit-pattern=0
          signal VehSpdAvgDrvn_SecCAN2_oP2P_SecCH_SCS_FrP15_oCAN02: start 6, 15 bit, big-endian, init-value=0, base-type=uint16, compu-method=CM_VehSpdAvgDrvn_SecCAN2, unit=U_kmYh, transfer-property=PENDING
          signal VehSpdAvgDrvnV_SecCAN2_oP2P_SecCH_SCS_FrP15_oCAN02: start 7, 1 bit, big-endian, init-value=0, base-type=boolean, compu-method=CM_VehSpdAvgDrvnV_SecCAN2, transfer-property=PENDING
          signal DistRCAvgDrvn_SecCAN2_oP2P_SecCH_SCS_FrP15_oCAN02: start 20, 13 bit, big-endian, init-value=0, base-type=uint16, compu-method=CM_DistRCAvgDrvn_SecCAN2, unit=U_m, transfer-property=PENDING
          signal DistRCAvgDrvnRstOcd_SecCAN2_oP2P_SecCH_SCS_FrP15_oCAN02: start 21, 1 bit, big-endian, init-value=0, base-type=boolean, compu-method=CM_DistRCAvgDrvnRstOcd_SecCAN2, transfer-property=PENDING
          signal DistRCAvgDrvnV_SecCAN2_oP2P_SecCH_SCS_FrP15_oCAN02: start 22, 1 bit, big-endian, init-value=0, base-type=boolean, compu-method=CM_DistRCAvgDrvnV_SecCAN2, transfer-property=PENDING
          signal VehSpdAvgNonDrvn_SecCAN2_oP2P_SecCH_SCS_FrP15_oCAN02: start 38, 15 bit, big-endian, init-value=0, base-type=uint16, compu-method=CM_VehSpdAvgNonDrvn_SecCAN2, unit=U_kmYh, transfer-property=PENDING
          signal VehSpdAvgNonDrvnV_SecCAN2_oP2P_SecCH_SCS_FrP15_oCAN02: start 39, 1 bit, big-endian, init-value=0, base-type=boolean, compu-method=CM_VehSpdAvgNonDrvnV_SecCAN2, transfer-property=PENDING
          signal DistRCAvgDrvnSrc_SecCAN2_oP2P_SecCH_SCS_FrP15_oCAN02: start 55, 1 bit, big-endian, init-value=0, base-type=boolean, compu-method=CM_DistRCAvgDrvnSrc_SecCAN2, transfer-property=PENDING  # Distance Rolling Count Average Driven Source
      frame P2P_SecCH_SCU_FrP00_oCAN02: id 0x9D, from P2P, frame-length=8, can-addressing-mode=STANDARD
        pdu P2P_SecCH_SCU_FrP00_oCAN02: length=8, transmission-mode-false-timing=cyclic-timing=time-period=0, transmission-mode-true-timing=cyclic-timing=time-period=0, unused-bit-pattern=0
          signal SCUDrvrIntrvnA_SecCAN2_oP2P_SecCH_SCU_FrP00_oCAN02: start 2, 1 bit, big-endian, init-value=0, base-type=boolean, compu-method=CM_SCUDrvrIntrvnA_SecCAN2, transfer-property=PENDING
          signal SCUNRCDAvlbl_SecCAN2_oP2P_SecCH_SCU_FrP00_oCAN02: start 3, 1 bit, big-endian, init-value=0, base-type=boolean, compu-method=CM_SCUNRCDAvlbl_SecCAN2, transfer-property=PENDING
      frame P2P_SecCH_SDM_FrP00_oCAN02: id 0x163, from P2P, frame-length=8, can-addressing-mode=STANDARD
        pdu P2P_SecCH_SDM_FrP00_oCAN02: length=8, transmission-mode-false-timing=cyclic-timing=time-period=0, transmission-mode-true-timing=cyclic-timing=time-period=0, unused-bit-pattern=0
          signal DrvrSbltAtc_SecCAN2_oP2P_SecCH_SDM_FrP00_oCAN02: start 12, 1 bit, big-endian, init-value=0, base-type=boolean, compu-method=CM_DrvrSbltAtc_SecCAN2, transfer-property=PENDING
          signal DrvrSbltAtcV_SecCAN2_oP2P_SecCH_SDM_FrP00_oCAN02: start 13, 1 bit, big-endian, init-value=0, base-type=boolean, compu-method=CM_DrvrSbltAtcV_SecCAN2, transfer-property=PENDING
      frame P2P_SecCH_TC_FrP07_oCAN02: id 0x94, from P2P, frame-length=8, can-addressing-mode=STANDARD
        pdu P2P_SecCH_TC_FrP07_oCAN02: length=8, transmission-mode-false-timing=cyclic-timing=time-period=0, transmission-mode-true-timing=cyclic-timing=time-period=0, unused-bit-pattern=0
          signal TMSpd_h1_SecCAN2_oP2P_SecCH_TC_FrP07_oCAN02: start 7, 16 bit, big-endian, init-value=32768, base-type=uint16, compu-method=CM_TMSpd_h1_SecCAN2, unit=U_rpm, transfer-property=PENDING
          signal TMSpdV_h1_SecCAN2_oP2P_SecCH_TC_FrP07_oCAN02: start 23, 1 bit, big-endian, init-value=1, base-type=boolean, compu-method=CM_TMSpdV_h1_SecCAN2, transfer-property=PENDING
      frame P2P_SecCH_Tester_GW_FrP14_oCAN02: id 0x1AD, from P2P, frame-length=8, can-addressing-mode=STANDARD
        pdu P2P_SecCH_Tester_GW_FrP14_oCAN02: length=8, transmission-mode-false-timing=cyclic-timing=time-period=0, transmission-mode-true-timing=cyclic-timing=time-period=0, unused-bit-pattern=0
          signal NRCDF_SecCAN2_oP2P_SecCH_Tester_GW_FrP14_oCAN02: start 21, 1 bit, big-endian, init-value=0, base-type=boolean, compu-method=CM_NRCDF_SecCAN2, transfer-property=PENDING  # Near Range Control Drive Failed
          signal NRCDAlvRC_SecCAN2_oP2P_SecCH_Tester_GW_FrP14_oCAN02: start 55, 8 bit, big-endian, init-value=0, base-type=uint8, compu-method=CM_NRCDAlvRC_SecCAN2, transfer-property=PENDING  # Near Range Control Drive Alive Rolling Count
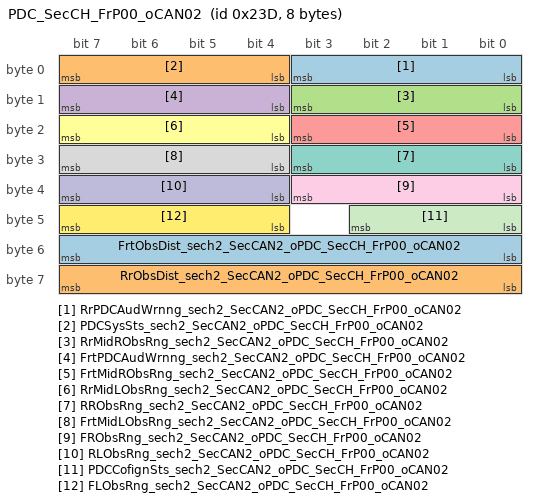
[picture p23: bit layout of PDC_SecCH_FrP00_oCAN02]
      frame PDC_SecCH_FrP00_oCAN02: id 0x23D, to P2P, frame-length=8, can-addressing-mode=STANDARD
        pdu PDC_SecCH_FrP00_oCAN02: length=8, transmission-mode-false-timing=cyclic-timing=time-period=0, transmission-mode-true-timing=cyclic-timing=time-period=0, unused-bit-pattern=0
          signal RrPDCAudWrnng_sech2_SecCAN2_oPDC_SecCH_FrP00_oCAN02: start 3, 4 bit, big-endian, init-value=0, base-type=uint8, compu-method=CM_RrPDCAudWrnng_sech2_SecCAN2, transfer-property=PENDING, to P2P
          signal PDCSysSts_sech2_SecCAN2_oPDC_SecCH_FrP00_oCAN02: start 7, 4 bit, big-endian, init-value=0, base-type=uint8, compu-method=CM_PDCSysSts_sech2_SecCAN2, transfer-property=PENDING, to P2P
          signal RrMidRObsRng_sech2_SecCAN2_oPDC_SecCH_FrP00_oCAN02: start 11, 4 bit, big-endian, init-value=0, base-type=uint8, compu-method=CM_RrMidRObsRng_sech2_SecCAN2, transfer-property=PENDING, to P2P
          signal FrtPDCAudWrnng_sech2_SecCAN2_oPDC_SecCH_FrP00_oCAN02: start 15, 4 bit, big-endian, init-value=0, base-type=uint8, compu-method=CM_FrtPDCAudWrnng_sech2_SecCAN2, transfer-property=PENDING, to P2P
          signal FrtMidRObsRng_sech2_SecCAN2_oPDC_SecCH_FrP00_oCAN02: start 19, 4 bit, big-endian, init-value=0, base-type=uint8, compu-method=CM_FrtMidRObsRng_sech2_SecCAN2, transfer-property=PENDING, to P2P
          signal RrMidLObsRng_sech2_SecCAN2_oPDC_SecCH_FrP00_oCAN02: start 23, 4 bit, big-endian, init-value=0, base-type=uint8, compu-method=CM_RrMidLObsRng_sech2_SecCAN2, transfer-property=PENDING, to P2P
          signal RRObsRng_sech2_SecCAN2_oPDC_SecCH_FrP00_oCAN02: start 27, 4 bit, big-endian, init-value=0, base-type=uint8, compu-method=CM_RRObsRng_sech2_SecCAN2, transfer-property=PENDING, to P2P
          signal FrtMidLObsRng_sech2_SecCAN2_oPDC_SecCH_FrP00_oCAN02: start 31, 4 bit, big-endian, init-value=0, base-type=uint8, compu-method=CM_FrtMidLObsRng_sech2_SecCAN2, transfer-property=PENDING, to P2P
          signal FRObsRng_sech2_SecCAN2_oPDC_SecCH_FrP00_oCAN02: start 35, 4 bit, big-endian, init-value=0, base-type=uint8, compu-method=CM_FRObsRng_sech2_SecCAN2, transfer-property=PENDING, to P2P
          signal RLObsRng_sech2_SecCAN2_oPDC_SecCH_FrP00_oCAN02: start 39, 4 bit, big-endian, init-value=0, base-type=uint8, compu-method=CM_RLObsRng_sech2_SecCAN2, transfer-property=PENDING, to P2P
          signal PDCCofignSts_sech2_SecCAN2_oPDC_SecCH_FrP00_oCAN02: start 42, 3 bit, big-endian, init-value=1, base-type=uint8, compu-method=CM_PDCCofignSts_sech2_SecCAN2, transfer-property=PENDING, to P2P
          signal FLObsRng_sech2_SecCAN2_oPDC_SecCH_FrP00_oCAN02: start 47, 4 bit, big-endian, init-value=0, base-type=uint8, compu-method=CM_FLObsRng_sech2_SecCAN2, transfer-property=PENDING, to P2P
          signal FrtObsDist_sech2_SecCAN2_oPDC_SecCH_FrP00_oCAN02: start 55, 8 bit, big-endian, init-value=0, base-type=uint8, compu-method=CM_FrtObsDist_sech2_SecCAN2, unit=U_cm, transfer-property=PENDING, to P2P
          signal RrObsDist_sech2_SecCAN2_oPDC_SecCH_FrP00_oCAN02: start 63, 8 bit, big-endian, init-value=0, base-type=uint8, compu-method=CM_RrObsDist_sech2_SecCAN2, transfer-property=PENDING, to P2P
      frame PDC_SecCH_FrP01_oCAN02: id 0x237, to P2P, frame-length=8, can-addressing-mode=STANDARD
        pdu PDC_SecCH_FrP01_oCAN02: length=8, transmission-mode-false-timing=cyclic-timing=time-period=0, transmission-mode-true-timing=cyclic-timing=time-period=0, unused-bit-pattern=0
          signal RRSideObsDist_sech2_SecCAN2_oPDC_SecCH_FrP01_oCAN02: start 0, 9 bit, big-endian, init-value=0, base-type=uint16, compu-method=CM_RRSideObsDist_sech2_SecCAN2, transfer-property=PENDING, to P2P
          signal RLSideObsDist_sech2_SecCAN2_oPDC_SecCH_FrP01_oCAN02: start 16, 9 bit, big-endian, init-value=0, base-type=uint16, compu-method=CM_RLSideObsDist_sech2_SecCAN2, transfer-property=PENDING, to P2P
          signal FRSideObsDist_sech2_SecCAN2_oPDC_SecCH_FrP01_oCAN02: start 32, 9 bit, big-endian, init-value=0, base-type=uint16, compu-method=CM_FRSideObsDist_sech2_SecCAN2, transfer-property=PENDING, to P2P
          signal FLSideObsDist_sech2_SecCAN2_oPDC_SecCH_FrP01_oCAN02: start 48, 9 bit, big-endian, init-value=0, base-type=uint16, compu-method=CM_FLSideObsDist_sech2_SecCAN2, transfer-property=PENDING, to P2P
  lin cluster LIN00: baudrate=19200, protocol-name=LIN, protocol-version=2.0
    lin physical channel CHNL: comm-connectors=CN_LIN00
      frame Init_LRU1_oLIN00: id 0xC1, from P2P, frame-length=1, lin-checksum=ENHANCED
        pdu Init_LRU1_oLIN00: length=1, unused-bit-pattern=255
          signal Sin_Init_LRU1_oInit_LRU1_oLIN00: start 0, 8 bit, little-endian, init-value=0, base-type=uint8, compu-method=CM_Sin_Init_LRU1
      frame Init_SRU3_oLIN00: id 0x80, from P2P, frame-length=2, lin-checksum=ENHANCED
        pdu Init_SRU3_oLIN00: length=2, unused-bit-pattern=255
          signal Sig_Init_SRU3_oInit_SRU3_oLIN00: start 0, 16 bit, little-endian, init-value=0, base-type=uint16, compu-method=CM_Sig_Init_SRU3
      frame MasterReq_oLIN00: id 0x3C, from P2P, frame-length=8, lin-checksum=CLASSIC
        n pdu MasterReq_Tp_oLIN00: length=8
      frame Read_LRU1_oLIN00: id 0x1F, to P2P, frame-length=8, lin-checksum=ENHANCED
        pdu Read_LRU1_oLIN00: length=8, unused-bit-pattern=255
          signal TOF_LRU1_oRead_LRU1_oLIN00: start 0, 16 bit, little-endian, init-value=0, base-type=uint16, compu-method=CM_TOF_LRU1, to P2P
          signal Peak_LRU1_oRead_LRU1_oLIN00: start 16, 8 bit, little-endian, init-value=0, base-type=uint8, compu-method=CM_Peak_LRU1, to P2P
          signal Width_LRU1_oRead_LRU1_oLIN00: start 24, 8 bit, little-endian, init-value=0, base-type=uint8, compu-method=CM_Width_LRU1, to P2P
          signal Status_LRU1_oRead_LRU1_oLIN00: start 48, 8 bit, little-endian, init-value=0, base-type=uint8, compu-method=CM_Status_LRU1, to P2P
      frame Read_SRU3_oLIN00: id 0xD, to P2P, frame-length=3, lin-checksum=ENHANCED
        pdu Read_SRU3_oLIN00: length=3, unused-bit-pattern=255
          signal TOF_SRU3_oRead_SRU3_oLIN00: start 0, 16 bit, little-endian, init-value=0, base-type=uint16, compu-method=CM_TOF_SRU3, to P2P
          signal Status_SRU3_oRead_SRU3_oLIN00: start 16, 8 bit, little-endian, init-value=0, base-type=uint8, compu-method=CM_Status_SRU3, to P2P
      frame SlaveResp_oLIN00: id 0x3D, to P2P, frame-length=8, lin-checksum=CLASSIC
        n pdu SlaveResp_Tp_oLIN00: length=8
      pdu triggering PT_MasterReq: pdu=MasterReq_oLIN00, from P2P
      pdu triggering PT_MasterReq_LRU1: pdu=MasterReq_LRU1_oLIN00, from P2P
      pdu triggering PT_MasterReq_SRU3: pdu=MasterReq_SRU3_oLIN00, from P2P
      pdu triggering PT_SlaveResp_LRU1: pdu=SlaveResp_LRU1_oLIN00, to P2P
      pdu triggering PT_SlaveResp_SRU3: pdu=SlaveResp_SRU3_oLIN00, to P2P
      lin schedule table Normal: run-mode=RUN-CONTINUOUS
        table-entrys:
          delay=0.005, position-in-table=0, frame-triggering=FT_Init_SRU3
          delay=0.05, position-in-table=1, frame-triggering=FT_Init_LRU1
          delay=0.02, position-in-table=2, frame-triggering=FT_Read_SRU3
          delay=0.05, position-in-table=3, frame-triggering=FT_Read_LRU1
package /ECU
  ecu instance P2P: associated-com-i-pdu-group=[P2P_oCAN00_Rx, P2P_oCAN00_Tx, P2P_oCAN01_Rx, P2P_oCAN01_Tx, P2P_oCAN02_Rx, P2P_oCAN02_Tx, P2P_oLIN00_Rx, P2P_oLIN00_Tx]
    can communication controller CT_CAN{00..02}
    lin master CT_LIN00: protocol-version=2.0, time-base=0.005, time-base-jitter=0
    can communication connector CN_CAN{00..02}: comm-controller=CT_CAN{00..02}
    lin communication connector CN_LIN00: comm-controller=CT_LIN00
package /Gateway
  gateway P2P: ecu=P2P
package /IPDUGroup
  8 x i signal i pdu group:
    P2P_oCAN00_Rx: communication-direction=IN
      i-signal-i-pdus:
        DIAG_FuncReq_HSC2_oCAN00
        DIAG_PhysReq_P2P_oCAN00
        EHBS_HSC2_FrP00_oCAN00
        EPB_HSC2_FrP00_oCAN00
        EPB_HSC2_FrP01_oCAN00
        EPS_HSC2_FrP02_oCAN00
        GW_HSC2_BCM_FrP04_oCAN00
        GW_HSC2_BCM_FrP06_oCAN00
        GW_HSC2_BCM_FrP07_oCAN00
        GW_HSC2_BCM_FrS16_oCAN00
        GW_HSC2_ECM_FrP04_oCAN00
        GW_HSC2_FICM_FrP02_oCAN00
        GW_HSC2_FICM_FrP08_oCAN00
        GW_HSC2_FrP00_oCAN00
        GW_HSC2_FrP01_oCAN00
        GW_HSC2_FrP08_oCAN00
        GW_HSC2_FrP10_oCAN00
        GW_HSC2_FrP13_oCAN00
        GW_HSC2_FrS00_oCAN00
        GW_HSC2_HCU_FrP00_oCAN00
        GW_HSC2_HCU_FrP01_oCAN00
        GW_HSC2_HCU_FrP13_oCAN00
        GW_HSC2_IPK_FrP06_oCAN00
        GW_HSC2_SCU_FrP00_oCAN00
        GW_HSC2_SDM_FrP00_oCAN00
        SAS_HSC2_FrP00_oCAN00
        SCS_HSC2_FrP{00..03}_oCAN00
        SCS_HSC2_FrP05_oCAN00
        SCS_HSC2_FrP11_oCAN00
        SCS_HSC2_FrP12_oCAN00
        SCS_HSC2_FrP15_oCAN00
        Tester_HSC2_ECM_FrP00_oCAN00
        Tester_HSC2_GW_FrP14_oCAN00
    P2P_oCAN00_Tx: communication-direction=OUT
      i-signal-i-pdus:
        DIAG_DTCInfo_P2P_oCAN00
        DIAG_PhysResp_P2P_oCAN00
        P2P_DIAG_DTCInfo_APA_oCAN00
        P2P_HSC2_FrP{00..04}_oCAN00
        P2P_HSC2_FrS01_oCAN00
    P2P_oCAN01_Rx: communication-direction=IN
      i-signal-i-pdus:
        FICM_HSC4_FrP02_oCAN01
        FICM_HSC4_FrP08_oCAN01
        FICM_HSC4_FrP13_oCAN01
        FICM_HSC4_FrP18_oCAN01
        FICM_HSC4_FrP32_oCAN01
        FICM_HSC4_FrP33_oCAN01
        GW_HSC4_BCM_FrP04_oCAN01
        GW_HSC4_BCM_FrS09_oCAN01
        GW_HSC4_BCM_FrS10_oCAN01
        GW_HSC4_BMS_FrP07_oCAN01
        GW_HSC4_PEPS_FrP01_oCAN01
        GW_HSC4_PEPS_FrP02_oCAN01
        GW_HSC4_TBOX_FrP01_oCAN01
        GW_HSC4_TBOX_FrP05_oCAN01
        GW_HSC4_TBOX_FrS10_oCAN01
        GW_HSC4_TC_FrP01_oCAN01
        IPK_HSC4_FrP06_oCAN01
        RDA_HSC4_P02_oCAN01
        TPMS_HSC3_FrP01_oCAN01
        TPMS_HSC3_FrP02_oCAN01
    P2P_oCAN01_Tx: communication-direction=OUT, i-signal-i-pdus=[P2P_HSC4_FrP03_oCAN01, P2P_HSC4_FrS01_oCAN01, P2P_IECU_HSC4_FrP01_oCAN01, P2P_IECU_HSC4_FrP02_oCAN01]
    P2P_oCAN02_Rx: communication-direction=IN
      i-signal-i-pdus:
        APA_SecCH_FrP{00..04}_oCAN02
        DIAG_DTCInfo_APA_oCAN02
        PDC_SecCH_FrP00_oCAN02
        PDC_SecCH_FrP01_oCAN02
    P2P_oCAN02_Tx: communication-direction=OUT
      i-signal-i-pdus:
        P2P_SecCH_BCM_FrP03_oCAN02
        P2P_SecCH_BCM_FrP04_oCAN02
        P2P_SecCH_BCM_FrP07_oCAN02
        P2P_SecCH_ECM_FrP00_oCAN02
        P2P_SecCH_EPB_FrP00_oCAN02
        P2P_SecCH_EPB_FrP01_oCAN02
        P2P_SecCH_EPS_FrP02_oCAN02
        P2P_SecCH_FICM_FrP02_oCAN02
        P2P_SecCH_FICM_FrP08_oCAN02
        P2P_SecCH_FICM_FrP18_oCAN02
        P2P_SecCH_GW_FrP00_oCAN02
        P2P_SecCH_GW_FrP01_oCAN02
        P2P_SecCH_GW_FrP08_oCAN02
        P2P_SecCH_GW_FrP10_oCAN02
        P2P_SecCH_GW_FrP13_oCAN02
        P2P_SecCH_GW_FrS00_oCAN02
        P2P_SecCH_HCU_ECM_FrP04_oCAN02
        P2P_SecCH_HCU_FrP00_oCAN02
        P2P_SecCH_HCU_FrP01_oCAN02
        P2P_SecCH_HCU_FrP13_oCAN02
        P2P_SecCH_IPK_FrP06_oCAN02
        P2P_SecCH_SAS_FrP00_oCAN02
        P2P_SecCH_SCS_FrP{00..03}_oCAN02
        P2P_SecCH_SCS_FrP05_oCAN02
        P2P_SecCH_SCS_FrP11_oCAN02
        P2P_SecCH_SCS_FrP12_oCAN02
        P2P_SecCH_SCS_FrP15_oCAN02
        P2P_SecCH_SCU_FrP00_oCAN02
        P2P_SecCH_SDM_FrP00_oCAN02
        P2P_SecCH_TC_FrP07_oCAN02
        P2P_SecCH_Tester_GW_FrP14_oCAN02
    P2P_oLIN00_Rx: communication-direction=IN, i-signal-i-pdus=[Read_LRU1_oLIN00, Read_SRU3_oLIN00]
    P2P_oLIN00_Tx: communication-direction=OUT, i-signal-i-pdus=[Init_LRU1_oLIN00, Init_SRU3_oLIN00]
package /PDU
  dcm i pdu MasterReq_LRU1_oLIN00: length=8, diag-pdu-type=DIAG-REQUEST
  dcm i pdu MasterReq_oLIN00: length=8, diag-pdu-type=DIAG-REQUEST
  dcm i pdu MasterReq_SRU3_oLIN00: length=8, diag-pdu-type=DIAG-REQUEST
  dcm i pdu SlaveResp_LRU1_oLIN00: length=8, diag-pdu-type=DIAG-RESPONSE
  dcm i pdu SlaveResp_SRU3_oLIN00: length=8, diag-pdu-type=DIAG-RESPONSE
